VERSION ""

NS_ :

BS_:

BU_: Receiver ChassisBus VehicleBus PartyBus apb ui app aps bms gtwu odin cc cmp cp das dif dir di epas3p epas3s epbl epbr esp fc gtw hvp ibst ocs1p park pcs pmf pmr pm ptc radc rcm2 rcm sccm scm scs tas tpms umc vcfront vcleft vcright vcsec GTW

BO_ 12 ID00CUI_status: 8 VehicleBus
 SG_ UI_audioActive : 1|1@1+ (1,0) [0|1] ""  Receiver
 SG_ UI_autopilotTrial : 12|2@1+ (1,0) [0|3] ""  Receiver
 SG_ UI_bluetoothActive : 2|1@1+ (1,0) [0|1] ""  Receiver
 SG_ UI_cameraActive : 41|1@1+ (1,0) [0|1] ""  Receiver
 SG_ UI_cellActive : 3|1@1+ (1,0) [0|1] ""  Receiver
 SG_ UI_cellConnected : 10|1@1+ (1,0) [0|1] ""  Receiver
 SG_ UI_cellNetworkTechnology : 19|4@1+ (1,0) [0|15] ""  Receiver
 SG_ UI_cellReceiverPower : 24|8@1+ (1,-128) [-128|127] "dB"  Receiver
 SG_ UI_cellSignalBars : 42|3@1+ (1,0) [0|7] ""  Receiver
 SG_ UI_cpuTemperature : 56|8@1- (1,40) [-20|100] "C"  Receiver
 SG_ UI_developmentCar : 40|1@1+ (1,0) [0|1] ""  Receiver
 SG_ UI_displayOn : 5|1@1+ (1,0) [0|1] ""  Receiver
 SG_ UI_displayReady : 4|1@1+ (1,0) [0|1] ""  Receiver
 SG_ UI_factoryReset : 14|2@1+ (1,0) [0|3] ""  Receiver
 SG_ UI_falseTouchCounter : 32|8@1+ (1,0) [0|255] "1"  Receiver
 SG_ UI_gpsActive : 16|1@1+ (1,0) [0|1] ""  Receiver
 SG_ UI_pcbTemperature : 48|8@1- (1,40) [-20|100] "C"  Receiver
 SG_ UI_radioActive : 18|1@1+ (1,0) [0|1] ""  Receiver
 SG_ UI_readyForDrive : 9|1@1+ (1,0) [0|1] ""  Receiver
 SG_ UI_screenshotActive : 17|1@1+ (1,0) [0|1] ""  Receiver
 SG_ UI_systemActive : 8|1@1+ (1,0) [0|1] ""  Receiver
 SG_ UI_touchActive : 0|1@1+ (1,0) [0|1] ""  Receiver
 SG_ UI_vpnActive : 11|1@1+ (1,0) [0|1] ""  Receiver
 SG_ UI_wifiActive : 6|1@1+ (1,0) [0|1] ""  Receiver
 SG_ UI_wifiConnected : 7|1@1+ (1,0) [0|1] ""  Receiver

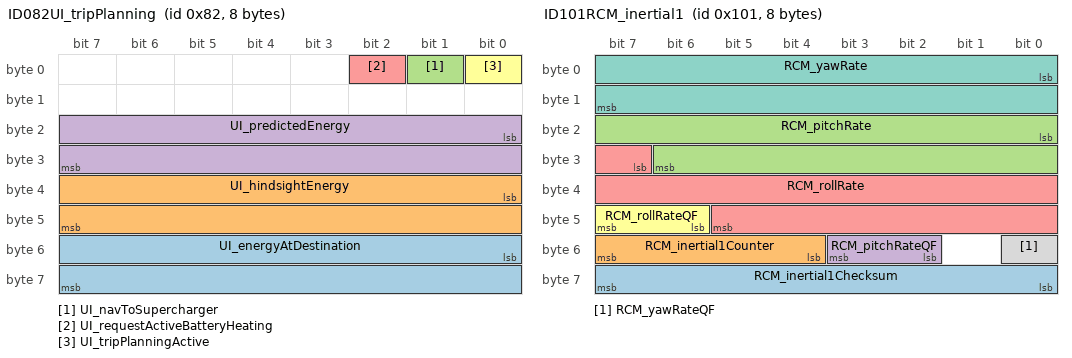
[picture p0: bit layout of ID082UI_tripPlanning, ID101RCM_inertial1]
BO_ 130 ID082UI_tripPlanning: 8 VehicleBus
 SG_ UI_energyAtDestination : 48|16@1- (0.01,0) [-327.67|327.67] "kWh"  Receiver
 SG_ UI_hindsightEnergy : 32|16@1- (0.01,0) [-327.67|327.67] "kWh"  Receiver
 SG_ UI_navToSupercharger : 1|1@1+ (1,0) [0|1] ""  Receiver
 SG_ UI_predictedEnergy : 16|16@1- (0.01,0) [-327.67|327.67] "kWh"  Receiver
 SG_ UI_requestActiveBatteryHeating : 2|1@1+ (1,0) [0|1] ""  Receiver
 SG_ UI_tripPlanningActive : 0|1@1+ (1,0) [0|1] ""  Receiver

BO_ 257 ID101RCM_inertial1: 8 ChassisBus
 SG_ RCM_inertial1Checksum : 56|8@1+ (1,0) [0|255] ""  Receiver
 SG_ RCM_inertial1Counter : 52|4@1+ (1,0) [0|15] ""  Receiver
 SG_ RCM_pitchRate : 16|15@1- (0.00025,0) [-4.096|4.09575] "rad/s"  Receiver
 SG_ RCM_pitchRateQF : 50|2@1+ (1,0) [0|3] ""  Receiver
 SG_ RCM_rollRate : 31|15@1- (0.00025,0) [-4.096|4.09575] "rad/s"  Receiver
 SG_ RCM_rollRateQF : 46|2@1+ (1,0) [0|3] ""  Receiver
 SG_ RCM_yawRate : 0|16@1- (0.0001,0) [-3.2766|3.2766] "rad/s"  Receiver
 SG_ RCM_yawRateQF : 48|1@1+ (1,0) [0|1] ""  Receiver

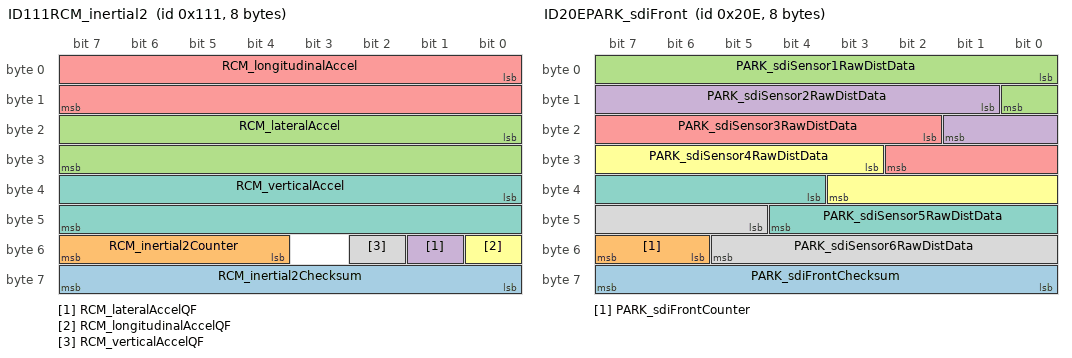
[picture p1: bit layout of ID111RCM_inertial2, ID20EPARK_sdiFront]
BO_ 273 ID111RCM_inertial2: 8 ChassisBus
 SG_ RCM_inertial2Checksum : 56|8@1+ (1,0) [0|255] ""  Receiver
 SG_ RCM_inertial2Counter : 52|4@1+ (1,0) [0|15] ""  Receiver
 SG_ RCM_lateralAccel : 16|16@1- (0.00125,0) [-40.9575|40.9575] "m/s^2"  Receiver
 SG_ RCM_lateralAccelQF : 49|1@1+ (1,0) [0|1] ""  Receiver
 SG_ RCM_longitudinalAccel : 0|16@1- (0.00125,0) [-40.9575|40.9575] "m/s^2"  Receiver
 SG_ RCM_longitudinalAccelQF : 48|1@1+ (1,0) [0|1] ""  Receiver
 SG_ RCM_verticalAccel : 32|16@1- (0.00125,0) [-40.9575|40.9575] "m/s^2"  Receiver
 SG_ RCM_verticalAccelQF : 50|1@1+ (1,0) [0|1] ""  Receiver

BO_ 258 ID102VCLEFT_doorStatus: 8 VehicleBus
 SG_ VCLEFT_frontHandlePWM : 16|7@1+ (1,0) [0|100] "%"  Receiver
 SG_ VCLEFT_frontHandlePulled : 10|1@1+ (1,0) [0|1] ""  Receiver
 SG_ VCLEFT_frontHandlePulledPersist : 62|1@1+ (1,0) [0|1] ""  Receiver
 SG_ VCLEFT_frontIntSwitchPressed : 31|1@1+ (1,0) [0|1] ""  Receiver
 SG_ VCLEFT_frontLatchStatus : 0|4@1+ (1,0) [0|8] ""  Receiver
 SG_ VCLEFT_frontLatchSwitch : 8|1@1+ (1,0) [0|1] ""  Receiver
 SG_ VCLEFT_frontRelActuatorSwitch : 12|1@1+ (1,0) [0|1] ""  Receiver
 SG_ VCLEFT_mirrorDipped : 61|1@1+ (1,0) [0|1] ""  Receiver
 SG_ VCLEFT_mirrorFoldState : 52|3@1+ (1,0) [0|4] ""  Receiver
 SG_ VCLEFT_mirrorHeatState : 58|3@1+ (1,0) [0|4] ""  Receiver
 SG_ VCLEFT_mirrorRecallState : 55|3@1+ (1,0) [0|5] ""  Receiver
 SG_ VCLEFT_mirrorState : 49|3@1+ (1,0) [0|4] ""  Receiver
 SG_ VCLEFT_mirrorTiltXPosition : 33|8@1+ (0.02,0) [0|5] "V"  Receiver
 SG_ VCLEFT_mirrorTiltYPosition : 41|8@1+ (0.02,0) [0|5] "V"  Receiver
 SG_ VCLEFT_rearHandlePWM : 24|7@1+ (1,0) [0|100] "%"  Receiver
 SG_ VCLEFT_rearHandlePulled : 11|1@1+ (1,0) [0|1] ""  Receiver
 SG_ VCLEFT_rearIntSwitchPressed : 32|1@1+ (1,0) [0|1] ""  Receiver
 SG_ VCLEFT_rearLatchStatus : 4|4@1+ (1,0) [0|8] ""  Receiver
 SG_ VCLEFT_rearLatchSwitch : 9|1@1+ (1,0) [0|1] ""  Receiver
 SG_ VCLEFT_rearRelActuatorSwitch : 13|1@1+ (1,0) [0|1] ""  Receiver

BO_ 259 ID103VCRIGHT_doorStatus: 8 VehicleBus
 SG_ VCRIGHT_frontHandlePWM : 14|7@1+ (1,0) [0|100] "%"  Receiver
 SG_ VCRIGHT_frontHandlePulled : 10|1@1+ (1,0) [0|1] ""  Receiver
 SG_ VCRIGHT_frontHandlePulledPersist : 30|1@1+ (1,0) [0|1] ""  Receiver
 SG_ VCRIGHT_frontIntSwitchPressed : 31|1@1+ (1,0) [0|1] ""  Receiver
 SG_ VCRIGHT_frontLatchStatus : 0|4@1+ (1,0) [0|8] ""  Receiver
 SG_ VCRIGHT_frontLatchSwitch : 8|1@1+ (1,0) [0|1] ""  Receiver
 SG_ VCRIGHT_frontRelActuatorSwitch : 12|1@1+ (1,0) [0|1] ""  Receiver
 SG_ VCRIGHT_mirrorDipped : 63|1@1+ (1,0) [0|1] ""  Receiver
 SG_ VCRIGHT_mirrorFoldState : 52|3@1+ (1,0) [0|4] ""  Receiver
 SG_ VCRIGHT_mirrorRecallState : 60|3@1+ (1,0) [0|5] ""  Receiver
 SG_ VCRIGHT_mirrorState : 49|3@1+ (1,0) [0|4] ""  Receiver
 SG_ VCRIGHT_mirrorTiltXPosition : 33|8@1+ (0.02,0) [0|5] "V"  Receiver
 SG_ VCRIGHT_mirrorTiltYPosition : 41|8@1+ (0.02,0) [0|5] "V"  Receiver
 SG_ VCRIGHT_rearHandlePWM : 21|7@1+ (1,0) [0|100] "%"  Receiver
 SG_ VCRIGHT_rearHandlePulled : 11|1@1+ (1,0) [0|1] ""  Receiver
 SG_ VCRIGHT_rearIntSwitchPressed : 32|1@1+ (1,0) [0|1] ""  Receiver
 SG_ VCRIGHT_rearLatchStatus : 4|4@1+ (1,0) [0|8] ""  Receiver
 SG_ VCRIGHT_rearLatchSwitch : 9|1@1+ (1,0) [0|1] ""  Receiver
 SG_ VCRIGHT_rearRelActuatorSwitch : 13|1@1+ (1,0) [0|1] ""  Receiver
 SG_ VCRIGHT_reservedForBackCompat : 28|2@1+ (1,0) [0|3] ""  Receiver
 SG_ VCRIGHT_trunkLatchStatus : 56|4@1+ (1,0) [0|8] ""  Receiver

BO_ 291 ID123UI_alertMatrix1: 8 VehicleBus
 SG_ UI_a001_DriverDoorOpen : 0|1@1+ (1,0) [0|1] ""  Receiver
 SG_ UI_a002_DoorOpen : 1|1@1+ (1,0) [0|1] ""  Receiver
 SG_ UI_a003_TrunkOpen : 2|1@1+ (1,0) [0|1] ""  Receiver
 SG_ UI_a004_FrunkOpen : 3|1@1+ (1,0) [0|1] ""  Receiver
 SG_ UI_a005_HeadlightsOnDoorOpen : 4|1@1+ (1,0) [0|1] ""  Receiver
 SG_ UI_a006_RemoteServiceAlert : 5|1@1+ (1,0) [0|1] ""  Receiver
 SG_ UI_a007_SoftPackConfigMismatch : 6|1@1+ (1,0) [0|1] ""  Receiver
 SG_ UI_a008_TouchScreenError : 7|1@1+ (1,0) [0|1] ""  Receiver
 SG_ UI_a009_SquashfsError : 8|1@1+ (1,0) [0|1] ""  Receiver
 SG_ UI_a010_MapsMissing : 9|1@1+ (1,0) [0|1] ""  Receiver
 SG_ UI_a011_IncorrectMap : 10|1@1+ (1,0) [0|1] ""  Receiver
 SG_ UI_a012_NotOnPrivateProperty : 11|1@1+ (1,0) [0|1] ""  Receiver
 SG_ UI_a013_TPMSHardWarning : 12|1@1+ (1,0) [0|1] ""  Receiver
 SG_ UI_a014_TPMSSoftWarning : 13|1@1+ (1,0) [0|1] ""  Receiver
 SG_ UI_a015_TPMSOverPressureWarning : 14|1@1+ (1,0) [0|1] ""  Receiver
 SG_ UI_a016_TPMSTemperatureWarning : 15|1@1+ (1,0) [0|1] ""  Receiver
 SG_ UI_a017_TPMSSystemFault : 16|1@1+ (1,0) [0|1] ""  Receiver
 SG_ UI_a018_SlipStartOn : 17|1@1+ (1,0) [0|1] ""  Receiver
 SG_ UI_a019_ParkBrakeFault : 18|1@1+ (1,0) [0|1] ""  Receiver
 SG_ UI_a020_SteeringReduced : 19|1@1+ (1,0) [0|1] ""  Receiver
 SG_ UI_a021_RearSeatbeltUnbuckled : 20|1@1+ (1,0) [0|1] ""  Receiver
 SG_ UI_a022_ApeFusesEtc : 21|1@1+ (1,0) [0|1] ""  Receiver
 SG_ UI_a023_CellInternetCheckFailed : 22|1@1+ (1,0) [0|1] ""  Receiver
 SG_ UI_a024_WifiInternetCheckFailed : 23|1@1+ (1,0) [0|1] ""  Receiver
 SG_ UI_a025_WifiOnlineCheckFailed : 24|1@1+ (1,0) [0|1] ""  Receiver
 SG_ UI_a026_ModemResetLoopDetected : 25|1@1+ (1,0) [0|1] ""  Receiver
 SG_ UI_a027_AutoSteerMIA : 26|1@1+ (1,0) [0|1] ""  Receiver
 SG_ UI_a028_FrontTrunkPopupClosed : 27|1@1+ (1,0) [0|1] ""  Receiver
 SG_ UI_a029_ModemMIA : 28|1@1+ (1,0) [0|1] ""  Receiver
 SG_ UI_a030_ModemVMCrash : 29|1@1+ (1,0) [0|1] ""  Receiver
 SG_ UI_a031_BrakeFluidLow : 30|1@1+ (1,0) [0|1] ""  Receiver
 SG_ UI_a032_CellModemRecoveryResets : 31|1@1+ (1,0) [0|1] ""  Receiver
 SG_ UI_a033_ApTrialExpired : 32|1@1+ (1,0) [0|1] ""  Receiver
 SG_ UI_a034_WakeupProblem : 33|1@1+ (1,0) [0|1] ""  Receiver
 SG_ UI_a035_AudioWatchdogKernelError : 34|1@1+ (1,0) [0|1] ""  Receiver
 SG_ UI_a036_AudioWatchdogHfpError : 35|1@1+ (1,0) [0|1] ""  Receiver
 SG_ UI_a037_AudioWatchdogXrunStormEr : 36|1@1+ (1,0) [0|1] ""  Receiver
 SG_ UI_a038_AudioWatchdogA2bI2cLocku : 37|1@1+ (1,0) [0|1] ""  Receiver
 SG_ UI_a039_AudioA2bNeedRediscovery : 38|1@1+ (1,0) [0|1] ""  Receiver
 SG_ UI_a040_HomelinkTransmit : 39|1@1+ (1,0) [0|1] ""  Receiver
 SG_ UI_a041_AudioDmesgXrun : 40|1@1+ (1,0) [0|1] ""  Receiver
 SG_ UI_a042_AudioDmesgRtThrottling : 41|1@1+ (1,0) [0|1] ""  Receiver
 SG_ UI_a043_InvalidMapDataOverride : 42|1@1+ (1,0) [0|1] ""  Receiver
 SG_ UI_a044_AudioDmesgDspException : 43|1@1+ (1,0) [0|1] ""  Receiver
 SG_ UI_a045_ECallNeedsService : 44|1@1+ (1,0) [0|1] ""  Receiver
 SG_ UI_a046_BackupCameraStreamError : 45|1@1+ (1,0) [0|1] ""  Receiver
 SG_ UI_a047_CellRoamingDisallowed : 46|1@1+ (1,0) [0|1] ""  Receiver
 SG_ UI_a048_AudioPremiumAmpCheckFail : 47|1@1+ (1,0) [0|1] ""  Receiver
 SG_ UI_a049_BrakeShiftRequired : 48|1@1+ (1,0) [0|1] ""  Receiver
 SG_ UI_a050_BackupCameraIPUTimeout : 49|1@1+ (1,0) [0|1] ""  Receiver
 SG_ UI_a051_BackupCameraFrameTimeout : 50|1@1+ (1,0) [0|1] ""  Receiver
 SG_ UI_a052_KernelPanicReported : 51|1@1+ (1,0) [0|1] ""  Receiver
 SG_ UI_a053_QtCarExitError : 52|1@1+ (1,0) [0|1] ""  Receiver
 SG_ UI_a054_AudioBoostPowerBad : 53|1@1+ (1,0) [0|1] ""  Receiver
 SG_ UI_a055_ManualECallDisabled : 54|1@1+ (1,0) [0|1] ""  Receiver
 SG_ UI_a056_ManualECallButtonDisconn : 55|1@1+ (1,0) [0|1] ""  Receiver
 SG_ UI_a057_CellAntennaDisconnected : 56|1@1+ (1,0) [0|1] ""  Receiver
 SG_ UI_a058_GPSAntennaDisconnected : 57|1@1+ (1,0) [0|1] ""  Receiver
 SG_ UI_a059_ECallSpeakerDisconnected : 58|1@1+ (1,0) [0|1] ""  Receiver
 SG_ UI_a060_ECallMicDisconnected : 59|1@1+ (1,0) [0|1] ""  Receiver
 SG_ UI_a061_SIMTestFailed : 60|1@1+ (1,0) [0|1] ""  Receiver
 SG_ UI_a062_ENSTestFailed : 61|1@1+ (1,0) [0|1] ""  Receiver
 SG_ UI_a063_CellularTestFailed : 62|1@1+ (1,0) [0|1] ""  Receiver
 SG_ UI_a064_ModemFirmwareTestFailed : 63|1@1+ (1,0) [0|1] ""  Receiver

BO_ 322 ID142VCLEFT_liftgateStatus: 8 VehicleBus
 SG_ VCLEFT_liftgateStatusIndex M : 0|2@1+ (1,0) [0|2] ""  Receiver
 SG_ VCLEFT_liftgateLatchRequest m0 : 61|3@1+ (1,0) [0|4] ""  Receiver
 SG_ VCLEFT_liftgateMvmntNotAllowedCo m0 : 14|3@1+ (1,0) [0|5] ""  Receiver
 SG_ VCLEFT_liftgatePhysicalChimeRequ m0 : 21|3@1+ (1,0) [0|4] ""  Receiver
 SG_ VCLEFT_liftgatePosition m1 : 21|7@1- (1,33) [-5|70] "deg"  Receiver
 SG_ VCLEFT_liftgatePositionCalibrate m0 : 17|1@1+ (1,0) [0|1] ""  Receiver
 SG_ VCLEFT_liftgateRequestSource m0 : 7|3@1+ (1,0) [0|7] ""  Receiver
 SG_ VCLEFT_liftgateSpeed m1 : 28|10@1- (0.1,0) [-30|30] "deg/s"  Receiver
 SG_ VCLEFT_liftgateState m0 : 3|4@1+ (1,0) [0|12] ""  Receiver
 SG_ VCLEFT_liftgateStoppingCondition m0 : 10|4@1+ (1,0) [0|11] ""  Receiver
 SG_ VCLEFT_liftgateStrutCurrent m1 : 11|10@1- (0.1,0) [-30|30] "A"  Receiver
 SG_ VCLEFT_liftgateStrutDutyCycle m1 : 3|8@1- (1,0) [-100|100] "%"  Receiver
 SG_ VCLEFT_liftgateUIChimeRequest m0 : 18|3@1+ (1,0) [0|4] ""  Receiver

BO_ 325 ID145ESP_status: 8 ChassisBus
 SG_ ESP_absBrakeEvent2 : 22|2@1+ (1,0) [0|3] ""  Receiver
 SG_ ESP_absFaultLamp : 17|1@1+ (1,0) [0|1] ""  Receiver
 SG_ ESP_brakeApply : 31|1@1+ (1,0) [0|1] ""  Receiver
 SG_ ESP_brakeDiscWipingActive : 28|1@1+ (1,0) [0|1] ""  Receiver
 SG_ ESP_brakeLamp : 21|1@1+ (1,0) [0|1] ""  Receiver
 SG_ ESP_brakeTorqueTarget : 51|13@1+ (2,0) [0|16382] "Nm"  Receiver
 SG_ ESP_btcTargetState : 38|2@1+ (1,0) [0|3] ""  Receiver
 SG_ ESP_cdpStatus : 34|2@1+ (1,0) [0|3] ""  Receiver
 SG_ ESP_driverBrakeApply : 29|2@1+ (1,0) [0|3] ""  Receiver
 SG_ ESP_ebdFaultLamp : 16|1@1+ (1,0) [0|1] ""  Receiver
 SG_ ESP_ebrStandstillSkid : 48|1@1+ (1,0) [0|1] ""  Receiver
 SG_ ESP_ebrStatus : 49|2@1+ (1,0) [0|3] ""  Receiver
 SG_ ESP_espFaultLamp : 18|1@1+ (1,0) [0|1] ""  Receiver
 SG_ ESP_espLampFlash : 20|1@1+ (1,0) [0|1] ""  Receiver
 SG_ ESP_espModeActive : 12|2@1+ (1,0) [0|3] ""  Receiver
 SG_ ESP_hydraulicBoostEnabled : 19|1@1+ (1,0) [0|1] ""  Receiver
 SG_ ESP_lateralAccelQF : 25|1@1+ (1,0) [0|1] ""  Receiver
 SG_ ESP_longitudinalAccelQF : 24|1@1+ (1,0) [0|1] ""  Receiver
 SG_ ESP_ptcTargetState : 36|2@1+ (1,0) [0|3] ""  Receiver
 SG_ ESP_stabilityControlSts2 : 14|2@1+ (1,0) [0|3] ""  Receiver
 SG_ ESP_statusChecksum : 0|8@1+ (1,0) [0|255] ""  Receiver
 SG_ ESP_statusCounter : 8|4@1+ (1,0) [0|15] ""  Receiver
 SG_ ESP_steeringAngleQF : 27|1@1+ (1,0) [0|1] ""  Receiver
 SG_ ESP_yawRateQF : 26|1@1+ (1,0) [0|1] ""  Receiver

BO_ 522 ID20AHVP_contactorState: 6 VehicleBus
 SG_ HVP_dcLinkAllowedToEnergize : 36|1@1+ (1,0) [0|1] ""  Receiver
 SG_ HVP_fcContNegativeAuxOpen : 7|1@1+ (1,0) [0|1] ""  Receiver
 SG_ HVP_fcContNegativeState : 12|3@1+ (1,0) [0|7] ""  Receiver
 SG_ HVP_fcContPositiveAuxOpen : 6|1@1+ (1,0) [0|1] ""  Receiver
 SG_ HVP_fcContPositiveState : 16|3@1+ (1,0) [0|7] ""  Receiver
 SG_ HVP_fcContactorSetState : 19|4@1+ (1,0) [0|9] ""  Receiver
 SG_ HVP_fcCtrsClosingAllowed : 29|1@1+ (1,0) [0|1] ""  Receiver
 SG_ HVP_fcCtrsOpenNowRequested : 27|1@1+ (1,0) [0|1] ""  Receiver
 SG_ HVP_fcCtrsOpenRequested : 28|1@1+ (1,0) [0|1] ""  Receiver
 SG_ HVP_fcCtrsRequestStatus : 24|2@1+ (1,0) [0|2] ""  Receiver
 SG_ HVP_fcCtrsResetRequestRequired : 26|1@1+ (1,0) [0|1] ""  Receiver
 SG_ HVP_fcLinkAllowedToEnergize : 44|2@1+ (1,0) [0|2] ""  Receiver
 SG_ HVP_hvilStatus : 40|4@1+ (1,0) [0|9] ""  Receiver
 SG_ HVP_packContNegativeState : 0|3@1+ (1,0) [0|7] ""  Receiver
 SG_ HVP_packContPositiveState : 3|3@1+ (1,0) [0|7] ""  Receiver
 SG_ HVP_packContactorSetState : 8|4@1+ (1,0) [0|9] ""  Receiver
 SG_ HVP_packCtrsClosingAllowed : 35|1@1+ (1,0) [0|1] ""  Receiver
 SG_ HVP_packCtrsOpenNowRequested : 33|1@1+ (1,0) [0|1] ""  Receiver
 SG_ HVP_packCtrsOpenRequested : 34|1@1+ (1,0) [0|1] ""  Receiver
 SG_ HVP_packCtrsRequestStatus : 30|2@1+ (1,0) [0|2] ""  Receiver
 SG_ HVP_packCtrsResetRequestRequired : 32|1@1+ (1,0) [0|1] ""  Receiver
 SG_ HVP_pyroTestInProgress : 37|1@1+ (1,0) [0|1] ""  Receiver

BO_ 526 ID20EPARK_sdiFront: 8 ChassisBus
 SG_ PARK_sdiFrontChecksum : 56|8@1+ (1,0) [0|255] ""  Receiver
 SG_ PARK_sdiFrontCounter : 54|2@1+ (1,0) [0|3] ""  Receiver
 SG_ PARK_sdiSensor1RawDistData : 0|9@1+ (1,0) [0|511] "cm"  Receiver
 SG_ PARK_sdiSensor2RawDistData : 9|9@1+ (1,0) [0|511] "cm"  Receiver
 SG_ PARK_sdiSensor3RawDistData : 18|9@1+ (1,0) [0|511] "cm"  Receiver
 SG_ PARK_sdiSensor4RawDistData : 27|9@1+ (1,0) [0|511] "cm"  Receiver
 SG_ PARK_sdiSensor5RawDistData : 36|9@1+ (1,0) [0|511] "cm"  Receiver
 SG_ PARK_sdiSensor6RawDistData : 45|9@1+ (1,0) [0|511] "cm"  Receiver

BO_ 537 ID219VCSEC_TPMSData: 5 ChassisBus
 SG_ VCSEC_TPMSDataIndex M : 0|2@1+ (1,0) [0|3] ""  Receiver
 SG_ VCSEC_TPMSBatVoltage0 m0 : 24|8@1+ (0.01,1.5) [1.5|4.04] "V"  Receiver
 SG_ VCSEC_TPMSBatVoltage1 m1 : 24|8@1+ (0.01,1.5) [1.5|4.04] "V"  Receiver
 SG_ VCSEC_TPMSBatVoltage2 m2 : 24|8@1+ (0.01,1.5) [1.5|4.04] "V"  Receiver
 SG_ VCSEC_TPMSBatVoltage3 m3 : 24|8@1+ (0.01,1.5) [1.5|4.04] "V"  Receiver
 SG_ VCSEC_TPMSLocation0 m0 : 32|3@1+ (1,0) [0|4] ""  Receiver
 SG_ VCSEC_TPMSLocation1 m1 : 32|3@1+ (1,0) [0|4] ""  Receiver
 SG_ VCSEC_TPMSLocation2 m2 : 32|3@1+ (1,0) [0|4] ""  Receiver
 SG_ VCSEC_TPMSLocation3 m3 : 32|3@1+ (1,0) [0|4] ""  Receiver
 SG_ VCSEC_TPMSPressure0 m0 : 8|8@1+ (0.025,0) [0|6.35] "bar"  Receiver
 SG_ VCSEC_TPMSPressure1 m1 : 8|8@1+ (0.025,0) [0|6.35] "bar"  Receiver
 SG_ VCSEC_TPMSPressure2 m2 : 8|8@1+ (0.025,0) [0|6.35] "bar"  Receiver
 SG_ VCSEC_TPMSPressure3 m3 : 8|8@1+ (0.025,0) [0|6.35] "bar"  Receiver
 SG_ VCSEC_TPMSTemperature0 m0 : 16|8@1+ (1,-40) [-40|214] "C"  Receiver
 SG_ VCSEC_TPMSTemperature1 m1 : 16|8@1+ (1,-40) [-40|214] "C"  Receiver
 SG_ VCSEC_TPMSTemperature2 m2 : 16|8@1+ (1,-40) [-40|214] "C"  Receiver
 SG_ VCSEC_TPMSTemperature3 m3 : 16|8@1+ (1,-40) [-40|214] "C"  Receiver

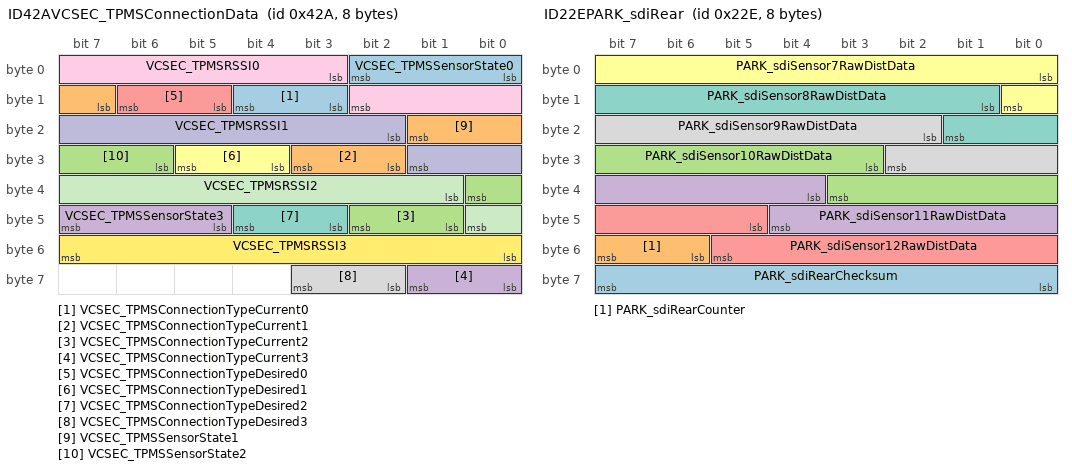
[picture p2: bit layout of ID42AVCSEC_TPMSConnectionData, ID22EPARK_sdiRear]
BO_ 1066 ID42AVCSEC_TPMSConnectionData: 8 VehicleBus
 SG_ VCSEC_TPMSConnectionTypeCurrent0 : 11|2@1+ (1,0) [0|2] ""  Receiver
 SG_ VCSEC_TPMSConnectionTypeCurrent1 : 26|2@1+ (1,0) [0|2] ""  Receiver
 SG_ VCSEC_TPMSConnectionTypeCurrent2 : 41|2@1+ (1,0) [0|2] ""  Receiver
 SG_ VCSEC_TPMSConnectionTypeCurrent3 : 56|2@1+ (1,0) [0|2] ""  Receiver
 SG_ VCSEC_TPMSConnectionTypeDesired0 : 13|2@1+ (1,0) [0|2] ""  Receiver
 SG_ VCSEC_TPMSConnectionTypeDesired1 : 28|2@1+ (1,0) [0|2] ""  Receiver
 SG_ VCSEC_TPMSConnectionTypeDesired2 : 43|2@1+ (1,0) [0|2] ""  Receiver
 SG_ VCSEC_TPMSConnectionTypeDesired3 : 58|2@1+ (1,0) [0|2] ""  Receiver
 SG_ VCSEC_TPMSRSSI0 : 3|8@1- (1,0) [-127|0] "dBm"  Receiver
 SG_ VCSEC_TPMSRSSI1 : 18|8@1- (1,0) [-127|0] "dBm"  Receiver
 SG_ VCSEC_TPMSRSSI2 : 33|8@1- (1,0) [-127|0] "dBm"  Receiver
 SG_ VCSEC_TPMSRSSI3 : 48|8@1- (1,0) [-127|0] "dBm"  Receiver
 SG_ VCSEC_TPMSSensorState0 : 0|3@1+ (1,0) [0|4] ""  Receiver
 SG_ VCSEC_TPMSSensorState1 : 15|3@1+ (1,0) [0|4] ""  Receiver
 SG_ VCSEC_TPMSSensorState2 : 30|3@1+ (1,0) [0|4] ""  Receiver
 SG_ VCSEC_TPMSSensorState3 : 45|3@1+ (1,0) [0|4] ""  Receiver

BO_ 558 ID22EPARK_sdiRear: 8 VehicleBus
 SG_ PARK_sdiRearChecksum : 56|8@1+ (1,0) [0|255] ""  Receiver
 SG_ PARK_sdiRearCounter : 54|2@1+ (1,0) [0|3] ""  Receiver
 SG_ PARK_sdiSensor10RawDistData : 27|9@1+ (1,0) [0|511] "cm"  Receiver
 SG_ PARK_sdiSensor11RawDistData : 36|9@1+ (1,0) [0|511] "cm"  Receiver
 SG_ PARK_sdiSensor12RawDistData : 45|9@1+ (1,0) [0|511] "cm"  Receiver
 SG_ PARK_sdiSensor7RawDistData : 0|9@1+ (1,0) [0|511] "cm"  Receiver
 SG_ PARK_sdiSensor8RawDistData : 9|9@1+ (1,0) [0|511] "cm"  Receiver
 SG_ PARK_sdiSensor9RawDistData : 18|9@1+ (1,0) [0|511] "cm"  Receiver

BO_ 568 ID238UI_driverAssistMapData: 8 ChassisBus
 SG_ UI_acceptBottsDots : 48|1@1+ (1,0) [0|1] ""  Receiver
 SG_ UI_autosteerRestricted : 49|1@1+ (1,0) [0|1] ""  Receiver
 SG_ UI_controlledAccess : 37|1@1+ (1,0) [0|1] ""  Receiver
 SG_ UI_countryCode : 16|10@1+ (1,0) [0|1023] ""  Receiver
 SG_ UI_gpsRoadMatch : 28|1@1+ (1,0) [0|1] ""  Receiver
 SG_ UI_inSuperchargerGeofence : 6|1@1+ (1,0) [0|1] ""  Receiver
 SG_ UI_mapDataChecksum : 56|8@1+ (1,0) [0|255] ""  Receiver
 SG_ UI_mapDataCounter : 52|4@1+ (1,0) [0|15] ""  Receiver
 SG_ UI_mapSpeedLimit : 8|5@1+ (1,0) [0|31] ""  Receiver
 SG_ UI_mapSpeedLimitDependency : 0|3@1+ (1,0) [0|7] ""  Receiver
 SG_ UI_mapSpeedLimitType : 13|3@1+ (1,0) [0|7] ""  Receiver
 SG_ UI_mapSpeedUnits : 7|1@1+ (1,0) [0|1] ""  Receiver
 SG_ UI_navRouteActive : 29|1@1+ (1,0) [0|1] ""  Receiver
 SG_ UI_nextBranchDist : 32|5@1+ (10,0) [0|300] "m"  Receiver
 SG_ UI_nextBranchLeftOffRamp : 38|1@1+ (1,0) [0|1] ""  Receiver
 SG_ UI_nextBranchRightOffRamp : 39|1@1+ (1,0) [0|1] ""  Receiver
 SG_ UI_parallelAutoparkEnabled : 30|1@1+ (1,0) [0|1] ""  Receiver
 SG_ UI_perpendicularAutoparkEnabled : 31|1@1+ (1,0) [0|1] ""  Receiver
 SG_ UI_pmmEnabled : 50|1@1+ (1,0) [0|1] ""  Receiver
 SG_ UI_rejectAutosteer : 46|1@1+ (1,0) [0|1] ""  Receiver
 SG_ UI_rejectHPP : 42|1@1+ (1,0) [0|1] ""  Receiver
 SG_ UI_rejectHandsOn : 47|1@1+ (1,0) [0|1] ""  Receiver
 SG_ UI_rejectLeftFreeSpace : 44|1@1+ (1,0) [0|1] ""  Receiver
 SG_ UI_rejectLeftLane : 40|1@1+ (1,0) [0|1] ""  Receiver
 SG_ UI_rejectNav : 43|1@1+ (1,0) [0|1] ""  Receiver
 SG_ UI_rejectRightFreeSpace : 45|1@1+ (1,0) [0|1] ""  Receiver
 SG_ UI_rejectRightLane : 41|1@1+ (1,0) [0|1] ""  Receiver
 SG_ UI_roadClass : 3|3@1+ (1,0) [0|6] ""  Receiver
 SG_ UI_scaEnabled : 51|1@1+ (1,0) [0|1] ""  Receiver
 SG_ UI_streetCount : 26|2@1+ (1,0) [0|3] ""  Receiver

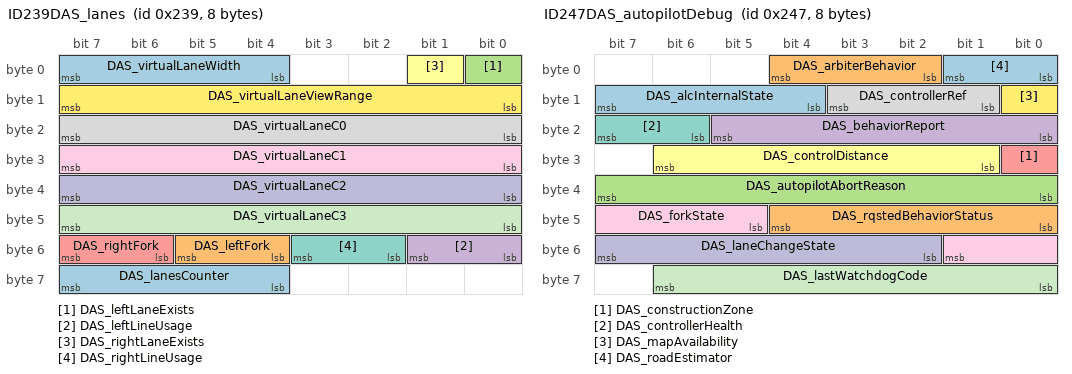
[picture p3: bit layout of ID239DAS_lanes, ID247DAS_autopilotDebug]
BO_ 569 ID239DAS_lanes: 8 ChassisBus
 SG_ DAS_lanesCounter : 60|4@1+ (1,0) [0|15] ""  Receiver
 SG_ DAS_leftFork : 52|2@1+ (1,0) [0|3] ""  Receiver
 SG_ DAS_leftLaneExists : 0|1@1+ (1,0) [0|1] ""  Receiver
 SG_ DAS_leftLineUsage : 48|2@1+ (1,0) [0|3] ""  Receiver
 SG_ DAS_rightFork : 54|2@1+ (1,0) [0|3] ""  Receiver
 SG_ DAS_rightLaneExists : 1|1@1+ (1,0) [0|1] ""  Receiver
 SG_ DAS_rightLineUsage : 50|2@1+ (1,0) [0|3] ""  Receiver
 SG_ DAS_virtualLaneC0 : 16|8@1+ (0.035,-3.5) [-3.5|3.5] "m"  Receiver
 SG_ DAS_virtualLaneC1 : 24|8@1+ (0.0016,-0.2) [-0.2|0.2] "rad"  Receiver
 SG_ DAS_virtualLaneC2 : 32|8@1+ (2E-005,-0.0025) [-0.0025|0.0025] "m-1"  Receiver
 SG_ DAS_virtualLaneC3 : 40|8@1+ (2.4E-007,-3E-005) [-3E-005|3E-005] "m-2"  Receiver
 SG_ DAS_virtualLaneViewRange : 8|8@1+ (1,0) [0|160] "m"  Receiver
 SG_ DAS_virtualLaneWidth : 4|4@1+ (0.3125,2) [2|6.6875] "m"  Receiver

BO_ 583 ID247DAS_autopilotDebug: 8 VehicleBus
 SG_ DAS_alcInternalState : 12|4@1+ (1,0) [0|12] ""  Receiver
 SG_ DAS_arbiterBehavior : 2|3@1+ (1,0) [0|4] ""  Receiver
 SG_ DAS_autopilotAbortReason : 32|8@1+ (1,0) [0|255] ""  Receiver
 SG_ DAS_behaviorReport : 16|6@1+ (1,0) [1|43] ""  Receiver
 SG_ DAS_constructionZone : 24|1@1+ (1,0) [0|1] ""  Receiver
 SG_ DAS_controlDistance : 25|6@1+ (2,0) [0|126] "m"  Receiver
 SG_ DAS_controllerHealth : 22|2@1+ (1,0) [0|3] ""  Receiver
 SG_ DAS_controllerRef : 9|3@1+ (1,0) [0|6] ""  Receiver
 SG_ DAS_forkState : 45|5@1+ (1,0) [0|27] ""  Receiver
 SG_ DAS_laneChangeState : 50|6@1+ (1,0) [0|63] ""  Receiver
 SG_ DAS_lastWatchdogCode : 56|7@1+ (1,0) [0|80] ""  Receiver
 SG_ DAS_mapAvailability : 8|1@1+ (1,0) [0|1] ""  Receiver
 SG_ DAS_roadEstimator : 0|2@1+ (1,0) [0|3] ""  Receiver
 SG_ DAS_rqstedBehaviorStatus : 40|5@1+ (1,0) [0|22] ""  Receiver

BO_ 586 ID24ADAS_visualDebug: 8 ChassisBus
 SG_ DAS_accSmartSpeedActive : 48|1@1+ (1,0) [0|1] ""  Receiver
 SG_ DAS_accSmartSpeedState : 49|3@1+ (1,0) [0|7] ""  Receiver
 SG_ DAS_autosteerBottsDotsUsage : 12|2@1+ (1,0) [0|3] ""  Receiver
 SG_ DAS_autosteerHPPUsage : 6|2@1+ (1,0) [0|3] ""  Receiver
 SG_ DAS_autosteerHealthAnomalyLevel : 18|3@1+ (1,0) [0|7] ""  Receiver
 SG_ DAS_autosteerHealthState : 21|3@1+ (1,0) [0|5] ""  Receiver
 SG_ DAS_autosteerModelUsage : 10|2@1+ (1,0) [0|3] ""  Receiver
 SG_ DAS_autosteerNavigationUsage : 8|2@1+ (1,0) [0|3] ""  Receiver
 SG_ DAS_autosteerVehiclesUsage : 4|2@1+ (1,0) [0|3] ""  Receiver
 SG_ DAS_behaviorType : 56|2@1+ (1,0) [0|3] ""  Receiver
 SG_ DAS_devAppInterfaceEnabled : 38|1@1+ (1,0) [0|1] ""  Receiver
 SG_ DAS_lastAutosteerAbortReason : 32|6@1+ (1,0) [0|34] ""  Receiver
 SG_ DAS_lastLinePreferenceReason : 24|4@1+ (1,0) [0|15] ""  Receiver
 SG_ DAS_navAvailable : 39|1@1+ (1,0) [0|1] ""  Receiver
 SG_ DAS_navDistance : 40|8@1+ (100,0) [0|25500] "km"  Receiver
 SG_ DAS_offsetSide : 14|2@1+ (1,0) [0|3] ""  Receiver
 SG_ DAS_plannerState : 28|4@1+ (1,0) [0|7] ""  Receiver
 SG_ DAS_rearLeftVehDetectedCurrent : 61|1@1+ (1,0) [0|1] ""  Receiver
 SG_ DAS_rearLeftVehDetectedTrip : 63|1@1+ (1,0) [0|1] ""  Receiver
 SG_ DAS_rearRightVehDetectedTrip : 62|1@1+ (1,0) [0|1] ""  Receiver
 SG_ DAS_rearVehDetectedThisCycle : 60|1@1+ (1,0) [0|1] ""  Receiver
 SG_ DAS_roadSurfaceType : 16|2@1+ (1,0) [0|2] ""  Receiver
 SG_ DAS_ulcInProgress : 52|1@1+ (1,0) [0|1] ""  Receiver
 SG_ DAS_ulcType : 58|2@1+ (1,0) [0|2] ""  Receiver

BO_ 603 ID25BAPP_environment: 1 ChassisBus
 SG_ APP_environmentRainy : 0|1@1+ (1,0) [0|1] ""  Receiver
 SG_ APP_environmentSnowy : 1|1@1+ (1,0) [0|1] ""  Receiver

BO_ 605 ID25DCP_status: 8 VehicleBus
 SG_ CP_UHF_controlState : 38|4@1+ (1,0) [0|10] ""  Receiver
 SG_ CP_UHF_handleFound : 42|1@1+ (1,0) [0|1] ""  Receiver
 SG_ CP_apsVoltage : 24|8@1+ (0.0715686,0) [0|18.249] "V" Vector__XXX
 SG_ CP_chargeCablePresent : 3|1@1+ (1,0) [0|1] ""  odin
 SG_ CP_chargeCableSecured : 4|1@1+ (1,0) [0|1] ""  Receiver
 SG_ CP_chargeCableState : 14|2@1+ (1,0) [0|2] ""  Receiver
 SG_ CP_chargeDoorOpen : 10|1@1+ (1,0) [0|1] ""  Receiver
 SG_ CP_chargeDoorOpenUI : 51|1@1+ (1,0) [0|1] ""  Receiver
 SG_ CP_coldWeatherMode : 60|1@1+ (1,0) [0|1] ""  Receiver
 SG_ CP_coverClosed : 63|1@1+ (1,0) [0|1] ""  Receiver
 SG_ CP_doorButtonPressed : 32|1@1+ (1,0) [0|1] ""  Receiver
 SG_ CP_doorControlState : 11|3@1+ (1,0) [0|6] ""  Receiver
 SG_ CP_doorOpenRequested : 43|1@1+ (1,0) [0|1] ""  Receiver
 SG_ CP_faultLineSensed : 44|1@1+ (1,0) [0|1] ""  Receiver
 SG_ CP_hvInletExposed : 61|1@1+ (1,0) [0|1] ""  Receiver
 SG_ CP_inductiveDoorState : 45|3@1+ (1,0) [0|7] ""  Receiver
 SG_ CP_inductiveSensorState : 48|3@1+ (1,0) [0|7] ""  Receiver
 SG_ CP_insertEnableLine : 2|1@1+ (1,0) [0|1] ""  Receiver
 SG_ CP_latch2ControlState : 19|3@1+ (1,0) [0|5] ""  Receiver
 SG_ CP_latch2State : 8|2@1+ (1,0) [0|3] ""  Receiver
 SG_ CP_latchControlState : 16|3@1+ (1,0) [0|5] ""  Receiver
 SG_ CP_latchEngaged : 62|1@1+ (1,0) [0|1] ""  Receiver
 SG_ CP_latchState : 5|2@1+ (1,0) [0|3] ""  Receiver
 SG_ CP_ledColor : 33|4@1+ (1,0) [0|10] ""  Receiver
 SG_ CP_numAlertsSet : 53|7@1+ (1,0) [0|127] ""  Receiver
 SG_ CP_permanentPowerRequest : 7|1@1+ (1,0) [0|1] ""  Receiver
 SG_ CP_swcanRelayClosed : 37|1@1+ (1,0) [0|1] ""  Receiver
 SG_ CP_type : 0|2@1+ (1,0) [0|3] ""  Receiver
 SG_ CP_vehicleUnlockRequest : 52|1@1+ (1,0) [0|1] ""  Receiver

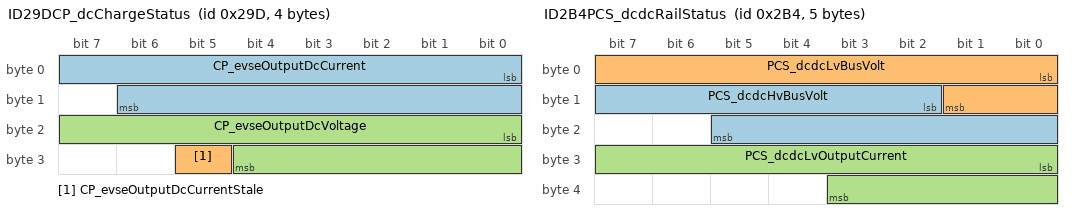
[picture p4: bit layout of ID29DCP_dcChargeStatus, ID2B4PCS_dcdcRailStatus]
BO_ 669 ID29DCP_dcChargeStatus: 4 VehicleBus
 SG_ CP_evseOutputDcCurrent : 0|15@1- (0.0732467,0) [-1200|1200] "A"  Receiver
 SG_ CP_evseOutputDcCurrentStale : 29|1@1+ (1,0) [0|1] ""  Receiver
 SG_ CP_evseOutputDcVoltage : 16|13@1+ (0.0732422,0) [0|599.927] "V"  Receiver

BO_ 692 ID2B4PCS_dcdcRailStatus: 5 VehicleBus
 SG_ PCS_dcdcHvBusVolt : 10|12@1+ (0.146484375,0) [0|599.853515625] "V"  Receiver
 SG_ PCS_dcdcLvBusVolt : 0|10@1+ (0.0390625,0) [0|39.9609375] "V"  Receiver
 SG_ PCS_dcdcLvOutputCurrent : 24|12@1+ (0.1,0) [0|400] "A"  Receiver

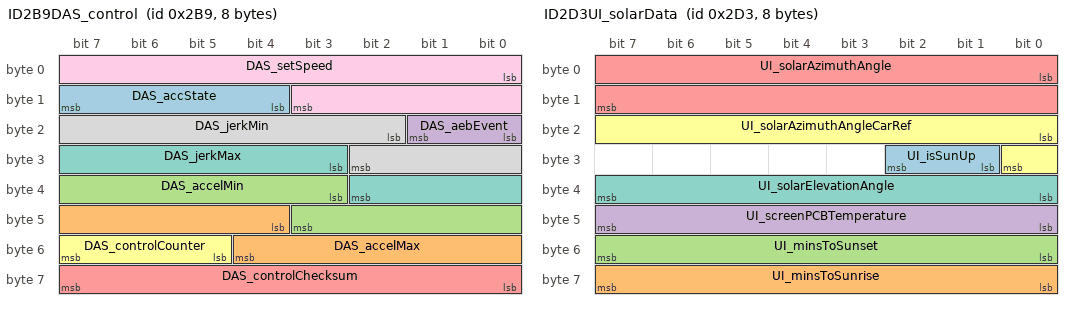
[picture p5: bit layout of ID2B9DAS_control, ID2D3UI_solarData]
BO_ 697 ID2B9DAS_control: 8 ChassisBus
 SG_ DAS_accState : 12|4@1+ (1,0) [0|15] ""  Receiver
 SG_ DAS_accelMax : 44|9@1+ (0.04,-15) [-15|5.44] "m/s^2"  Receiver
 SG_ DAS_accelMin : 35|9@1+ (0.04,-15) [-15|5.44] "m/s^2"  Receiver
 SG_ DAS_aebEvent : 16|2@1+ (1,0) [0|3] ""  Receiver
 SG_ DAS_controlChecksum : 56|8@1+ (1,0) [0|255] ""  Receiver
 SG_ DAS_controlCounter : 53|3@1+ (1,0) [0|7] ""  Receiver
 SG_ DAS_jerkMax : 27|8@1+ (0.059,0) [0|15.045] "m/s^3"  Receiver
 SG_ DAS_jerkMin : 18|9@1+ (0.03,-15.232) [-15.232|0.098] "m/s^3"  Receiver
 SG_ DAS_setSpeed : 0|12@1+ (0.1,0) [0|409.4] "kph"  Receiver

BO_ 723 ID2D3UI_solarData: 8 ChassisBus
 SG_ UI_isSunUp : 25|2@1+ (1,0) [0|3] ""  Receiver
 SG_ UI_minsToSunrise : 56|8@1+ (10,0) [0|2550] "min"  Receiver
 SG_ UI_minsToSunset : 48|8@1+ (10,0) [0|2550] "min"  Receiver
 SG_ UI_screenPCBTemperature : 40|8@1- (0.5,40) [-20|100] "C"  Receiver
 SG_ UI_solarAzimuthAngle : 0|16@1- (1,0) [-32767|32767] "deg"  Receiver
 SG_ UI_solarAzimuthAngleCarRef : 16|9@1- (1,0) [-256|254] "deg"  Receiver
 SG_ UI_solarElevationAngle : 32|8@1- (1,0) [-128|126] "deg"  Receiver

BO_ 777 ID309DAS_object: 8 VehicleBus
 SG_ DAS_objectId M : 0|3@1+ (1,0) [0|5] ""  Receiver
 SG_ DAS_cutinVehDx m3 : 8|8@1+ (0.5,0) [0|127] "m"  Receiver
 SG_ DAS_cutinVehDy m3 : 20|7@1+ (0.35,-22.05) [-22.05|22.4] "m"  Receiver
 SG_ DAS_cutinVehHeading m5 : 56|8@1+ (0.0245437,-3.1415936) [-3.1415936|3.0925062] "rad"  Receiver
 SG_ DAS_cutinVehId m3 : 27|7@1+ (1,0) [0|127] ""  Receiver
 SG_ DAS_cutinVehRelevantForControl m3 : 7|1@1+ (1,0) [0|1] ""  Receiver
 SG_ DAS_cutinVehType m3 : 3|3@1+ (1,0) [0|5] ""  Receiver
 SG_ DAS_cutinVehVxRel m3 : 16|4@1+ (4,-30) [-30|26] "m/s"  Receiver
 SG_ DAS_leadVeh2Dx m0 : 39|8@1+ (0.5,0) [0|127] "m"  Receiver
 SG_ DAS_leadVeh2Dy m0 : 51|7@1+ (0.35,-22.05) [-22.05|22.4] "m"  Receiver
 SG_ DAS_leadVeh2Heading m5 : 16|8@1+ (0.0245437,-3.1415936) [-3.1415936|3.0925062] "rad"  Receiver
 SG_ DAS_leadVeh2Id m0 : 58|6@1+ (1,0) [0|63] ""  Receiver
 SG_ DAS_leadVeh2RelevantForControl m0 : 38|1@1+ (1,0) [0|1] ""  Receiver
 SG_ DAS_leadVeh2Type m0 : 34|3@1+ (1,0) [0|5] ""  Receiver
 SG_ DAS_leadVeh2VxRel m0 : 47|4@1+ (4,-30) [-30|26] "m/s"  Receiver
 SG_ DAS_leadVehDx m0 : 8|8@1+ (0.5,0) [0|127] "m"  Receiver
 SG_ DAS_leadVehDy m0 : 20|7@1+ (0.35,-22.05) [-22.05|22.4] "m"  Receiver
 SG_ DAS_leadVehHeading m5 : 8|8@1+ (0.0245437,-3.1415936) [-3.1415936|3.0925062] "rad"  Receiver
 SG_ DAS_leadVehId m0 : 27|7@1+ (1,0) [0|127] ""  Receiver
 SG_ DAS_leadVehRelevantForControl m0 : 7|1@1+ (1,0) [0|1] ""  Receiver
 SG_ DAS_leadVehType m0 : 3|3@1+ (1,0) [0|6] ""  Receiver
 SG_ DAS_leadVehVxRel m0 : 16|4@1+ (4,-30) [-30|26] "m/s"  Receiver
 SG_ DAS_leftVeh2Dx m1 : 39|8@1+ (0.5,0) [0|127] "m"  Receiver
 SG_ DAS_leftVeh2Dy m1 : 51|7@1+ (0.35,-22.05) [-22.05|22.4] "m"  Receiver
 SG_ DAS_leftVeh2Heading m5 : 32|8@1+ (0.0245437,-3.1415936) [-3.1415936|3.0925062] "rad"  Receiver
 SG_ DAS_leftVeh2Id m1 : 58|6@1+ (1,0) [0|63] ""  Receiver
 SG_ DAS_leftVeh2RelevantForControl m1 : 38|1@1+ (1,0) [0|1] ""  Receiver
 SG_ DAS_leftVeh2Type m1 : 34|3@1+ (1,0) [0|5] ""  Receiver
 SG_ DAS_leftVeh2VxRel m1 : 47|4@1+ (4,-30) [-30|26] "m/s"  Receiver
 SG_ DAS_leftVehDx m1 : 8|8@1+ (0.5,0) [0|127] "m"  Receiver
 SG_ DAS_leftVehDy m1 : 20|7@1+ (0.35,-22.05) [-22.05|22.4] "m"  Receiver
 SG_ DAS_leftVehHeading m5 : 24|8@1+ (0.0245437,-3.1415936) [-3.1415936|3.0925062] "rad"  Receiver
 SG_ DAS_leftVehId m1 : 27|7@1+ (1,0) [0|127] ""  Receiver
 SG_ DAS_leftVehRelevantForControl m1 : 7|1@1+ (1,0) [0|1] ""  Receiver
 SG_ DAS_leftVehType m1 : 3|3@1+ (1,0) [0|5] ""  Receiver
 SG_ DAS_leftVehVxRel m1 : 16|4@1+ (4,-30) [-30|26] "m/s"  Receiver
 SG_ DAS_rightVeh2Dx m2 : 39|8@1+ (0.5,0) [0|127] "m"  Receiver
 SG_ DAS_rightVeh2Dy m2 : 51|7@1+ (0.35,-22.05) [-22.05|22.4] "m"  Receiver
 SG_ DAS_rightVeh2Heading m5 : 48|8@1+ (0.0245437,-3.1415936) [-3.1415936|3.0925062] "rad"  Receiver
 SG_ DAS_rightVeh2Id m2 : 58|6@1+ (1,0) [0|63] ""  Receiver
 SG_ DAS_rightVeh2RelevantForControl m2 : 38|1@1+ (1,0) [0|1] ""  Receiver
 SG_ DAS_rightVeh2Type m2 : 34|3@1+ (1,0) [0|5] ""  Receiver
 SG_ DAS_rightVeh2VxRel m2 : 47|4@1+ (4,-30) [-30|26] "m/s"  Receiver
 SG_ DAS_rightVehDx m2 : 8|8@1+ (0.5,0) [0|127] "m"  Receiver
 SG_ DAS_rightVehDy m2 : 20|7@1+ (0.35,-22.05) [-22.05|22.4] "m"  Receiver
 SG_ DAS_rightVehHeading m5 : 40|8@1+ (0.0245437,-3.1415936) [-3.1415936|3.0925062] "rad"  Receiver
 SG_ DAS_rightVehId m2 : 27|7@1+ (1,0) [0|127] ""  Receiver
 SG_ DAS_rightVehRelevantForControl m2 : 7|1@1+ (1,0) [0|1] ""  Receiver
 SG_ DAS_rightVehType m2 : 3|3@1+ (1,0) [0|5] ""  Receiver
 SG_ DAS_rightVehVxRel m2 : 16|4@1+ (4,-30) [-30|26] "m/s"  Receiver
 SG_ DAS_roadSignArrow m4 : 27|3@1+ (1,0) [0|4] ""  Receiver
 SG_ DAS_roadSignColor m4 : 3|3@1+ (1,0) [0|4] ""  Receiver
 SG_ DAS_roadSignControlActive m4 : 24|1@1+ (1,0) [0|1] ""  Receiver
 SG_ DAS_roadSignId m4 : 6|8@1+ (1,0) [0|255] ""  Receiver
 SG_ DAS_roadSignOrientation m4 : 30|2@1+ (1,0) [0|2] ""  Receiver
 SG_ DAS_roadSignSource m4 : 25|2@1+ (1,0) [0|2] ""  Receiver
 SG_ DAS_roadSignStopLineDist m4 : 14|10@1+ (0.2,-20) [-20|184.4] "m"  Receiver

BO_ 905 ID389DAS_status2: 8 ChassisBus
 SG_ DAS_ACC_report : 26|5@1+ (1,0) [0|24] ""  Receiver
 SG_ DAS_accSpeedLimit : 0|10@1+ (0.2,0) [0|204.6] "mph"  Receiver
 SG_ DAS_activationFailureStatus : 14|2@1+ (1,0) [0|2] ""  Receiver
 SG_ DAS_csaState : 32|2@1+ (1,0) [0|3] ""  Receiver
 SG_ DAS_driverInteractionLevel : 38|2@1+ (1,0) [0|2] ""  Receiver
 SG_ DAS_longCollisionWarning : 48|4@1+ (1,0) [0|15] ""  Receiver
 SG_ DAS_pmmCameraFaultReason : 24|2@1+ (1,0) [0|2] ""  Receiver
 SG_ DAS_pmmLoggingRequest : 13|1@1+ (1,0) [0|1] ""  Receiver
 SG_ DAS_pmmObstacleSeverity : 10|3@1+ (1,0) [0|7] ""  Receiver
 SG_ DAS_pmmRadarFaultReason : 19|2@1+ (1,0) [0|2] ""  Receiver
 SG_ DAS_pmmSysFaultReason : 21|3@1+ (1,0) [0|7] ""  Receiver
 SG_ DAS_pmmUltrasonicsFaultReason : 16|3@1+ (1,0) [0|4] ""  Receiver
 SG_ DAS_ppOffsetDesiredRamp : 40|8@1+ (0.01,-1.28) [-1.28|1.27] "m"  Receiver
 SG_ DAS_radarTelemetry : 34|2@1+ (1,0) [0|2] ""  Receiver
 SG_ DAS_relaxCruiseLimits : 31|1@1+ (1,0) [0|1] ""  Receiver
 SG_ DAS_robState : 36|2@1+ (1,0) [0|3] ""  Receiver
 SG_ DAS_status2Checksum : 56|8@1+ (1,0) [0|255] ""  Receiver
 SG_ DAS_status2Counter : 52|4@1+ (1,0) [0|15] ""  Receiver

BO_ 921 ID399DAS_status: 8 ChassisBus
 SG_ DAS_autoLaneChangeState : 46|5@1+ (1,0) [0|31] ""  Receiver
 SG_ DAS_autoParked : 25|1@1+ (1,0) [0|1] ""  Receiver
 SG_ DAS_autoparkReady : 24|1@1+ (1,0) [0|1] ""  Receiver
 SG_ DAS_autoparkWaitingForBrake : 26|1@1+ (1,0) [0|1] ""  Receiver
 SG_ DAS_autopilotHandsOnState : 42|4@1+ (1,0) [0|15] ""  Receiver
 SG_ DAS_autopilotState : 0|4@1+ (1,0) [0|15] ""  Receiver
 SG_ DAS_blindSpotRearLeft : 4|2@1+ (1,0) [0|3] ""  Receiver
 SG_ DAS_blindSpotRearRight : 6|2@1+ (1,0) [0|3] ""  Receiver
 SG_ DAS_fleetSpeedState : 40|2@1+ (1,0) [0|3] ""  Receiver
 SG_ DAS_forwardCollisionWarning : 22|2@1+ (1,0) [0|3] ""  Receiver
 SG_ DAS_fusedSpeedLimit : 8|5@1+ (5,0) [0|150] "kph/mph"  Receiver
 SG_ DAS_heaterState : 21|1@1+ (1,0) [0|1] ""  Receiver
 SG_ DAS_laneDepartureWarning : 37|3@1+ (1,0) [0|5] ""  Receiver
 SG_ DAS_lssState : 29|3@1+ (1,0) [0|7] ""  Receiver
 SG_ DAS_sideCollisionAvoid : 32|2@1+ (1,0) [0|3] ""  Receiver
 SG_ DAS_sideCollisionInhibit : 36|1@1+ (1,0) [0|1] ""  Receiver
 SG_ DAS_sideCollisionWarning : 34|2@1+ (1,0) [0|3] ""  Receiver
 SG_ DAS_statusChecksum : 56|8@1+ (1,0) [0|255] ""  Receiver
 SG_ DAS_statusCounter : 52|4@1+ (1,0) [0|15] ""  Receiver
 SG_ DAS_summonAvailable : 51|1@1+ (1,0) [0|1] ""  Receiver
 SG_ DAS_summonClearedGate : 15|1@1+ (1,0) [0|1] ""  Receiver
 SG_ DAS_summonFwdLeashReached : 27|1@1+ (1,0) [0|1] ""  Receiver
 SG_ DAS_summonObstacle : 14|1@1+ (1,0) [0|1] ""  Receiver
 SG_ DAS_summonRvsLeashReached : 28|1@1+ (1,0) [0|1] ""  Receiver
 SG_ DAS_suppressSpeedWarning : 13|1@1+ (1,0) [0|1] ""  Receiver
 SG_ DAS_visionOnlySpeedLimit : 16|5@1+ (5,0) [0|150] "kph/mph"  Receiver

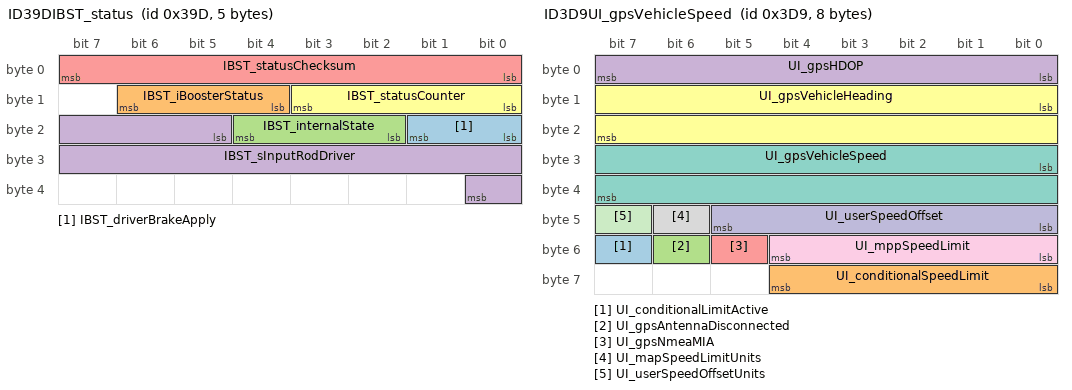
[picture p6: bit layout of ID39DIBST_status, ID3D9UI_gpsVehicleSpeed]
BO_ 925 ID39DIBST_status: 5 ChassisBus
 SG_ IBST_driverBrakeApply : 16|2@1+ (1,0) [0|3] ""  Receiver
 SG_ IBST_iBoosterStatus : 12|3@1+ (1,0) [0|6] ""  Receiver
 SG_ IBST_internalState : 18|3@1+ (1,0) [0|6] ""  Receiver
 SG_ IBST_sInputRodDriver : 21|12@1+ (0.015625,-5) [-5|47] "mm"  Receiver
 SG_ IBST_statusChecksum : 0|8@1+ (1,0) [0|255] ""  Receiver
 SG_ IBST_statusCounter : 8|4@1+ (1,0) [0|15] ""  Receiver

BO_ 929 ID3A1VCFRONT_vehicleStatus: 8 VehicleBus
 SG_ VCFRONT_12vStatusForDrive : 14|2@1+ (1,0) [0|2] ""  Receiver
 SG_ VCFRONT_2RowCenterUnbuckled : 38|2@1+ (1,0) [0|2] ""  Receiver
 SG_ VCFRONT_2RowLeftUnbuckled : 36|2@1+ (1,0) [0|2] ""  Receiver
 SG_ VCFRONT_2RowRightUnbuckled : 40|2@1+ (1,0) [0|2] ""  Receiver
 SG_ VCFRONT_APGlassHeaterState : 2|3@1+ (1,0) [0|4] ""  Receiver
 SG_ VCFRONT_accPlusAvailable : 9|1@1+ (1,0) [0|1] ""  Receiver
 SG_ VCFRONT_batterySupportRequest : 27|1@1+ (1,0) [0|1] ""  Receiver
 SG_ VCFRONT_bmsHvChargeEnable : 0|1@1+ (1,0) [0|1] ""  Receiver
 SG_ VCFRONT_diPowerOnState : 10|3@1+ (1,0) [0|4] ""  Receiver
 SG_ VCFRONT_driverBuckleStatus : 30|1@1+ (1,0) [0|1] ""  Receiver
 SG_ VCFRONT_driverDoorStatus : 31|1@1+ (1,0) [0|1] ""  Receiver
 SG_ VCFRONT_driverIsLeaving : 28|1@1+ (1,0) [0|1] ""  Receiver
 SG_ VCFRONT_driverIsLeavingAnySpeed : 13|1@1+ (1,0) [0|1] ""  Receiver
 SG_ VCFRONT_driverPresent : 7|1@1+ (1,0) [0|1] ""  Receiver
 SG_ VCFRONT_driverUnbuckled : 32|2@1+ (1,0) [0|2] ""  Receiver
 SG_ VCFRONT_ota12VSupportRequest : 29|1@1+ (1,0) [0|1] ""  Receiver
 SG_ VCFRONT_passengerPresent : 8|1@1+ (1,0) [0|1] ""  Receiver
 SG_ VCFRONT_passengerUnbuckled : 34|2@1+ (1,0) [0|2] ""  Receiver
 SG_ VCFRONT_pcs12vVoltageTarget : 16|11@1+ (0.01,0) [0|16] "V"  Receiver
 SG_ VCFRONT_pcsEFuseVoltage : 42|10@1+ (0.1,0) [0|102.2] "V"  Receiver
 SG_ VCFRONT_preconditionRequest : 1|1@1+ (1,0) [0|1] ""  Receiver
 SG_ VCFRONT_standbySupplySupported : 6|1@1+ (1,0) [0|1] ""  Receiver
 SG_ VCFRONT_thermalSystemType : 5|1@1+ (1,0) [0|1] ""  Receiver
 SG_ VCFRONT_vehicleStatusChecksum : 56|8@1+ (1,0) [0|255] ""  Receiver
 SG_ VCFRONT_vehicleStatusCounter : 52|4@1+ (1,0) [0|15] ""  Receiver

BO_ 985 ID3D9UI_gpsVehicleSpeed: 8 ChassisBus
 SG_ UI_conditionalLimitActive : 55|1@1+ (1,0) [0|1] ""  Receiver
 SG_ UI_conditionalSpeedLimit : 56|5@1+ (5,0) [0|155] "kph/mph"  Receiver
 SG_ UI_gpsAntennaDisconnected : 54|1@1+ (1,0) [0|1] ""  Receiver
 SG_ UI_gpsHDOP : 0|8@1+ (0.1,0) [0|25.5] ""  Receiver
 SG_ UI_gpsNmeaMIA : 53|1@1+ (1,0) [0|1] ""  Receiver
 SG_ UI_gpsVehicleHeading : 8|16@1+ (0.0078125,0) [0|511.9921875] "deg"  Receiver
 SG_ UI_gpsVehicleSpeed : 24|16@1+ (0.00390625,0) [0|250.996] "kph"  Receiver
 SG_ UI_mapSpeedLimitUnits : 46|1@1+ (1,0) [0|1] ""  Receiver
 SG_ UI_mppSpeedLimit : 48|5@1+ (5,0) [0|155] "kph/mph"  Receiver
 SG_ UI_userSpeedOffset : 40|6@1+ (1,-30) [-30|33] "kph/mph"  Receiver
 SG_ UI_userSpeedOffsetUnits : 47|1@1+ (1,0) [0|1] ""  Receiver

BO_ 994 ID3E2VCLEFT_lightStatus: 7 VehicleBus
 SG_ VCLEFT_FLMapLightStatus : 6|2@1+ (1,0) [0|3] ""  Receiver
 SG_ VCLEFT_FLMapLightSwitchPressed : 14|1@1+ (1,0) [0|1] ""  Receiver
 SG_ VCLEFT_FRMapLightStatus : 8|2@1+ (1,0) [0|3] ""  Receiver
 SG_ VCLEFT_FRMapLightSwitchPressed : 15|1@1+ (1,0) [0|1] ""  Receiver
 SG_ VCLEFT_RLMapLightStatus : 10|2@1+ (1,0) [0|3] ""  Receiver
 SG_ VCLEFT_RLMapLightSwitchPressed : 16|1@1+ (1,0) [0|1] ""  Receiver
 SG_ VCLEFT_RRMapLightStatus : 12|2@1+ (1,0) [0|3] ""  Receiver
 SG_ VCLEFT_RRMapLightSwitchPressed : 17|1@1+ (1,0) [0|1] ""  Receiver
 SG_ VCLEFT_brakeLightStatus : 0|2@1+ (1,0) [0|3] ""  Receiver
 SG_ VCLEFT_brakeTrailerLightStatus : 22|2@1+ (1,0) [0|3] ""  Receiver
 SG_ VCLEFT_dynamicBrakeLightStatus : 44|2@1+ (1,0) [0|2] ""  Receiver
 SG_ VCLEFT_fogTrailerLightStatus : 26|2@1+ (1,0) [0|3] ""  Receiver
 SG_ VCLEFT_frontRideHeight : 28|8@1- (1,0) [-127|127] "mm"  Receiver
 SG_ VCLEFT_leftTurnTrailerLightStatu : 18|2@1+ (1,0) [0|3] ""  Receiver
 SG_ VCLEFT_rearRideHeight : 36|8@1- (1,0) [-127|127] "mm"  Receiver
 SG_ VCLEFT_reverseTrailerLightStatus : 49|2@1+ (1,0) [0|3] ""  Receiver
 SG_ VCLEFT_rideHeightSensorFault : 48|1@1+ (1,0) [0|1] ""  Receiver
 SG_ VCLEFT_rightTrnTrailerLightStatu : 20|2@1+ (1,0) [0|3] ""  Receiver
 SG_ VCLEFT_tailLightStatus : 2|2@1+ (1,0) [0|3] ""  Receiver
 SG_ VCLEFT_tailTrailerLightStatus : 24|2@1+ (1,0) [0|3] ""  Receiver
 SG_ VCLEFT_trailerDetected : 46|2@1+ (1,0) [0|3] ""  Receiver
 SG_ VCLEFT_turnSignalStatus : 4|2@1+ (1,0) [0|3] ""  Receiver

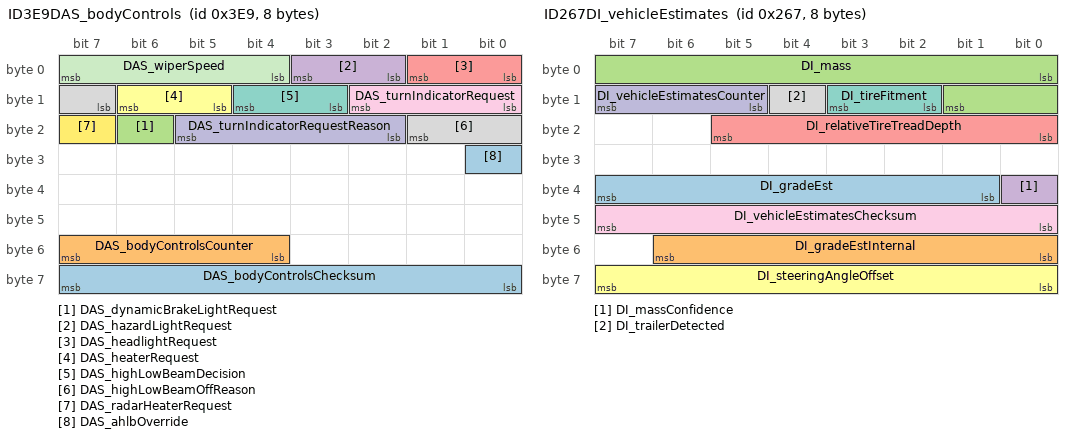
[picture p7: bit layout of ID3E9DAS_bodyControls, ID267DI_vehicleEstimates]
BO_ 1001 ID3E9DAS_bodyControls: 8 VehicleBus
 SG_ DAS_bodyControlsChecksum : 56|8@1+ (1,0) [0|255] ""  Receiver
 SG_ DAS_bodyControlsCounter : 52|4@1+ (1,0) [0|15] ""  Receiver
 SG_ DAS_dynamicBrakeLightRequest : 22|1@1+ (1,0) [0|1] ""  Receiver
 SG_ DAS_hazardLightRequest : 2|2@1+ (1,0) [0|3] ""  Receiver
 SG_ DAS_headlightRequest : 0|2@1+ (1,0) [0|3] ""  Receiver
 SG_ DAS_heaterRequest : 13|2@1+ (1,0) [0|2] ""  Receiver
 SG_ DAS_highLowBeamDecision : 11|2@1+ (1,0) [0|3] ""  Receiver
 SG_ DAS_highLowBeamOffReason : 15|3@1+ (1,0) [0|5] ""  Receiver
 SG_ DAS_turnIndicatorRequest : 8|3@1+ (1,0) [0|4] ""  Receiver
 SG_ DAS_turnIndicatorRequestReason : 18|4@1+ (1,0) [0|12] ""  Receiver
 SG_ DAS_wiperSpeed : 4|4@1+ (1,0) [0|15] ""  Receiver
 SG_ DAS_radarHeaterRequest : 23|1@1+ (1,0) [0|1] ""  Receiver
 SG_ DAS_ahlbOverride : 24|1@1+ (1,0) [0|1] ""  Receiver

BO_ 1011 ID3F3UI_odo: 3 ChassisBus
 SG_ UI_odometer : 0|24@1+ (0.1,0) [0|1677721.5] "km"  Receiver

BO_ 1013 ID3F5VCFRONT_lighting: 8 VehicleBus
 SG_ VCFRONT_DRLLeftStatus : 36|2@1+ (1,0) [0|3] ""  Receiver
 SG_ VCFRONT_DRLRightStatus : 38|2@1+ (1,0) [0|3] ""  Receiver
 SG_ VCFRONT_ambientLightingBrightnes : 8|8@1+ (0.5,0) [0|127] "%"  Receiver
 SG_ VCFRONT_approachLightingRequest : 25|1@1+ (1,0) [0|1] ""  Receiver
 SG_ VCFRONT_courtesyLightingRequest : 24|1@1+ (1,0) [0|1] ""  Receiver
 SG_ VCFRONT_fogLeftStatus : 40|2@1+ (1,0) [0|3] ""  Receiver
 SG_ VCFRONT_fogRightStatus : 42|2@1+ (1,0) [0|3] ""  Receiver
 SG_ VCFRONT_hazardLightRequest : 4|4@1+ (1,0) [0|8] ""  Receiver
 SG_ VCFRONT_hazardSwitchBacklight : 27|1@1+ (1,0) [0|1] ""  Receiver
 SG_ VCFRONT_highBeamLeftStatus : 32|2@1+ (1,0) [0|3] ""  Receiver
 SG_ VCFRONT_highBeamRightStatus : 34|2@1+ (1,0) [0|3] ""  Receiver
 SG_ VCFRONT_highBeamSwitchActive : 58|1@1+ (1,0) [0|1] ""  Receiver
 SG_ VCFRONT_indicatorLeftRequest : 0|2@1+ (1,0) [0|2] ""  Receiver
 SG_ VCFRONT_indicatorRightRequest : 2|2@1+ (1,0) [0|2] ""  Receiver
 SG_ VCFRONT_lowBeamLeftStatus : 28|2@1+ (1,0) [0|3] ""  Receiver
 SG_ VCFRONT_lowBeamRightStatus : 30|2@1+ (1,0) [0|3] ""  Receiver
 SG_ VCFRONT_lowBeamsCalibrated : 62|1@1+ (1,0) [0|1] ""  Receiver
 SG_ VCFRONT_lowBeamsOnForDRL : 61|1@1+ (1,0) [0|1] ""  Receiver
 SG_ VCFRONT_parkLeftStatus : 54|2@1+ (1,0) [0|3] ""  Receiver
 SG_ VCFRONT_parkRightStatus : 56|2@1+ (1,0) [0|3] ""  Receiver
 SG_ VCFRONT_seeYouHomeLightingReq : 26|1@1+ (1,0) [0|1] ""  Receiver
 SG_ VCFRONT_sideMarkersStatus : 44|2@1+ (1,0) [0|3] ""  Receiver
 SG_ VCFRONT_sideRepeaterLeftStatus : 46|2@1+ (1,0) [0|3] ""  Receiver
 SG_ VCFRONT_sideRepeaterRightStatus : 48|2@1+ (1,0) [0|3] ""  Receiver
 SG_ VCFRONT_simLatchingStalk : 59|2@1+ (1,0) [0|3] ""  Receiver
 SG_ VCFRONT_switchLightingBrightness : 16|8@1+ (0.5,0) [0|127] "%"  Receiver
 SG_ VCFRONT_turnSignalLeftStatus : 50|2@1+ (1,0) [0|3] ""  Receiver
 SG_ VCFRONT_turnSignalRightStatus : 52|2@1+ (1,0) [0|3] ""  Receiver

BO_ 1016 ID3F8UI_driverAssistControl: 8 ChassisBus
 SG_ UI_accFollowDistanceSetting : 45|3@1+ (1,0) [0|7] ""  Receiver
 SG_ UI_adaptiveSetSpeedEnable : 39|1@1+ (1,0) [0|1] ""  Receiver
 SG_ UI_alcOffHighwayEnable : 56|1@1+ (1,0) [0|1] ""  Receiver
 SG_ UI_autoSummonEnable : 10|1@1+ (1,0) [0|1] ""  Receiver
 SG_ UI_autopilotControlRequest : 0|1@1+ (1,0) [0|1] ""  Receiver
 SG_ UI_coastToCoast : 9|1@1+ (1,0) [0|1] ""  Receiver
 SG_ UI_curvSpeedAdaptDisable : 4|1@1+ (1,0) [0|1] ""  Receiver
 SG_ UI_curvatureDatabaseOnly : 22|1@1+ (1,0) [0|1] ""  Receiver
 SG_ UI_dasDeveloper : 5|1@1+ (1,0) [0|1] ""  Receiver
 SG_ UI_driveOnMapsEnable : 13|1@1+ (1,0) [0|1] ""  Receiver
 SG_ UI_drivingSide : 40|2@1+ (1,0) [0|2] ""  Receiver
 SG_ UI_enableBrakeLightPulse : 63|1@1+ (1,0) [0|1] ""  Receiver
 SG_ UI_enableClipTelemetry : 42|1@1+ (1,0) [0|1] ""  Receiver
 SG_ UI_enableRoadSegmentTelemetry : 44|1@1+ (1,0) [0|1] ""  Receiver
 SG_ UI_enableTripTelemetry : 43|1@1+ (1,0) [0|1] ""  Receiver
 SG_ UI_enableVinAssociation : 6|1@1+ (1,0) [0|1] ""  Receiver
 SG_ UI_enableVisionOnlyStops : 60|1@1+ (1,0) [0|1] ""  Receiver
 SG_ UI_exceptionListEnable : 11|1@1+ (1,0) [0|1] ""  Receiver
 SG_ UI_followNavRouteEnable : 49|1@1+ (1,0) [0|1] ""  Receiver
 SG_ UI_fuseHPPDisable : 17|1@1+ (1,0) [0|1] ""  Receiver
 SG_ UI_fuseLanesDisable : 16|1@1+ (1,0) [0|1] ""  Receiver
 SG_ UI_fuseVehiclesDisable : 18|1@1+ (1,0) [0|1] ""  Receiver
 SG_ UI_handsOnRequirementDisable : 14|1@1+ (1,0) [0|1] ""  Receiver
 SG_ UI_hasDriveOnNav : 48|1@1+ (1,0) [0|1] ""  Receiver
 SG_ UI_lssElkEnabled : 23|1@1+ (1,0) [0|1] ""  Receiver
 SG_ UI_lssLdwEnabled : 8|1@1+ (1,0) [0|1] ""  Receiver
 SG_ UI_lssLkaEnabled : 7|1@1+ (1,0) [0|1] ""  Receiver
 SG_ UI_roadCheckDisable : 12|1@1+ (1,0) [0|1] ""  Receiver
 SG_ UI_selfParkRequest : 28|4@1+ (1,0) [0|15] ""  Receiver
 SG_ UI_smartSummonType : 58|2@1+ (1,0) [0|2] ""  Receiver
 SG_ UI_source3D : 61|2@1+ (1,0) [0|2] ""  Receiver
 SG_ UI_summonEntryType : 26|2@1+ (1,0) [0|3] ""  Receiver
 SG_ UI_summonExitType : 24|2@1+ (1,0) [0|3] ""  Receiver
 SG_ UI_summonHeartbeat : 2|2@1+ (1,0) [0|3] ""  Receiver
 SG_ UI_summonReverseDist : 32|6@1+ (1,0) [0|63] ""  Receiver
 SG_ UI_ulcBlindSpotConfig : 52|2@1+ (1,0) [0|2] ""  Receiver
 SG_ UI_ulcOffHighway : 15|1@1+ (1,0) [0|1] ""  Receiver
 SG_ UI_ulcSpeedConfig : 50|2@1+ (1,0) [0|3] ""  Receiver
 SG_ UI_ulcStalkConfirm : 1|1@1+ (1,0) [0|1] ""  Receiver
 SG_ UI_undertakeAssistEnable : 38|1@1+ (1,0) [0|1] ""  Receiver
 SG_ UI_validationLoop : 57|1@1+ (1,0) [0|1] ""  Receiver
 SG_ UI_visionSpeedType : 20|2@1+ (1,0) [0|3] ""  Receiver

BO_ 1021 ID3FDUI_autopilotControl: 8 ChassisBus
 SG_ UI_autopilotControlIndex M : 0|3@1+ (1,0) [0|7] ""  Receiver
 SG_ UI_apmv3Branch m1 : 40|3@1+ (1,0) [0|5] ""  Receiver
 SG_ UI_applyEceR79 m1 : 19|1@1+ (1,0) [0|1] ""  Receiver
 SG_ UI_blindspotDistance m0 : 15|3@1+ (1,0) [0|5] ""  Receiver
 SG_ UI_blindspotMinSpeed m0 : 11|4@1+ (1,0) [0|10] ""  Receiver
 SG_ UI_blindspotTTC m0 : 18|3@1+ (1,0) [0|7] ""  Receiver
 SG_ UI_disableBackup m1 : 30|1@1+ (1,0) [0|1] ""  Receiver
 SG_ UI_disableFisheye m1 : 25|1@1+ (1,0) [0|1] ""  Receiver
 SG_ UI_disableLeftPillar m1 : 26|1@1+ (1,0) [0|1] ""  Receiver
 SG_ UI_disableLeftRepeater m1 : 28|1@1+ (1,0) [0|1] ""  Receiver
 SG_ UI_disableMain m1 : 23|1@1+ (1,0) [0|1] ""  Receiver
 SG_ UI_disableNarrow m1 : 24|1@1+ (1,0) [0|1] ""  Receiver
 SG_ UI_disableRadar m1 : 31|1@1+ (1,0) [0|1] ""  Receiver
 SG_ UI_disableRightPillar m1 : 27|1@1+ (1,0) [0|1] ""  Receiver
 SG_ UI_disableRightRepeater m1 : 29|1@1+ (1,0) [0|1] ""  Receiver
 SG_ UI_donAlcProgGoreAbortThres m0 : 29|4@1+ (1,0) [0|9] ""  Receiver
 SG_ UI_donDisableAutoWiperDuration m0 : 4|3@1+ (1,0) [0|6] ""  Receiver
 SG_ UI_donDisableCutin m0 : 24|1@1+ (1,0) [0|1] ""  Receiver
 SG_ UI_donDisableOnAutoWiperSpeed m0 : 7|4@1+ (1,0) [0|15] ""  Receiver
 SG_ UI_donMinGoreWidthForAbortMap m0 : 25|4@1+ (1,0) [0|11] ""  Receiver
 SG_ UI_donMinGoreWidthForAbortNotMap m0 : 33|4@1+ (1,0) [0|11] ""  Receiver
 SG_ UI_donStopEndOfRampBuffer m0 : 21|3@1+ (1,0) [0|4] ""  Receiver
 SG_ UI_driverMonitorConfirmation m1 : 17|1@1+ (1,0) [0|1] ""  Receiver
 SG_ UI_enableAutopilotStopWarning m1 : 44|1@1+ (1,0) [0|1] ""  Receiver
 SG_ UI_enableCabinCamera m1 : 43|1@1+ (1,0) [0|1] ""  Receiver
 SG_ UI_enableCabinCameraTelemetry m1 : 48|1@1+ (1,0) [0|1] ""  Receiver
 SG_ UI_enableMapStops m1 : 20|1@1+ (1,0) [0|1] ""  Receiver
 SG_ UI_factorySummonEnable m1 : 39|1@1+ (1,0) [0|1] ""  Receiver
 SG_ UI_fsdStopsControlEnabled m0 : 38|1@1+ (1,0) [0|1] ""  Receiver
 SG_ UI_fsdVisualizationEnabled m0 : 37|1@1+ (1,0) [0|1] ""  Receiver
 SG_ UI_hardCoreSummon m1 : 47|1@1+ (1,0) [0|1] ""  Receiver
 SG_ UI_homelinkNearby m0 : 45|1@1+ (1,0) [0|1] ""  Receiver
 SG_ UI_hovEnabled m0 : 3|1@1+ (1,0) [0|1] ""  Receiver
 SG_ UI_noStalkConfirmAlertChime m1 : 37|1@1+ (1,0) [0|1] ""  Receiver
 SG_ UI_noStalkConfirmAlertHaptic m1 : 32|1@1+ (1,0) [0|1] ""  Receiver
 SG_ UI_showLaneGraph m1 : 45|1@1+ (1,0) [0|1] ""  Receiver
 SG_ UI_showTrackLabels m1 : 46|1@1+ (1,0) [0|1] ""  Receiver
 SG_ UI_ulcSnooze m1 : 36|1@1+ (1,0) [0|1] ""  Receiver

BO_ 611 ID263VCRIGHT_logging10Hz: 8 VehicleBus
 SG_ VCRIGHT_logging10HzIndex M : 0|3@1+ (1,0) [0|4] ""  Receiver
 SG_ VCRIGHT_EvapPulldownBias m3 : 8|8@1+ (0.4,0) [0|100] "%"  Receiver
 SG_ VCRIGHT_EvapPulldownBiasActive m3 : 16|1@1+ (1,0) [0|1] ""  Receiver
 SG_ VCRIGHT_hvacCabinHumidityLevel m2 : 55|8@1+ (1,0) [0|100] "%"  Receiver
 SG_ VCRIGHT_hvacEstimateWindshieldRH m2 : 39|8@1+ (1,0) [0|150] "%"  Receiver
 SG_ VCRIGHT_hvacFilterLifeDetectActi m2 : 3|1@1+ (1,0) [0|1] ""  Receiver
 SG_ VCRIGHT_hvacFlashFoggingDetected m2 : 63|1@1+ (1,0) [0|1] ""  Receiver
 SG_ VCRIGHT_hvacFoggingRiskLevel m2 : 47|8@1+ (1,0) [0|100] "%"  Receiver
 SG_ VCRIGHT_hvacIntakeActuatorState m2 : 24|2@1+ (1,0) [0|2] ""  Receiver
 SG_ VCRIGHT_hvacIntakeOperationMode m2 : 10|1@1+ (1,0) [0|1] ""  Receiver
 SG_ VCRIGHT_hvacIntakePosition m1 : 56|8@1+ (0.4,0) [0|100] "%"  Receiver
 SG_ VCRIGHT_hvacIntakeTarget m0 : 56|8@1+ (0.4,0) [0|100] "%"  Receiver
 SG_ VCRIGHT_hvacLHBleedActuatorState m2 : 11|2@1+ (1,0) [0|2] ""  Receiver
 SG_ VCRIGHT_hvacLHBleedOperationMode m2 : 4|1@1+ (1,0) [0|1] ""  Receiver
 SG_ VCRIGHT_hvacLHBleedPosition m1 : 8|8@1+ (0.4,0) [0|100] "%"  Receiver
 SG_ VCRIGHT_hvacLHBleedTarget m0 : 8|8@1+ (0.4,0) [0|100] "%"  Receiver
 SG_ VCRIGHT_hvacLHVaneActuatorState m2 : 16|2@1+ (1,0) [0|2] ""  Receiver
 SG_ VCRIGHT_hvacLHVaneOperationMode m2 : 6|1@1+ (1,0) [0|1] ""  Receiver
 SG_ VCRIGHT_hvacLHVanePosition m1 : 24|8@1+ (0.4,0) [0|100] "%"  Receiver
 SG_ VCRIGHT_hvacLHVaneTarget m0 : 24|8@1+ (0.4,0) [0|100] "%"  Receiver
 SG_ VCRIGHT_hvacLowerModeActState m2 : 22|2@1+ (1,0) [0|2] ""  Receiver
 SG_ VCRIGHT_hvacLowerModeOpMode m2 : 9|1@1+ (1,0) [0|1] ""  Receiver
 SG_ VCRIGHT_hvacLowerModePosition m1 : 48|8@1+ (0.4,0) [0|100] "%"  Receiver
 SG_ VCRIGHT_hvacLowerModeTarget m0 : 48|8@1+ (0.4,0) [0|100] "%"  Receiver
 SG_ VCRIGHT_hvacRHBleedActuatorState m2 : 13|2@1+ (1,0) [0|2] ""  Receiver
 SG_ VCRIGHT_hvacRHBleedOperationMode m2 : 5|1@1+ (1,0) [0|1] ""  Receiver
 SG_ VCRIGHT_hvacRHBleedPosition m1 : 16|8@1+ (0.4,0) [0|100] "%"  Receiver
 SG_ VCRIGHT_hvacRHBleedTarget m0 : 16|8@1+ (0.4,0) [0|100] "%"  Receiver
 SG_ VCRIGHT_hvacRHVaneActuatorState m2 : 18|2@1+ (1,0) [0|2] ""  Receiver
 SG_ VCRIGHT_hvacRHVaneOperationMode m2 : 7|1@1+ (1,0) [0|1] ""  Receiver
 SG_ VCRIGHT_hvacRHVanePosition m1 : 32|8@1+ (0.4,0) [0|100] "%"  Receiver
 SG_ VCRIGHT_hvacRHVaneTarget m0 : 32|8@1+ (0.4,0) [0|100] "%"  Receiver
 SG_ VCRIGHT_hvacUpperModeActState m2 : 20|2@1+ (1,0) [0|2] ""  Receiver
 SG_ VCRIGHT_hvacUpperModeOpMode m2 : 8|1@1+ (1,0) [0|1] ""  Receiver
 SG_ VCRIGHT_hvacUpperModePosition m1 : 40|8@1+ (0.4,0) [0|100] "%"  Receiver
 SG_ VCRIGHT_hvacUpperModeTarget m0 : 40|8@1+ (0.4,0) [0|100] "%"  Receiver
 SG_ VCRIGHT_timeLeftToCabinModelInit m2 : 32|7@1+ (1,0) [0|127] ""  Receiver

BO_ 615 ID267DI_vehicleEstimates: 8 VehicleBus
 SG_ DI_gradeEst : 33|7@1- (1,0) [-40|40] "%"  Receiver
 SG_ DI_gradeEstInternal : 48|7@1- (1,0) [-40|40] "%"  Receiver
 SG_ DI_mass : 0|10@1+ (5,1900) [1900|7010] "kg"  Receiver
 SG_ DI_massConfidence : 32|1@1+ (1,0) [0|1] ""  Receiver
 SG_ DI_relativeTireTreadDepth : 16|6@1- (0.2,0) [-6.2|6.2] "mm"  Receiver
 SG_ DI_steeringAngleOffset : 56|8@1- (0.2,0) [-25.6|25.4] "Deg"  Receiver
 SG_ DI_tireFitment : 10|2@1+ (1,0) [0|3] ""  Receiver
 SG_ DI_trailerDetected : 12|1@1+ (1,0) [0|1] ""  Receiver
 SG_ DI_vehicleEstimatesChecksum : 40|8@1+ (1,0) [0|255] ""  Receiver
 SG_ DI_vehicleEstimatesCounter : 13|3@1+ (1,0) [0|7] ""  Receiver

BO_ 642 ID282VCLEFT_hvacBlowerFeedback: 8 VehicleBus
 SG_ VCLEFT_blowerIndex M : 0|2@1+ (1,0) [0|1] ""  Receiver
 SG_ VCLEFT_hvacBlowerCBCCtrlState m1 : 58|3@1+ (1,0) [0|4] ""  Receiver
 SG_ VCLEFT_hvacBlowerCBCEstState m1 : 54|4@1+ (1,0) [0|14] ""  Receiver
 SG_ VCLEFT_hvacBlowerEnabled m0 : 2|1@1+ (1,0) [0|1] ""  Receiver
 SG_ VCLEFT_hvacBlowerFETTemp m0 : 44|7@1+ (1.5,-40) [-40|149] "C"  Receiver
 SG_ VCLEFT_hvacBlowerFault m0 : 59|1@1+ (1,0) [0|1] ""  Receiver
 SG_ VCLEFT_hvacBlowerIPhase0 m1 : 10|8@1+ (0.2,0) [0|50] "A"  Receiver
 SG_ VCLEFT_hvacBlowerIPhase1 m1 : 18|8@1+ (0.2,0) [0|50] "A"  Receiver
 SG_ VCLEFT_hvacBlowerIPhase2 m1 : 26|8@1+ (0.2,0) [0|50] "A"  Receiver
 SG_ VCLEFT_hvacBlowerITerm m0 : 51|7@1+ (0.05,-1.5) [-1.5|4.5] "Nm"  Receiver
 SG_ VCLEFT_hvacBlowerInitd m0 : 58|1@1+ (1,0) [0|1] ""  Receiver
 SG_ VCLEFT_hvacBlowerLimitFETTemps m0 : 60|1@1+ (1,0) [0|1] ""  Receiver
 SG_ VCLEFT_hvacBlowerOutputDuty m0 : 3|7@1+ (1,0) [0|100] "%"  Receiver
 SG_ VCLEFT_hvacBlowerPowerOn m0 : 61|1@1+ (1,0) [0|1] ""  Receiver
 SG_ VCLEFT_hvacBlowerRPMActual m0 : 20|10@1+ (10,0) [0|10000] "rpm"  Receiver
 SG_ VCLEFT_hvacBlowerRPMTarget m0 : 10|10@1+ (10,0) [0|10000] "rpm"  Receiver
 SG_ VCLEFT_hvacBlowerRs m1 : 2|8@1+ (0.25,0) [0|60] "mOhm"  Receiver
 SG_ VCLEFT_hvacBlowerRsOnlineActive m1 : 61|1@1+ (1,0) [0|1] ""  Receiver
 SG_ VCLEFT_hvacBlowerSpiError m0 : 62|1@1+ (1,0) [0|1] ""  Receiver
 SG_ VCLEFT_hvacBlowerTorque m0 : 34|10@1+ (0.006,-1.5) [-1.5|4.5] "Nm"  Receiver
 SG_ VCLEFT_hvacBlower_IO_CBC_HEAD m1 : 34|4@1+ (1,0) [0|15] ""  Receiver
 SG_ VCLEFT_hvacBlower_IO_CBC_Status m1 : 43|1@1+ (1,0) [0|1] ""  Receiver
 SG_ VCLEFT_hvacBlower_IO_CBC_TAIL m1 : 38|4@1+ (1,0) [0|15] ""  Receiver
 SG_ VCLEFT_hvacBlower_IO_CBC_TAIL_va m1 : 42|1@1+ (1,0) [0|1] ""  Receiver
 SG_ VCLEFT_hvacBlower_IO_CBC_numUart m1 : 46|8@1+ (1,0) [0|255] ""  Receiver

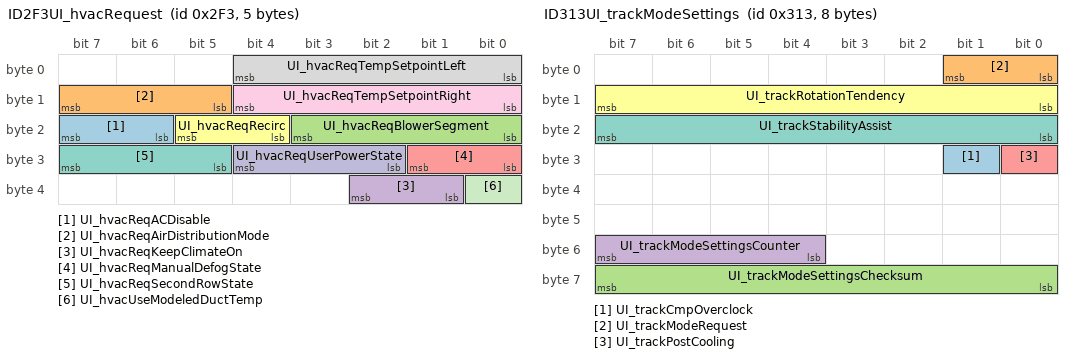
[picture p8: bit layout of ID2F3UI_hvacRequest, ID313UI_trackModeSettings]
BO_ 755 ID2F3UI_hvacRequest: 5 VehicleBus
 SG_ UI_hvacReqACDisable : 22|2@1+ (1,0) [0|2] ""  Receiver
 SG_ UI_hvacReqAirDistributionMode : 13|3@1+ (1,0) [0|7] ""  Receiver
 SG_ UI_hvacReqBlowerSegment : 16|4@1+ (1,0) [0|11] ""  Receiver
 SG_ UI_hvacReqKeepClimateOn : 33|2@1+ (1,0) [0|3] ""  Receiver
 SG_ UI_hvacReqManualDefogState : 24|2@1+ (1,0) [0|2] ""  Receiver
 SG_ UI_hvacReqRecirc : 20|2@1+ (1,0) [0|2] ""  Receiver
 SG_ UI_hvacReqSecondRowState : 29|3@1+ (1,0) [0|4] ""  Receiver
 SG_ UI_hvacReqTempSetpointLeft : 0|5@1+ (0.5,15) [15|28] "C"  Receiver
 SG_ UI_hvacReqTempSetpointRight : 8|5@1+ (0.5,15) [15|28] "C"  Receiver
 SG_ UI_hvacReqUserPowerState : 26|3@1+ (1,0) [0|4] ""  Receiver
 SG_ UI_hvacUseModeledDuctTemp : 32|1@1+ (1,0) [0|1] ""  Receiver

BO_ 787 ID313UI_trackModeSettings: 8 VehicleBus
 SG_ UI_trackCmpOverclock : 25|1@1+ (1,0) [0|1] ""  Receiver
 SG_ UI_trackModeRequest : 0|2@1+ (1,0) [0|2] ""  Receiver
 SG_ UI_trackModeSettingsChecksum : 56|8@1+ (1,0) [0|255] ""  Receiver
 SG_ UI_trackModeSettingsCounter : 52|4@1+ (1,0) [0|15] ""  Receiver
 SG_ UI_trackPostCooling : 24|1@1+ (1,0) [0|1] ""  Receiver
 SG_ UI_trackRotationTendency : 8|8@1+ (0.5,0) [0|100] "%"  Receiver
 SG_ UI_trackStabilityAssist : 16|8@1+ (0.5,0) [0|100] "%"  Receiver

BO_ 821 ID335RearDIinfo: 8 VehicleBus
 SG_ DIR_infoIndex M : 0|8@1+ (1,0) [0|255] ""  Receiver
 SG_ DIR_FPGA_version m16 : 48|8@1+ (1,0) [0|255] ""  Receiver
 SG_ DIR_appGitHash m17 : 8|56@1+ (1,0) [0|7.20575940379279E+016] ""  Receiver
 SG_ DIR_applicationCrc m13 : 32|32@1+ (1,0) [0|4294967295] ""  Receiver
 SG_ DIR_assemblyId m11 : 24|8@1+ (1,0) [0|255] ""  Receiver
 SG_ DIR_bootGitHash m18 : 8|56@1+ (1,0) [0|7.20575940379279E+016] ""  Receiver
 SG_ DIR_bootloaderCrc m20 : 32|32@1+ (1,0) [0|4294967295] ""  Receiver
 SG_ DIR_buildConfigurationId m10 : 16|16@1+ (1,0) [0|65535] ""  Receiver
 SG_ DIR_buildType m10 : 8|3@1+ (1,0) [0|4] ""  Receiver
 SG_ DIR_componentId m10 : 48|16@1+ (1,0) [0|65535] ""  Receiver
 SG_ DIR_hardwareId m10 : 32|8@1+ (1,0) [0|252] ""  Receiver
 SG_ DIR_infoBootLdUdsProtocolVersion m20 : 8|8@1+ (1,0) [0|255] ""  Receiver
 SG_ DIR_oilPumpAppCrc m16 : 16|32@1+ (1,0) [0|4294967295] ""  Receiver
 SG_ DIR_oilPumpBuildType m16 : 8|3@1+ (1,0) [0|4] ""  Receiver
 SG_ DIR_pcbaId m11 : 16|8@1+ (1,0) [0|255] ""  Receiver
 SG_ DIR_platformTyp m19 : 8|8@1+ (1,0) [0|255] ""  Receiver
 SG_ DIR_subUsageId m11 : 48|16@1+ (1,0) [0|65535] ""  Receiver
 SG_ DIR_subcomponentGitHash m31 : 8|56@1+ (1,0) [0|7.20575940379279E+016] ""  Receiver
 SG_ DIR_usageId m11 : 32|16@1+ (1,0) [0|65535] ""  Receiver

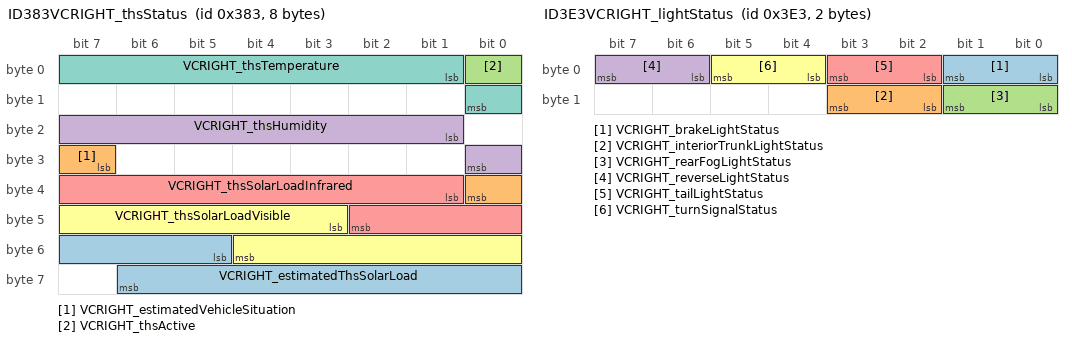
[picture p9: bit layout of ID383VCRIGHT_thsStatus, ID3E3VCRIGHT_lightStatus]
BO_ 899 ID383VCRIGHT_thsStatus: 8 VehicleBus
 SG_ VCRIGHT_estimatedThsSolarLoad : 53|10@1+ (1,0) [0|1022] "W/m2"  Receiver
 SG_ VCRIGHT_estimatedVehicleSituation : 31|2@1+ (1,0) [0|2] ""  Receiver
 SG_ VCRIGHT_thsActive : 0|1@1+ (1,0) [0|1] ""  Receiver
 SG_ VCRIGHT_thsHumidity : 17|8@1+ (1,0) [0|100] "%"  Receiver
 SG_ VCRIGHT_thsSolarLoadInfrared : 33|10@1+ (1,0) [0|1022] "W/m2"  Receiver
 SG_ VCRIGHT_thsSolarLoadVisible : 43|10@1+ (1,0) [0|1022] "W/m2"  Receiver
 SG_ VCRIGHT_thsTemperature : 1|8@1- (1,-40) [-40|150] "C"  Receiver

BO_ 915 ID393VCRIGHT_epbmDebug: 8 VehicleBus
 SG_ VCRIGHT_epbmDebugIndex M : 0|1@1+ (1,0) [0|1] ""  Receiver
 SG_ VCRIGHT_cdpEnumDummy m1 : 24|2@1+ (1,0) [0|2] ""  Receiver
 SG_ VCRIGHT_epbFaultStatus m0 : 58|2@1+ (1,0) [0|3] ""  Receiver
 SG_ VCRIGHT_epbMotorCurrent m0 : 5|11@1+ (0.01,0) [0|20.47] "A"  Receiver
 SG_ VCRIGHT_epbSummonState m0 : 45|3@1+ (1,0) [0|6] ""  Receiver
 SG_ VCRIGHT_epbUnitStatus m0 : 51|5@1+ (1,0) [0|22] ""  Receiver
 SG_ VCRIGHT_epbmApplyVoltage m0 : 16|11@1+ (0.01,0) [0|20.47] "A"  Receiver
 SG_ VCRIGHT_epbmCaliperState m0 : 1|3@1+ (1,0) [0|6] ""  Receiver
 SG_ VCRIGHT_epbmDynApplyingAllowed m1 : 9|1@1+ (1,0) [0|1] ""  Receiver
 SG_ VCRIGHT_epbmDynamicAllowed m1 : 2|1@1+ (1,0) [0|1] ""  Receiver
 SG_ VCRIGHT_epbmFaultAllowed m1 : 11|1@1+ (1,0) [0|1] ""  Receiver
 SG_ VCRIGHT_epbmFaultStatus m0 : 56|2@1+ (1,0) [0|3] ""  ui
 SG_ VCRIGHT_epbmMotorEnabled m0 : 4|1@1+ (1,0) [0|1] ""  Receiver
 SG_ VCRIGHT_epbmOpenAllowed m1 : 1|1@1+ (1,0) [0|1] ""  Receiver
 SG_ VCRIGHT_epbmParkAllowed m1 : 3|1@1+ (1,0) [0|1] ""  Receiver
 SG_ VCRIGHT_epbmParkingAllowed m1 : 8|1@1+ (1,0) [0|1] ""  Receiver
 SG_ VCRIGHT_epbmReleaseVoltage m0 : 27|11@1+ (0.01,0) [0|20.47] "A"  Receiver
 SG_ VCRIGHT_epbmReleasingAllowed m1 : 10|1@1+ (1,0) [0|1] ""  Receiver
 SG_ VCRIGHT_epbmServiceAllowed m1 : 5|1@1+ (1,0) [0|1] ""  Receiver
 SG_ VCRIGHT_epbmStartAllowed m1 : 4|1@1+ (1,0) [0|1] ""  Receiver
 SG_ VCRIGHT_epbmSummonAllowed m1 : 12|1@1+ (1,0) [0|1] ""  Receiver
 SG_ VCRIGHT_epbmSummonParkAllowed m1 : 13|1@1+ (1,0) [0|1] ""  Receiver
 SG_ VCRIGHT_epbmSummonReleaseAllowed m1 : 14|1@1+ (1,0) [0|1] ""  Receiver
 SG_ VCRIGHT_epbmSummonState m0 : 48|3@1+ (1,0) [0|6] ""  Receiver
 SG_ VCRIGHT_epbmSystemStatus m0 : 60|4@1+ (1,0) [0|8] ""  Receiver
 SG_ VCRIGHT_epbmUnknownAllowed m1 : 16|1@1+ (1,0) [0|1] ""  Receiver
 SG_ VCRIGHT_epbmWinchAllowed m1 : 6|1@1+ (1,0) [0|1] ""  Receiver
 SG_ VCRIGHT_epbmWinchReleaseAllowed m1 : 7|1@1+ (1,0) [0|1] ""  Receiver
 SG_ VCRIGHT_summonActiveAllowed m1 : 19|1@1+ (1,0) [0|1] ""  Receiver
 SG_ VCRIGHT_summonArmedAllowed m1 : 18|1@1+ (1,0) [0|1] ""  Receiver
 SG_ VCRIGHT_summonCompleteAllowed m1 : 20|1@1+ (1,0) [0|1] ""  Receiver
 SG_ VCRIGHT_summonFaultAllowed m1 : 21|1@1+ (1,0) [0|1] ""  Receiver
 SG_ VCRIGHT_summonFaultReason m0 : 40|5@1+ (1,0) [0|28] ""  Receiver
 SG_ VCRIGHT_summonIdleAllowed m1 : 17|1@1+ (1,0) [0|1] ""  Receiver
 SG_ VCRIGHT_summonInitAllowed m1 : 15|1@1+ (1,0) [0|1] ""  Receiver
 SG_ VCRIGHT_summonUnavailableAllowed m1 : 22|1@1+ (1,0) [0|1] ""  Receiver

BO_ 947 ID3B3UI_vehicleControl2: 4 VehicleBus
 SG_ UI_PINToDriveEnabled : 6|1@1+ (1,0) [0|1] ""  Receiver
 SG_ UI_PINToDrivePassed : 7|1@1+ (1,0) [0|1] ""  Receiver
 SG_ UI_UMCUpdateInhibit : 2|1@1+ (1,0) [0|1] ""  Receiver
 SG_ UI_VCLEFTFeature1 : 15|1@1+ (1,0) [0|1] ""  Receiver
 SG_ UI_VCSECFeature1 : 14|1@1+ (1,0) [0|1] ""  Receiver
 SG_ UI_WCUpdateInhibit : 3|1@1+ (1,0) [0|1] ""  Receiver
 SG_ UI_alarmTriggerRequest : 13|1@1+ (1,0) [0|1] ""  Receiver
 SG_ UI_autoRollWindowsOnLockEnable : 29|1@1+ (1,0) [0|1] ""  Receiver
 SG_ UI_autopilotPowerStateRequest : 25|2@1+ (1,0) [0|2] ""  Receiver
 SG_ UI_batteryPreconditioningRequest : 23|1@1+ (1,0) [0|1] ""  Receiver
 SG_ UI_coastDownMode : 24|1@1+ (1,0) [0|1] ""  Receiver
 SG_ UI_efuseMXResistanceEstArmed : 30|1@1+ (1,0) [0|1] ""  Receiver
 SG_ UI_freeRollModeRequest : 19|1@1+ (1,0) [0|1] ""  Receiver
 SG_ UI_gloveboxRequest : 0|1@1+ (1,0) [0|1] ""  Receiver
 SG_ UI_lightSwitch : 9|3@1+ (1,0) [0|4] ""  Receiver
 SG_ UI_locksPanelActive : 5|1@1+ (1,0) [0|1] ""  Receiver
 SG_ UI_readyToAddKey : 12|1@1+ (1,0) [0|1] ""  Receiver
 SG_ UI_shorted12VCellTestMode : 27|2@1+ (1,0) [0|2] ""  Receiver
 SG_ UI_soundHornOnLock : 4|1@1+ (1,0) [0|1] ""  Receiver
 SG_ UI_summonState : 16|2@1+ (1,0) [0|3] ""  Receiver
 SG_ UI_trunkRequest : 1|1@1+ (1,0) [0|1] ""  Receiver
 SG_ UI_userPresent : 18|1@1+ (1,0) [0|1] ""  Receiver
 SG_ UI_windowRequest : 20|3@1+ (1,0) [0|4] ""  Receiver

BO_ 963 ID3C3VCRIGHT_switchStatus: 7 VehicleBus
 SG_ VCRIGHT_2RowSeatReclineSwitch : 54|1@1+ (1,0) [0|1] ""  Receiver
 SG_ VCRIGHT_btnWindowAutoDownRF : 27|1@1+ (1,0) [0|1] ""  Receiver
 SG_ VCRIGHT_btnWindowAutoDownRR : 31|1@1+ (1,0) [0|1] ""  Receiver
 SG_ VCRIGHT_btnWindowAutoUpRF : 25|1@1+ (1,0) [0|1] ""  Receiver
 SG_ VCRIGHT_btnWindowAutoUpRR : 29|1@1+ (1,0) [0|1] ""  Receiver
 SG_ VCRIGHT_btnWindowDownRF : 26|1@1+ (1,0) [0|1] ""  Receiver
 SG_ VCRIGHT_btnWindowDownRR : 30|1@1+ (1,0) [0|1] ""  Receiver
 SG_ VCRIGHT_btnWindowSwPackAutoDwnLF : 35|1@1+ (1,0) [0|1] ""  Receiver
 SG_ VCRIGHT_btnWindowSwPackAutoDwnLR : 39|1@1+ (1,0) [0|1] ""  Receiver
 SG_ VCRIGHT_btnWindowSwPackAutoDwnRR : 52|1@1+ (1,0) [0|1] ""  Receiver
 SG_ VCRIGHT_btnWindowSwPackAutoUpLF : 33|1@1+ (1,0) [0|1] ""  Receiver
 SG_ VCRIGHT_btnWindowSwPackAutoUpLR : 37|1@1+ (1,0) [0|1] ""  Receiver
 SG_ VCRIGHT_btnWindowSwPackAutoUpRR : 50|1@1+ (1,0) [0|1] ""  Receiver
 SG_ VCRIGHT_btnWindowSwPackDownLF : 34|1@1+ (1,0) [0|1] ""  Receiver
 SG_ VCRIGHT_btnWindowSwPackDownLR : 38|1@1+ (1,0) [0|1] ""  Receiver
 SG_ VCRIGHT_btnWindowSwPackDownRR : 51|1@1+ (1,0) [0|1] ""  Receiver
 SG_ VCRIGHT_btnWindowSwPackUpLF : 32|1@1+ (1,0) [0|1] ""  Receiver
 SG_ VCRIGHT_btnWindowSwPackUpLR : 36|1@1+ (1,0) [0|1] ""  Receiver
 SG_ VCRIGHT_btnWindowSwPackUpRR : 49|1@1+ (1,0) [0|1] ""  Receiver
 SG_ VCRIGHT_btnWindowUpRF : 24|1@1+ (1,0) [0|1] ""  Receiver
 SG_ VCRIGHT_btnWindowUpRR : 28|1@1+ (1,0) [0|1] ""  Receiver
 SG_ VCRIGHT_frontBuckleSwitch : 40|2@1+ (1,0) [0|3] ""  Receiver
 SG_ VCRIGHT_frontOccupancySwitch : 42|2@1+ (1,0) [0|3] ""  Receiver
 SG_ VCRIGHT_frontSeatBackrestBack : 12|2@1+ (1,0) [0|3] ""  Receiver
 SG_ VCRIGHT_frontSeatBackrestForward : 14|2@1+ (1,0) [0|3] ""  Receiver
 SG_ VCRIGHT_frontSeatLiftDown : 8|2@1+ (1,0) [0|3] ""  Receiver
 SG_ VCRIGHT_frontSeatLiftUp : 10|2@1+ (1,0) [0|3] ""  Receiver
 SG_ VCRIGHT_frontSeatLumbarDown : 16|2@1+ (1,0) [0|3] ""  Receiver
 SG_ VCRIGHT_frontSeatLumbarIn : 20|2@1+ (1,0) [0|3] ""  Receiver
 SG_ VCRIGHT_frontSeatLumbarOut : 22|2@1+ (1,0) [0|3] ""  Receiver
 SG_ VCRIGHT_frontSeatLumbarUp : 18|2@1+ (1,0) [0|3] ""  Receiver
 SG_ VCRIGHT_frontSeatTiltDown : 4|2@1+ (1,0) [0|3] ""  Receiver
 SG_ VCRIGHT_frontSeatTiltUp : 6|2@1+ (1,0) [0|3] ""  Receiver
 SG_ VCRIGHT_frontSeatTrackBack : 0|2@1+ (1,0) [0|3] ""  Receiver
 SG_ VCRIGHT_frontSeatTrackForward : 2|2@1+ (1,0) [0|3] ""  Receiver
 SG_ VCRIGHT_liftgateShutfaceSwitchPr : 53|1@1+ (1,0) [0|1] ""  Receiver
 SG_ VCRIGHT_rearCenterBuckleSwitch : 44|2@1+ (1,0) [0|3] ""  Receiver
 SG_ VCRIGHT_rearRightBuckleSwitch : 46|2@1+ (1,0) [0|3] ""  Receiver
 SG_ VCRIGHT_trunkExtReleasePressed : 48|1@1+ (1,0) [0|1] ""  Receiver

BO_ 995 ID3E3VCRIGHT_lightStatus: 2 VehicleBus
 SG_ VCRIGHT_brakeLightStatus : 0|2@1+ (1,0) [0|3] ""  Receiver
 SG_ VCRIGHT_interiorTrunkLightStatus : 10|2@1+ (1,0) [0|3] ""  Receiver
 SG_ VCRIGHT_rearFogLightStatus : 8|2@1+ (1,0) [0|3] ""  Receiver
 SG_ VCRIGHT_reverseLightStatus : 6|2@1+ (1,0) [0|3] ""  Receiver
 SG_ VCRIGHT_tailLightStatus : 2|2@1+ (1,0) [0|3] ""  Receiver
 SG_ VCRIGHT_turnSignalStatus : 4|2@1+ (1,0) [0|3] ""  Receiver

BO_ 1622 ID656FrontDIinfo: 8 VehicleBus
 SG_ DIF_infoIndex M : 0|8@1+ (1,0) [0|255] ""  Receiver
 SG_ DIF_FPGA_version m16 : 48|8@1+ (1,0) [0|255] ""  Receiver
 SG_ DIF_appGitHash m17 : 8|56@1+ (1,0) [0|7.20575940379279E+016] ""  Receiver
 SG_ DIF_applicationCrc m13 : 32|32@1+ (1,0) [0|4294967295] ""  Receiver
 SG_ DIF_assemblyId m11 : 24|8@1+ (1,0) [0|255] ""  Receiver
 SG_ DIF_bootGitHash m18 : 8|56@1+ (1,0) [0|7.20575940379279E+016] ""  Receiver
 SG_ DIF_bootloaderCrc m20 : 32|32@1+ (1,0) [0|4294967295] ""  Receiver
 SG_ DIF_buildConfigurationId m10 : 16|16@1+ (1,0) [0|65535] ""  Receiver
 SG_ DIF_buildType m10 : 8|3@1+ (1,0) [0|4] ""  Receiver
 SG_ DIF_componentId m10 : 48|16@1+ (1,0) [0|65535] ""  Receiver
 SG_ DIF_hardwareId m10 : 32|8@1+ (1,0) [0|252] ""  Receiver
 SG_ DIF_infoBootLdUdsProtocolVersion m20 : 8|8@1+ (1,0) [0|255] ""  Receiver
 SG_ DIF_oilPumpAppCrc m16 : 16|32@1+ (1,0) [0|4294967295] ""  Receiver
 SG_ DIF_oilPumpBuildType m16 : 8|3@1+ (1,0) [0|4] ""  Receiver
 SG_ DIF_pcbaId m11 : 16|8@1+ (1,0) [0|255] ""  Receiver
 SG_ DIF_platformTyp m19 : 8|8@1+ (1,0) [0|255] ""  Receiver
 SG_ DIF_subUsageId m11 : 48|16@1+ (1,0) [0|65535] ""  Receiver
 SG_ DIF_subcomponentGitHash m31 : 8|56@1+ (1,0) [0|7.20575940379279E+016] ""  Receiver
 SG_ DIF_usageId m11 : 32|16@1+ (1,0) [0|65535] ""  Receiver

BO_ 768 ID300BMS_info: 8 VehicleBus
 SG_ BMS_infoIndex M : 0|8@1+ (1,0) [0|255] ""  Receiver
 SG_ BMS_appCrc m13 : 32|32@1+ (1,0) [0|4294967295] ""  Receiver
 SG_ BMS_appGitHash m17 : 8|56@1+ (1,0) [0|7.20575940379279E+016] ""  Receiver
 SG_ BMS_assemblyId m11 : 24|8@1+ (1,0) [0|255] ""  Receiver
 SG_ BMS_bootCrc m20 : 32|32@1+ (1,0) [0|4294967295] ""  Receiver
 SG_ BMS_bootGitHash m18 : 8|56@1+ (1,0) [0|7.20575940379279E+016] ""  Receiver
 SG_ BMS_bootUdsProtoVersion m20 : 8|8@1+ (1,0) [0|255] ""  Receiver
 SG_ BMS_buildConfigId m10 : 16|16@1+ (1,0) [0|65535] ""  Receiver
 SG_ BMS_buildType m10 : 8|3@1+ (1,0) [0|4] ""  Receiver
 SG_ BMS_componentId m10 : 48|16@1+ (1,0) [0|65535] ""  Receiver
 SG_ BMS_hardwareId m10 : 32|16@1+ (1,0) [0|65535] ""  Receiver
 SG_ BMS_pcbaId m11 : 16|8@1+ (1,0) [0|255] ""  Receiver
 SG_ BMS_platformType m13 : 8|8@1+ (1,0) [0|255] ""  Receiver
 SG_ BMS_subUsageId m11 : 48|16@1+ (1,0) [0|65535] ""  Receiver
 SG_ BMS_usageId m11 : 32|16@1+ (1,0) [0|65535] ""  Receiver

BO_ 530 ID212BMS_status: 8 VehicleBus
 SG_ BMS_activeHeatingWorthwhile : 5|1@1+ (1,0) [0|1] ""  Receiver
 SG_ BMS_chargeRequest : 29|1@1+ (1,0) [0|1] ""  Receiver
 SG_ BMS_chargeRetryCount : 51|3@1+ (1,0) [0|7] ""  Receiver
 SG_ BMS_chgPowerAvailable : 40|11@1+ (0.125,0) [0|255.75] "kW"  Receiver
 SG_ BMS_contactorState : 8|3@1+ (1,0) [0|6] ""  Receiver
 SG_ BMS_cpMiaOnHvs : 6|1@1+ (1,0) [0|1] ""  Receiver
 SG_ BMS_diLimpRequest : 36|1@1+ (1,0) [0|1] ""  Receiver
 SG_ BMS_ecuLogUploadRequest : 14|2@1+ (1,0) [0|3] ""  Receiver
 SG_ BMS_hvState : 16|3@1+ (1,0) [0|6] ""  Receiver
 SG_ BMS_hvacPowerRequest : 0|1@1+ (1,0) [0|1] ""  Receiver
 SG_ BMS_isolationResistance : 19|10@1+ (10,0) [0|10000] "kOhm"  Receiver
 SG_ BMS_keepWarmRequest : 30|1@1+ (1,0) [0|1] ""  Receiver
 SG_ BMS_notEnoughPowerForDrive : 1|1@1+ (1,0) [0|1] ""  Receiver
 SG_ BMS_notEnoughPowerForSupport : 2|1@1+ (1,0) [0|1] ""  Receiver
 SG_ BMS_okToShipByAir : 37|1@1+ (1,0) [0|1] ""  Receiver
 SG_ BMS_okToShipByLand : 38|1@1+ (1,0) [0|1] ""  Receiver
 SG_ BMS_pcsPwmEnabled : 7|1@1+ (1,0) [0|1] ""  Receiver
 SG_ BMS_preconditionAllowed : 3|1@1+ (1,0) [0|1] ""  Receiver
 SG_ BMS_smStateRequest : 56|4@1+ (1,0) [0|9] ""  Receiver
 SG_ BMS_state : 32|4@1+ (1,0) [0|10] ""  Receiver
 SG_ BMS_uiChargeStatus : 11|3@1+ (1,0) [0|5] ""  Receiver
 SG_ BMS_updateAllowed : 4|1@1+ (1,0) [0|1] ""  Receiver

BO_ 946 ID3B2BMS_log2: 8 VehicleBus
 SG_ BMS_log2MuxId M : 0|5@1+ (1,0) [0|25] ""  Receiver
 SG_ BMS_100HzTask_avgExecTime m9 : 6|14@1+ (1,0) [0|16383] "us"  Receiver
 SG_ BMS_100HzTask_maxExecTime m9 : 32|14@1+ (1,0) [0|16383] "us"  Receiver
 SG_ BMS_10HzTask_avgExecTime m8 : 6|17@1+ (1,0) [0|131071] "us"  Receiver
 SG_ BMS_10HzTask_maxExecTime m8 : 32|17@1+ (1,0) [0|131071] "us"  Receiver
 SG_ BMS_1HzTask_avgExecTime m7 : 6|20@1+ (1,0) [0|1048575] "us"  Receiver
 SG_ BMS_1HzTask_maxExecTime m7 : 32|20@1+ (1,0) [0|1048575] "us"  Receiver
 SG_ BMS_1kHzTask_avgExecTime m9 : 20|11@1+ (1,0) [0|2047] "us"  Receiver
 SG_ BMS_1kHzTask_maxExecTime m9 : 48|11@1+ (1,0) [0|2047] "us"  Receiver
 SG_ BMS_ahChargeTotal m6 : 8|24@1+ (0.1,0) [0|1677721.5] "Ah"  Receiver
 SG_ BMS_ahDischargeTotal m6 : 32|24@1+ (0.1,0) [0|1677721.5] "Ah"  Receiver
 SG_ BMS_cacAvg m0 : 6|13@1+ (0.1,0) [0|819.1] "Ah"  Receiver
 SG_ BMS_cacMax m0 : 40|13@1+ (0.1,0) [0|819.1] "Ah"  Receiver
 SG_ BMS_cacMaxBrickId m0 : 56|7@1+ (1,1) [1|128] ""  Receiver
 SG_ BMS_cacMaxKalmanError m1 : 44|10@1+ (0.01,0) [0|10] "Ah"  Receiver
 SG_ BMS_cacMin m0 : 19|13@1+ (0.1,0) [0|819.1] "Ah"  Receiver
 SG_ BMS_cacMinBrickId m0 : 32|7@1+ (1,1) [1|128] ""  Receiver
 SG_ BMS_cacMinDeltaAh m23 : 26|11@1- (0.5,0) [-512|511.5] "Ah"  Receiver
 SG_ BMS_cacMinLowerBoundEst m1 : 5|13@1+ (0.1,0) [0|819.1] "Ah"  Receiver
 SG_ BMS_cacMinRawEstimate m1 : 18|13@1+ (0.1,0) [0|819.1] "Ah"  Receiver
 SG_ BMS_cacMinSocByOcvEnd m23 : 16|10@1+ (0.1,0) [0|100] "%"  Receiver
 SG_ BMS_cacMinSocByOcvStart m23 : 6|10@1+ (0.1,0) [0|100] "%"  Receiver
 SG_ BMS_cacMinUpdateAhError m23 : 37|9@1- (0.05,0) [-12.8|12.75] "Ah"  Receiver
 SG_ BMS_cacMinUpperBoundEst m1 : 31|13@1+ (0.1,0) [0|819.1] "Ah"  Receiver
 SG_ BMS_capacityImbalancePct m1 : 54|10@1+ (0.1,0) [0|102.3] "%"  Receiver
 SG_ BMS_chargeCurrentLimitMode m5 : 32|3@1+ (1,0) [0|6] ""  Receiver
 SG_ BMS_chargeNeededReason m5 : 35|3@1+ (1,0) [0|6] ""  Receiver
 SG_ BMS_chgEndBatteryChargeRequest m3 : 28|1@1+ (1,0) [0|1] ""  Receiver
 SG_ BMS_chgEndBmsHvChargeStatus m3 : 16|3@1+ (1,0) [0|7] ""  Receiver
 SG_ BMS_chgEndChargeState m3 : 12|3@1+ (1,0) [0|7] ""  Receiver
 SG_ BMS_chgEndCpHvChargeStatus m3 : 19|3@1+ (1,0) [0|6] ""  Receiver
 SG_ BMS_chgEndCpShutdownRequest m3 : 24|2@1+ (1,0) [0|2] ""  Receiver
 SG_ BMS_chgEndDcEvseCompatible m3 : 29|1@1+ (1,0) [0|1] ""  Receiver
 SG_ BMS_chgEndDisableUnderFailure m3 : 30|1@1+ (1,0) [0|1] ""  Receiver
 SG_ BMS_chgEndEvseChargeType m3 : 6|2@1+ (1,0) [0|2] ""  Receiver
 SG_ BMS_chgEndPcsHvChargeStatus m3 : 22|2@1+ (1,0) [0|3] ""  Receiver
 SG_ BMS_chgEndPcsShutdownRequest m3 : 26|2@1+ (1,0) [0|2] ""  Receiver
 SG_ BMS_chgRequestTerminatedCount m3 : 8|4@1+ (1,0) [0|15] ""  Receiver
 SG_ BMS_cpChargeStatus m5 : 60|3@1+ (1,0) [0|5] ""  Receiver
 SG_ BMS_currentReg_targetI m5 : 49|11@1+ (0.5,0) [0|1023.5] "A"  Receiver
 SG_ BMS_dynamicEnergyBuffer m22 : 30|10@1+ (0.1,0) [0|102.2] "KWh"  Receiver
 SG_ BMS_energyReserveAvg m20 : 48|16@1+ (0.001,0) [0|65.535] "V"  Receiver
 SG_ BMS_energyReserveMax m20 : 32|16@1+ (0.001,0) [0|65.535] "V"  Receiver
 SG_ BMS_energyReserveMin m20 : 16|16@1+ (0.001,0) [0|65.535] "V"  Receiver
 SG_ BMS_fcLinkTestDecayTime m21 : 8|10@1+ (2,0) [0|2044] "mS"  Receiver
 SG_ BMS_fcLinkTestTimeSinceLastRun m21 : 18|12@1+ (0.01758241758,0) [0|71.99] "Hours"  Receiver
 SG_ BMS_floodPortState1 m2 : 10|3@1+ (1,0) [0|4] ""  Receiver
 SG_ BMS_floodPortState2 m2 : 13|3@1+ (1,0) [0|4] ""  Receiver
 SG_ BMS_floodPortV1 m2 : 16|16@1+ (0.001,0) [0|65.535] "V"  Receiver
 SG_ BMS_floodPortV2 m2 : 32|16@1+ (0.001,0) [0|65.535] "V"  Receiver
 SG_ BMS_hvChain_iLimit m19 : 9|14@1+ (0.128,0) [0|2096.896] "A"  Receiver
 SG_ BMS_hvChain_limitingState m19 : 24|5@1+ (1,0) [0|31] ""  Receiver
 SG_ BMS_hvChain_limitingStateTempera m19 : 32|16@1- (0.01,0) [-327.68|327.67] "C"  Receiver
 SG_ BMS_hvChain_useLeakyBucket m19 : 8|1@1+ (1,0) [0|1] ""  Receiver
 SG_ BMS_idealEnergyFloor m22 : 20|10@1+ (0.1,0) [0|102.2] "KWh"  Receiver
 SG_ BMS_loadReg_output m5 : 6|11@1- (0.1,0) [-102.4|102.3] "A"  Receiver
 SG_ BMS_maxDcCurrentAvailable m5 : 38|11@1+ (0.5,0) [0|1023.5] "A"  Receiver
 SG_ BMS_negCtrCommonModeRejError m18 : 6|13@1- (2.442592959E-005,0) [-0.1|0.1] "-"  Receiver
 SG_ BMS_negCtrCommonModeRejErrorConf m18 : 19|13@1+ (1.22100107191684,0) [0|10000] "-"  Receiver
 SG_ BMS_negCtrDeviationConfidenceMax m15 : 45|13@1+ (0.000122100107192,0) [0|1] "-"  Receiver
 SG_ BMS_negCtrDeviationConfidenceMin m15 : 32|13@1+ (0.000122100107192,0) [0|1] "-"  Receiver
 SG_ BMS_negCtrDeviationFiltConfMax m16 : 45|13@1+ (0.000122100107192,0) [0|1] "-"  Receiver
 SG_ BMS_negCtrDeviationFiltConfMin m16 : 32|13@1+ (0.000122100107192,0) [0|1] "-"  Receiver
 SG_ BMS_negCtrDeviationFiltMax m16 : 19|13@1- (0.001221299164314,0) [-5|5] "V"  Receiver
 SG_ BMS_negCtrDeviationFiltMin m16 : 6|13@1- (0.001221299164314,0) [-5|5] "V"  Receiver
 SG_ BMS_negCtrDeviationMax m15 : 19|13@1- (0.001221299164314,0) [-5|5] "V"  Receiver
 SG_ BMS_negCtrDeviationMin m15 : 6|13@1- (0.001221299164314,0) [-5|5] "V"  Receiver
 SG_ BMS_negCtrDropCorrectedFiltMax m17 : 45|13@1- (0.001221299164314,0) [-5|5] "V"  Receiver
 SG_ BMS_negCtrDropCorrectedFiltMin m17 : 32|13@1- (0.001221299164314,0) [-5|5] "V"  Receiver
 SG_ BMS_negCtrDropCorrectedMax m17 : 19|13@1- (0.001221299164314,0) [-5|5] "V"  Receiver
 SG_ BMS_negCtrDropCorrectedMin m17 : 6|13@1- (0.001221299164314,0) [-5|5] "V"  Receiver
 SG_ BMS_negCtrOffsetError m18 : 32|13@1- (0.001221299164314,0) [-5|5] "V"  Receiver
 SG_ BMS_negCtrOffsetErrorConf m18 : 45|13@1+ (0.000122100107192,0) [0|1] "-"  Receiver
 SG_ BMS_negCtrResistance m10 : 32|13@1- (2.442598329E-006,0) [-0.01|0.01] "Ohm"  Receiver
 SG_ BMS_negCtrResistanceConfidence m10 : 45|13@1+ (12.2100107191684,0) [0|100000] "-"  Receiver
 SG_ BMS_offsetReg_output m5 : 17|14@1- (0.1,0) [-819.2|819.1] "A"  Receiver
 SG_ BMS_packRestTime m22 : 8|12@1+ (0.01758241758,0) [0|71.99] "Hours"  Receiver
 SG_ BMS_pcsPrechargeRequestActive m21 : 30|1@1+ (1,0) [0|1] ""  Receiver
 SG_ BMS_pcsPrechargeTargetVoltage m21 : 32|16@1- (0.1,0) [-3276.8|3276.7] "V"  Receiver
 SG_ BMS_posCtrCommonModeRejError m14 : 6|13@1- (2.4425983286E-005,0) [-0.1|0.1] "-"  Receiver
 SG_ BMS_posCtrCommonModeRejErrorConf m14 : 19|13@1+ (1.22100107191684,0) [0|10000] "-"  Receiver
 SG_ BMS_posCtrDeviationConfidenceMax m11 : 45|13@1+ (0.000122100107192,0) [0|1] "-"  Receiver
 SG_ BMS_posCtrDeviationConfidenceMin m11 : 32|13@1+ (0.000122100107192,0) [0|1] "-"  Receiver
 SG_ BMS_posCtrDeviationFiltConfMax m12 : 45|13@1+ (0.000122100107192,0) [0|1] "-"  Receiver
 SG_ BMS_posCtrDeviationFiltConfMin m12 : 32|13@1+ (0.000122100107192,0) [0|1] "-"  Receiver
 SG_ BMS_posCtrDeviationFiltMax m12 : 19|13@1- (0.001221299164314,0) [-5|5] "V"  Receiver
 SG_ BMS_posCtrDeviationFiltMin m12 : 6|13@1- (0.001221299164314,0) [-5|5] "V"  Receiver
 SG_ BMS_posCtrDeviationMax m11 : 19|13@1- (0.001221299164314,0) [-5|5] "V"  Receiver
 SG_ BMS_posCtrDeviationMin m11 : 6|13@1- (0.001221299164314,0) [-5|5] "V"  Receiver
 SG_ BMS_posCtrDropCorrectedFiltMax m13 : 45|13@1- (0.001221299164314,0) [-5|5] "V"  Receiver
 SG_ BMS_posCtrDropCorrectedFiltMin m13 : 32|13@1- (0.001221299164314,0) [-5|5] "V"  Receiver
 SG_ BMS_posCtrDropCorrectedMax m13 : 19|13@1- (0.001221299164314,0) [-5|5] "V"  Receiver
 SG_ BMS_posCtrDropCorrectedMin m13 : 6|13@1- (0.001221299164314,0) [-5|5] "V"  Receiver
 SG_ BMS_posCtrOffsetError m14 : 32|13@1- (0.001221299164314,0) [-5|5] "V"  Receiver
 SG_ BMS_posCtrOffsetErrorConf m14 : 45|13@1+ (0.000122100107192,0) [0|1] "-"  Receiver
 SG_ BMS_posCtrResistance m10 : 6|13@1- (2.442598329E-006,0) [-0.01|0.01] "Ohm"  Receiver
 SG_ BMS_posCtrResistanceConfidence m10 : 19|13@1+ (12.2100107191684,0) [0|100000] "-"  Receiver
 SG_ BMS_vChangeWindowChangeInitV m24 : 38|12@1+ (0.002,0) [0|5] "V"  Receiver
 SG_ BMS_vChangeWindowChangeIsOutlier m24 : 50|1@1+ (1,0) [0|1] ""  Receiver
 SG_ BMS_vChangeWindowMaxVChange m24 : 25|6@1+ (0.0025,0) [0|0.15] "V"  Receiver
 SG_ BMS_vChangeWindowMaxVChangeId m24 : 31|7@1+ (1,1) [1|128] ""  Receiver
 SG_ BMS_vChangeWindowMinBrickV m24 : 6|12@1+ (0.002,0) [0|5] "V"  Receiver
 SG_ BMS_vChangeWindowMinBrickVId m24 : 18|7@1+ (1,1) [1|128] ""  Receiver
 SG_ BMS_vChangeWindowNumOutlierChang m24 : 58|6@1+ (1,0) [0|63] ""  Receiver
 SG_ BMS_vChangeWindowTimeAfterWake m24 : 51|7@1+ (0.1,0) [0|12] "sec"  Receiver
 SG_ BMS_vshTestMaxDeltaV m4 : 16|8@1+ (0.002,0) [0|0.5] "V"  Receiver
 SG_ BMS_vshTestMaxDeltaVBrickID m4 : 24|7@1+ (1,1) [1|128] ""  Receiver
 SG_ BMS_vshTestMinDeltaV m4 : 32|8@1+ (0.002,0) [0|0.5] "V"  Receiver
 SG_ BMS_vshTestMinDeltaVBrickID m4 : 40|7@1+ (1,1) [1|128] ""  Receiver
 SG_ BMS_maxSocChange m25 : 5|11@1- (0.1,0) [-100|100] "%"  Receiver
 SG_ BMS_maxSocChangeBrickId m25 : 16|7@1+ (1,1) [1|108] ""  Receiver
 SG_ BMS_socChangeSocByOcvMax m25 : 34|10@1+ (0.1,0) [0|100] "%"  Receiver
 SG_ BMS_socChangeSocByOcvMin m25 : 24|10@1+ (0.1,0) [0|100] "%"  Receiver

BO_ 800 ID320BMS_alertMatrix: 8 VehicleBus
 SG_ BMS_matrixIndex M : 0|4@1+ (1,0) [0|15] ""  Receiver
 SG_ BMS_a001_Pack_Config_Mismatch m0 : 4|1@1+ (1,0) [0|1] ""  Receiver
 SG_ BMS_a007_SW_Slowed_Chg_Batt_Cold m0 : 10|1@1+ (1,0) [0|1] ""  Receiver
 SG_ BMS_a016_Pack_Module_Id_Mismatch m0 : 19|1@1+ (1,0) [0|1] ""  Receiver
 SG_ BMS_a017_SW_Brick_OV m0 : 20|1@1+ (1,0) [0|1] ""  Receiver
 SG_ BMS_a018_SW_Brick_UV m0 : 21|1@1+ (1,0) [0|1] ""  Receiver
 SG_ BMS_a019_SW_Module_OT m0 : 22|1@1+ (1,0) [0|1] ""  Receiver
 SG_ BMS_a021_SW_Dr_Limits_Regulation m0 : 24|1@1+ (1,0) [0|1] ""  Receiver
 SG_ BMS_a022_SW_Over_Current m0 : 25|1@1+ (1,0) [0|1] ""  Receiver
 SG_ BMS_a023_SW_Stack_OV m0 : 26|1@1+ (1,0) [0|1] ""  Receiver
 SG_ BMS_a024_SW_Islanded_Brick m0 : 27|1@1+ (1,0) [0|1] ""  Receiver
 SG_ BMS_a025_SW_PwrBalance_Anomaly m0 : 28|1@1+ (1,0) [0|1] ""  Receiver
 SG_ BMS_a026_SW_HFCurrent_Anomaly m0 : 29|1@1+ (1,0) [0|1] ""  Receiver
 SG_ BMS_a034_SW_Passive_Isolation m0 : 37|1@1+ (1,0) [0|1] ""  Receiver
 SG_ BMS_a035_SW_Isolation m0 : 38|1@1+ (1,0) [0|1] ""  Receiver
 SG_ BMS_a036_SW_HvpHvilFault m0 : 39|1@1+ (1,0) [0|1] ""  Receiver
 SG_ BMS_a037_SW_Flood_Port_Open m0 : 40|1@1+ (1,0) [0|1] ""  Receiver
 SG_ BMS_a039_SW_DC_Link_Over_Voltage m0 : 42|1@1+ (1,0) [0|1] ""  Receiver
 SG_ BMS_a040_SW_Watch_Dog_HW_Trigger m0 : 43|1@1+ (1,0) [0|1] ""  Receiver
 SG_ BMS_a041_SW_Destructive_Reset_So m0 : 44|1@1+ (1,0) [0|1] ""  Receiver
 SG_ BMS_a042_SW_MPU_Error m0 : 45|1@1+ (1,0) [0|1] ""  Receiver
 SG_ BMS_a043_SW_Watch_Dog_Reset m0 : 46|1@1+ (1,0) [0|1] ""  Receiver
 SG_ BMS_a044_SW_Assertion m0 : 47|1@1+ (1,0) [0|1] ""  Receiver
 SG_ BMS_a045_SW_Exception m0 : 48|1@1+ (1,0) [0|1] ""  Receiver
 SG_ BMS_a046_SW_Task_Stack_Usage m0 : 49|1@1+ (1,0) [0|1] ""  Receiver
 SG_ BMS_a047_SW_Task_Stack_Overflow m0 : 50|1@1+ (1,0) [0|1] ""  Receiver
 SG_ BMS_a048_SW_Log_Upload_Request m0 : 51|1@1+ (1,0) [0|1] ""  Receiver
 SG_ BMS_a050_SW_Brick_Voltage_MIA m0 : 53|1@1+ (1,0) [0|1] ""  Receiver
 SG_ BMS_a051_SW_HVC_Vref_Bad m0 : 54|1@1+ (1,0) [0|1] ""  Receiver
 SG_ BMS_a052_SW_PCS_MIA m0 : 55|1@1+ (1,0) [0|1] ""  Receiver
 SG_ BMS_a054_SW_Ver_Supply_Fault m0 : 57|1@1+ (1,0) [0|1] ""  Receiver
 SG_ BMS_a055_SW_HvChain_Model_Fault m0 : 58|1@1+ (1,0) [0|1] ""  Receiver
 SG_ BMS_a056_SW_Standby_Supply_Fault m0 : 59|1@1+ (1,0) [0|1] ""  Receiver
 SG_ BMS_a057_SW_Bandolier_Model_Warn m0 : 60|1@1+ (1,0) [0|1] ""  Receiver
 SG_ BMS_a058_SW_Bandolier_Model_Rese m0 : 61|1@1+ (1,0) [0|1] ""  Receiver
 SG_ BMS_a059_SW_Pack_Voltage_Sensing m0 : 62|1@1+ (1,0) [0|1] ""  Receiver
 SG_ BMS_a060_SW_Leakage_Test_Failure m0 : 63|1@1+ (1,0) [0|1] ""  Receiver
 SG_ BMS_a061_SW_BrickV_Change m1 : 4|1@1+ (1,0) [0|1] ""  Receiver
 SG_ BMS_a062_SW_BrickV_Imbalance m1 : 5|1@1+ (1,0) [0|1] ""  Receiver
 SG_ BMS_a063_SW_ChargePort_Fault m1 : 6|1@1+ (1,0) [0|1] ""  Receiver
 SG_ BMS_a064_SW_SOC_Imbalance m1 : 7|1@1+ (1,0) [0|1] ""  Receiver
 SG_ BMS_a065_SW_CAC_Imbalance m1 : 8|1@1+ (1,0) [0|1] ""  Receiver
 SG_ BMS_a069_SW_Low_Power m1 : 12|1@1+ (1,0) [0|1] ""  Receiver
 SG_ BMS_a071_SW_SM_TransCon_Not_Met m1 : 14|1@1+ (1,0) [0|1] ""  Receiver
 SG_ BMS_a075_SW_Chg_Disable_Failure m1 : 18|1@1+ (1,0) [0|1] ""  Receiver
 SG_ BMS_a076_SW_Dch_While_Charging m1 : 19|1@1+ (1,0) [0|1] ""  Receiver
 SG_ BMS_a077_SW_Charger_Regulation m1 : 20|1@1+ (1,0) [0|1] ""  Receiver
 SG_ BMS_a080_SW_Pack_Ctr_Impedance m1 : 23|1@1+ (1,0) [0|1] ""  Receiver
 SG_ BMS_a081_SW_Ctr_Close_Blocked m1 : 24|1@1+ (1,0) [0|1] ""  Receiver
 SG_ BMS_a082_SW_Ctr_Force_Open m1 : 25|1@1+ (1,0) [0|1] ""  Receiver
 SG_ BMS_a083_SW_Ctr_Close_Failure m1 : 26|1@1+ (1,0) [0|1] ""  Receiver
 SG_ BMS_a084_SW_Sleep_Wake_Aborted m1 : 27|1@1+ (1,0) [0|1] ""  Receiver
 SG_ BMS_a087_SW_Feim_Test_Blocked m1 : 30|1@1+ (1,0) [0|1] ""  Receiver
 SG_ BMS_a088_SW_VcFront_MIA_InDrive m1 : 31|1@1+ (1,0) [0|1] ""  Receiver
 SG_ BMS_a089_SW_VcFront_MIA m1 : 32|1@1+ (1,0) [0|1] ""  Receiver
 SG_ BMS_a090_SW_Gateway_MIA m1 : 33|1@1+ (1,0) [0|1] ""  Receiver
 SG_ BMS_a091_SW_ChargePort_MIA m1 : 34|1@1+ (1,0) [0|1] ""  Receiver
 SG_ BMS_a092_SW_ChargePort_Mia_On_Hv m1 : 35|1@1+ (1,0) [0|1] ""  Receiver
 SG_ BMS_a094_SW_Drive_Inverter_MIA m1 : 37|1@1+ (1,0) [0|1] ""  Receiver
 SG_ BMS_a098_SW_BMB_Data_Integrity_L m1 : 41|1@1+ (1,0) [0|1] ""  Receiver
 SG_ BMS_a099_SW_BMB_Communication m1 : 42|1@1+ (1,0) [0|1] ""  Receiver
 SG_ BMS_a105_SW_One_Module_Tsense m1 : 48|1@1+ (1,0) [0|1] ""  Receiver
 SG_ BMS_a106_SW_All_Module_Tsense m1 : 49|1@1+ (1,0) [0|1] ""  Receiver
 SG_ BMS_a107_SW_Stack_Voltage_MIA m1 : 50|1@1+ (1,0) [0|1] ""  Receiver
 SG_ BMS_a121_SW_NVRAM_Config_Error m2 : 4|1@1+ (1,0) [0|1] ""  Receiver
 SG_ BMS_a122_SW_BMS_Therm_Irrational m2 : 5|1@1+ (1,0) [0|1] ""  Receiver
 SG_ BMS_a123_SW_Internal_Isolation m2 : 6|1@1+ (1,0) [0|1] ""  Receiver
 SG_ BMS_a126_SW_Thermistor_Failure m2 : 9|1@1+ (1,0) [0|1] ""  Receiver
 SG_ BMS_a127_SW_shunt_SNA m2 : 10|1@1+ (1,0) [0|1] ""  Receiver
 SG_ BMS_a128_SW_shunt_MIA m2 : 11|1@1+ (1,0) [0|1] ""  Receiver
 SG_ BMS_a129_SW_VSH_Failure m2 : 12|1@1+ (1,0) [0|1] ""  Receiver
 SG_ BMS_a130_IO_CAN_Error m2 : 13|1@1+ (1,0) [0|1] ""  Receiver
 SG_ BMS_a131_Bleed_FET_Failure m2 : 14|1@1+ (1,0) [0|1] ""  Receiver
 SG_ BMS_a132_HW_BMB_OTP_Uncorrctbl m2 : 15|1@1+ (1,0) [0|1] ""  Receiver
 SG_ BMS_a134_SW_Delayed_Ctr_Off m2 : 17|1@1+ (1,0) [0|1] ""  Receiver
 SG_ BMS_a135_HW_BMB_Diagnostics_Fail m2 : 18|1@1+ (1,0) [0|1] ""  Receiver
 SG_ BMS_a136_SW_Module_OT_Warning m2 : 19|1@1+ (1,0) [0|1] ""  Receiver
 SG_ BMS_a137_SW_Brick_UV_Warning m2 : 20|1@1+ (1,0) [0|1] ""  Receiver
 SG_ BMS_a138_SW_Brick_OV_Warning m2 : 21|1@1+ (1,0) [0|1] ""  Receiver
 SG_ BMS_a139_SW_DC_Link_V_Irrational m2 : 22|1@1+ (1,0) [0|1] ""  Receiver
 SG_ BMS_a141_SW_BMB_Status_Warning m2 : 24|1@1+ (1,0) [0|1] ""  Receiver
 SG_ BMS_a143_SW_CAC_Change m2 : 26|1@1+ (1,0) [0|1] ""  Receiver
 SG_ BMS_a144_Hvp_Config_Mismatch m2 : 27|1@1+ (1,0) [0|1] ""  Receiver
 SG_ BMS_a145_SW_SOC_Change m2 : 28|1@1+ (1,0) [0|1] ""  Receiver
 SG_ BMS_a146_SW_Brick_Overdischarged m2 : 29|1@1+ (1,0) [0|1] ""  Receiver
 SG_ BMS_a149_SW_Missing_Config_Block m2 : 32|1@1+ (1,0) [0|1] ""  Receiver
 SG_ BMS_a151_SW_external_isolation m2 : 34|1@1+ (1,0) [0|1] ""  Receiver
 SG_ BMS_a155_SW_Weak_short_impedence m2 : 38|1@1+ (1,0) [0|1] ""  Receiver
 SG_ BMS_a156_SW_BMB_Vref_bad m2 : 39|1@1+ (1,0) [0|1] ""  Receiver
 SG_ BMS_a158_SW_HVP_HVI_Comms m2 : 41|1@1+ (1,0) [0|1] ""  Receiver
 SG_ BMS_a159_SW_HVP_ECU_Error m2 : 42|1@1+ (1,0) [0|1] ""  Receiver
 SG_ BMS_a160_SW_FC_Ctr_Clean_Failed m2 : 43|1@1+ (1,0) [0|1] ""  Receiver
 SG_ BMS_a161_SW_DI_Open_Request m2 : 44|1@1+ (1,0) [0|1] ""  Receiver
 SG_ BMS_a162_SW_No_Power_For_Support m2 : 45|1@1+ (1,0) [0|1] ""  Receiver
 SG_ BMS_a163_SW_Contactor_Mismatch m2 : 46|1@1+ (1,0) [0|1] ""  Receiver
 SG_ BMS_a164_SW_Uncontrolled_Regen m2 : 47|1@1+ (1,0) [0|1] ""  Receiver
 SG_ BMS_a165_SW_Pack_Partial_Weld m2 : 48|1@1+ (1,0) [0|1] ""  Receiver
 SG_ BMS_a166_SW_Pack_Full_Weld m2 : 49|1@1+ (1,0) [0|1] ""  Receiver
 SG_ BMS_a167_SW_FC_Partial_Weld m2 : 50|1@1+ (1,0) [0|1] ""  Receiver
 SG_ BMS_a168_SW_FC_Full_Weld m2 : 51|1@1+ (1,0) [0|1] ""  Receiver
 SG_ BMS_a169_SW_FC_Pack_Weld m2 : 52|1@1+ (1,0) [0|1] ""  Receiver
 SG_ BMS_a170_SW_Limp_Mode m2 : 53|1@1+ (1,0) [0|1] ""  Receiver
 SG_ BMS_a171_SW_Stack_Voltage_Sense m2 : 54|1@1+ (1,0) [0|1] ""  Receiver
 SG_ BMS_a174_SW_Charge_Failure m2 : 57|1@1+ (1,0) [0|1] ""  Receiver
 SG_ BMS_a176_SW_GracefulPowerOff m2 : 59|1@1+ (1,0) [0|1] ""  Receiver
 SG_ BMS_a178_SW_Uncontrolled_Regen_P m2 : 61|1@1+ (1,0) [0|1] ""  Receiver
 SG_ BMS_a179_SW_Hvp_12V_Fault m2 : 62|1@1+ (1,0) [0|1] ""  Receiver
 SG_ BMS_a180_SW_ECU_reset_blocked m2 : 63|1@1+ (1,0) [0|1] ""  Receiver

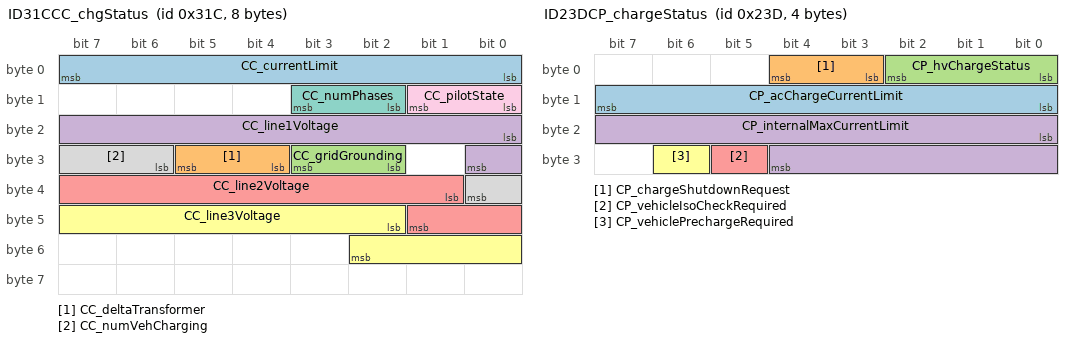
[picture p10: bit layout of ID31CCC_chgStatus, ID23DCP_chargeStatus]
BO_ 796 ID31CCC_chgStatus: 8 VehicleBus
 SG_ CC_currentLimit : 0|8@1+ (0.5,0) [0|127.5] "A"  Receiver
 SG_ CC_deltaTransformer : 28|2@1+ (1,0) [0|3] ""  Receiver
 SG_ CC_gridGrounding : 26|2@1+ (1,0) [0|2] ""  Receiver
 SG_ CC_line1Voltage : 16|9@1+ (1,0) [0|511] "V"  Receiver
 SG_ CC_line2Voltage : 33|9@1+ (1,0) [0|511] "V"  Receiver
 SG_ CC_line3Voltage : 42|9@1+ (1,0) [0|511] "V"  Receiver
 SG_ CC_numPhases : 10|2@1+ (1,0) [0|3] ""  Receiver
 SG_ CC_numVehCharging : 30|3@1+ (1,0) [0|7] ""  Receiver
 SG_ CC_pilotState : 8|2@1+ (1,0) [0|3] ""  Receiver

BO_ 797 ID31DCC_chgStatus2: 8 VehicleBus
 SG_ CC_chgStatus2Index M : 0|8@1+ (1,0) [0|0] ""  Receiver
 SG_ CC_buttonState m0 : 8|1@1+ (1,0) [0|1] ""  Receiver

BO_ 812 ID32CCC_logData: 8 VehicleBus
 SG_ CC_logIndex M : 0|8@1+ (1,0) [0|13] ""  Receiver
 SG_ CC_activeConnectorID m0 : 8|8@1+ (1,0) [0|255] ""  Receiver
 SG_ CC_conn1Current m1 : 8|8@1+ (0.5,0) [0|127.5] "A"  Receiver
 SG_ CC_conn2Current m2 : 8|8@1+ (0.5,0) [0|127.5] "A"  Receiver
 SG_ CC_conn3Current m3 : 8|8@1+ (0.5,0) [0|127.5] "A"  Receiver
 SG_ CC_conn4Current m4 : 8|8@1+ (0.5,0) [0|127.5] "A"  Receiver
 SG_ CC_contactor1Closed m0 : 40|2@1+ (1,0) [0|3] ""  Receiver
 SG_ CC_contactor2Closed m0 : 42|2@1+ (1,0) [0|3] ""  Receiver
 SG_ CC_lifetimeAlertCount m12 : 8|28@1+ (1,0) [0|268435455] ""  Receiver
 SG_ CC_lifetimeAvgStartupTemp m13 : 36|28@1- (0.1,0) [-13421772.8|13421772.7] "C"  Receiver
 SG_ CC_lifetimeCtrCycles m11 : 8|28@1+ (1,0) [0|268435455] ""  Receiver
 SG_ CC_lifetimeCtrCyclesLoaded m11 : 36|28@1+ (1,0) [0|268435455] ""  Receiver
 SG_ CC_lifetimeThermalFoldbacks m12 : 36|28@1+ (1,0) [0|268435455] ""  Receiver
 SG_ CC_lifetimei2t m10 : 32|32@1+ (0.1,0) [0|429496729.5] "A2h"  Receiver
 SG_ CC_temperature1 m0 : 16|8@1- (1,88) [-40|215] "C"  Receiver
 SG_ CC_temperature2 m0 : 24|8@1- (1,88) [-40|215] "C"  Receiver
 SG_ CC_temperature3 m0 : 32|8@1- (1,88) [-40|215] "C"  Receiver
 SG_ CC_temperature4 m0 : 44|8@1- (1,88) [-40|215] "C"  Receiver

BO_ 573 ID23DCP_chargeStatus: 4 VehicleBus
 SG_ CP_acChargeCurrentLimit : 8|8@1+ (0.5,0) [0|127.5] "A"  Receiver
 SG_ CP_chargeShutdownRequest : 3|2@1+ (1,0) [0|2] ""  Receiver
 SG_ CP_hvChargeStatus : 0|3@1+ (1,0) [0|6] ""  Receiver
 SG_ CP_internalMaxCurrentLimit : 16|13@1+ (0.14650226,0) [0|1200] "A"  Receiver
 SG_ CP_vehicleIsoCheckRequired : 29|1@1+ (1,0) [0|1] ""  Receiver
 SG_ CP_vehiclePrechargeRequired : 30|1@1+ (1,0) [0|1] ""  Receiver

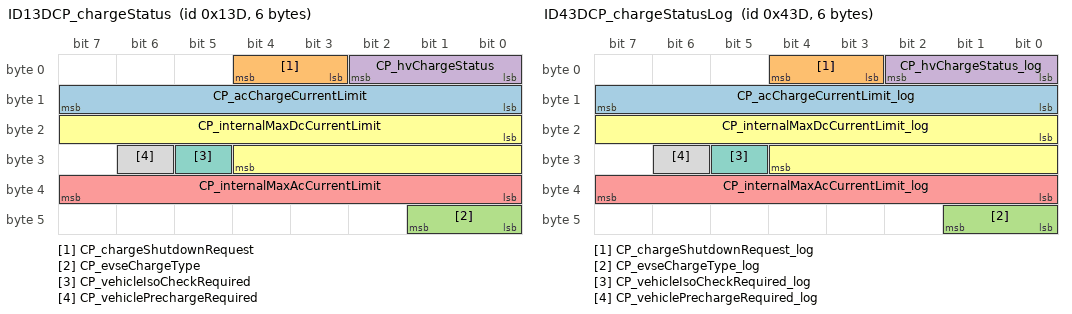
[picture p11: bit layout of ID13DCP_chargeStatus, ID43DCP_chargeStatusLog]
BO_ 317 ID13DCP_chargeStatus: 6 VehicleBus
 SG_ CP_acChargeCurrentLimit : 8|8@1+ (0.5,0) [0|127.5] "A"  Receiver
 SG_ CP_chargeShutdownRequest : 3|2@1+ (1,0) [0|2] ""  Receiver
 SG_ CP_evseChargeType : 40|2@1+ (1,0) [0|2] ""  Receiver
 SG_ CP_hvChargeStatus : 0|3@1+ (1,0) [0|6] ""  Receiver
 SG_ CP_internalMaxAcCurrentLimit : 32|8@1+ (0.5,0) [0|127.5] "A"  Receiver
 SG_ CP_internalMaxDcCurrentLimit : 16|13@1+ (0.146502,0) [0|1200] "A"  Receiver
 SG_ CP_vehicleIsoCheckRequired : 29|1@1+ (1,0) [0|1] ""  Receiver
 SG_ CP_vehiclePrechargeRequired : 30|1@1+ (1,0) [0|1] ""  Receiver

BO_ 1085 ID43DCP_chargeStatusLog: 6 VehicleBus
 SG_ CP_acChargeCurrentLimit_log : 8|8@1+ (0.5,0) [0|127.5] "A"  Receiver
 SG_ CP_chargeShutdownRequest_log : 3|2@1+ (1,0) [0|2] ""  Receiver
 SG_ CP_evseChargeType_log : 40|2@1+ (1,0) [0|2] ""  Receiver
 SG_ CP_hvChargeStatus_log : 0|3@1+ (1,0) [0|6] ""  Receiver
 SG_ CP_internalMaxAcCurrentLimit_log : 32|8@1+ (0.5,0) [0|127.5] "A"  Receiver
 SG_ CP_internalMaxDcCurrentLimit_log : 16|13@1+ (0.14650226,0) [0|1200] "A"  Receiver
 SG_ CP_vehicleIsoCheckRequired_log : 29|1@1+ (1,0) [0|1] ""  Receiver
 SG_ CP_vehiclePrechargeRequired_log : 30|1@1+ (1,0) [0|1] ""  Receiver

BO_ 541 ID21DCP_evseStatus: 8 VehicleBus
 SG_ CP_acChargeState : 53|3@1+ (1,0) [0|6] ""  Receiver
 SG_ CP_acNumRetries : 40|2@1+ (1,0) [0|3] ""  Receiver
 SG_ CP_cableCurrentLimit : 24|7@1+ (1,0) [0|127] "A"  Receiver
 SG_ CP_cableType : 16|3@1+ (1,0) [0|4] ""  Receiver
 SG_ CP_digitalCommsAttempts : 32|2@1+ (1,0) [0|3] ""  Receiver
 SG_ CP_digitalCommsEstablished : 37|1@1+ (1,0) [0|1] ""  Receiver
 SG_ CP_evseAccept : 0|1@1+ (1,0) [0|1] ""  Receiver
 SG_ CP_evseChargeType_UI : 38|2@1+ (1,0) [0|2] ""  Receiver
 SG_ CP_evseRequest : 1|1@1+ (1,0) [0|1] ""  Receiver
 SG_ CP_gbState : 42|4@1+ (1,0) [0|15] ""  Receiver
 SG_ CP_gbdcChargeAttempts : 51|2@1+ (1,0) [0|3] ""  Receiver
 SG_ CP_gbdcFailureReason : 49|2@1+ (1,0) [0|3] ""  Receiver
 SG_ CP_gbdcStopChargeReason : 46|3@1+ (1,0) [0|7] ""  Receiver
 SG_ CP_iecComboState : 60|4@1+ (1,0) [0|12] ""  Receiver
 SG_ CP_pilot : 4|3@1+ (1,0) [0|7] ""  Receiver
 SG_ CP_pilotCurrent : 8|8@1+ (0.5,0) [0|127.5] "A"  Receiver
 SG_ CP_proximity : 2|2@1+ (1,0) [0|3] ""  Receiver
 SG_ CP_teslaDcState : 56|4@1+ (1,0) [0|10] ""  Receiver
 SG_ CP_teslaSwcanState : 34|3@1+ (1,0) [0|6] ""  Receiver

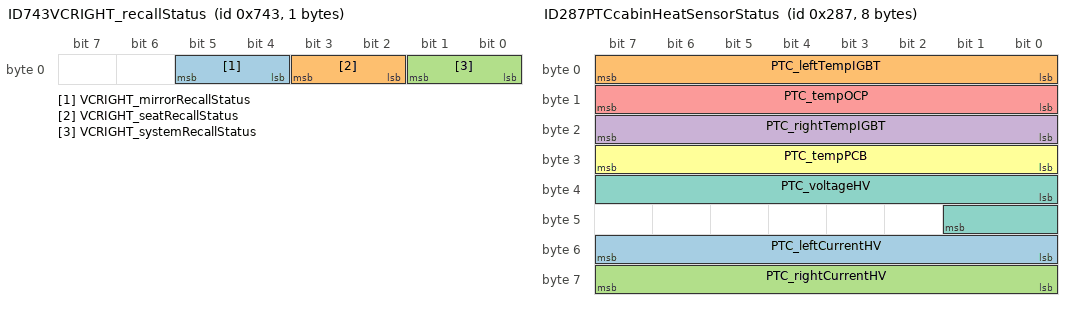
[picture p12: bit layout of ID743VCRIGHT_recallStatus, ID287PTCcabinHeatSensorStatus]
BO_ 1859 ID743VCRIGHT_recallStatus: 1 VehicleBus
 SG_ VCRIGHT_mirrorRecallStatus : 4|2@1+ (1,0) [0|3] ""  Receiver
 SG_ VCRIGHT_seatRecallStatus : 2|2@1+ (1,0) [0|3] ""  Receiver
 SG_ VCRIGHT_systemRecallStatus : 0|2@1+ (1,0) [0|3] ""  Receiver

BO_ 1885 ID75DCP_sensorData: 8 VehicleBus
 SG_ CP_sensorDataSelect M : 0|4@1+ (1,0) [0|12] ""  Receiver
 SG_ CP_UHF_chipState m6 : 4|3@1+ (1,0) [0|7] ""  Receiver
 SG_ CP_UHF_fifoData m6 : 32|8@1+ (1,0) [0|255] ""  Receiver
 SG_ CP_UHF_rssi m6 : 8|8@1+ (1,0) [0|255] ""  Receiver
 SG_ CP_UHF_rxNumBytes m6 : 24|8@1+ (1,0) [0|255] ""  Receiver
 SG_ CP_UHF_rxOverflow m6 : 16|1@1+ (1,0) [0|1] ""  Receiver
 SG_ CP_UHF_selfTestRssi m6 : 40|8@1+ (1,0) [0|255] ""  Receiver
 SG_ CP_backCover2Counts m5 : 32|16@1+ (0.0015259,0) [0|100] "%"  Receiver
 SG_ CP_backCoverCounts m5 : 16|16@1+ (0.0015259,0) [0|100] "%"  Receiver
 SG_ CP_boardTemperature m1 : 32|8@1+ (1.29411764706,-50) [-50|280.0000000003] "C"  Receiver
 SG_ CP_doorCountsDebounced m0 : 24|16@1+ (0.00152590219,0) [0|100.00000002165] "%"  Receiver
 SG_ CP_doorCountsFiltered m0 : 8|16@1+ (0.00152590219,0) [0|100.00000002165] "%"  Receiver
 SG_ CP_doorI m2 : 16|12@1+ (0.0025,0) [0|10.2375] "A"  Receiver
 SG_ CP_doorLastRequestMaxI m2 : 28|12@1+ (0.0025,0) [0|10.2375] "A"  Receiver
 SG_ CP_doorPot m2 : 4|12@1+ (0.025,0) [0|100] "%"  Receiver
 SG_ CP_faultLineV m5 : 4|12@1+ (0.00114,0) [0|4.65524] "V"  Receiver
 SG_ CP_inductiveSensor_raw m4 : 4|28@1+ (1,0) [0|268435455] ""  Receiver
 SG_ CP_inlet1HarnessIdState m12 : 4|2@1+ (1,0) [0|2] ""  Receiver
 SG_ CP_inlet1HarnessIdValue m12 : 8|3@1+ (1,0) [0|7] ""  Receiver
 SG_ CP_inlet1HarnessV m12 : 16|14@1+ (0.001,0) [0|13.3] "V"  Receiver
 SG_ CP_inlet2HarnessIdState m12 : 30|2@1+ (1,0) [0|2] ""  Receiver
 SG_ CP_inlet2HarnessIdValue m12 : 32|3@1+ (1,0) [0|7] ""  Receiver
 SG_ CP_inlet2HarnessV m12 : 40|14@1+ (0.001,0) [0|13.3] "V"  Receiver
 SG_ CP_latch2I m3 : 16|12@1+ (0.0025,0) [0|10.2375] "A"  Receiver
 SG_ CP_latchI m3 : 4|12@1+ (0.0025,0) [0|10.2375] "A"  Receiver
 SG_ CP_pilotHighValue m9 : 40|12@1- (0.01,0) [-20.48|20.47] "V"  Receiver
 SG_ CP_pilotHighValue_intervalMax10s m10 : 28|12@1- (0.01,0) [-20.48|20.47] "V"  Receiver
 SG_ CP_pilotHighValue_intervalMin10s m10 : 40|12@1- (0.01,0) [-20.48|20.47] "V"  Receiver
 SG_ CP_pilotLowValue m9 : 28|12@1- (0.01,0) [-20.48|20.47] "V"  Receiver
 SG_ CP_pilotLowValue_intervalMax10s m10 : 4|12@1- (0.01,0) [-20.48|20.47] "V"  Receiver
 SG_ CP_pilotLowValue_intervalMin10s m10 : 16|12@1- (0.01,0) [-20.48|20.47] "V"  Receiver
 SG_ CP_pilotPeriod m9 : 16|12@1+ (1,0) [0|4095] ""  Receiver
 SG_ CP_pilotPulseWidth m9 : 4|12@1+ (1,0) [0|4095] ""  Receiver
 SG_ CP_pinTemperature1 m1 : 8|8@1+ (0.8039215686,-55) [-55|149.99] "C"  Receiver
 SG_ CP_pinTemperature2 m1 : 16|8@1+ (0.8039215686,-55) [-55|149.99] "C"  Receiver
 SG_ CP_pinTemperature3 m1 : 24|8@1+ (0.8039215686,-55) [-55|149.99] "C"  Receiver
 SG_ CP_proxConn1Sense m8 : 56|1@1+ (1,0) [0|1] ""  Receiver
 SG_ CP_proxEn m8 : 57|1@1+ (1,0) [0|1] ""  Receiver
 SG_ CP_proximityV m8 : 8|16@1+ (0.0001,0) [0|6.5535] "V"  Receiver
 SG_ CP_proximityV_GBCC1 m11 : 8|14@1+ (0.001,0) [0|13.3] "V"  Receiver
 SG_ CP_proximityV_GBCC2 m11 : 24|14@1+ (0.001,0) [0|13.3] "V"  Receiver
 SG_ CP_proximityV_intervalMax10s m8 : 40|16@1+ (0.0001,0) [0|6.5535] "V"  Receiver
 SG_ CP_proximityV_intervalMin10s m8 : 24|16@1+ (0.0001,0) [0|6.5535] "V"  Receiver
 SG_ CP_refVoltage m7 : 8|8@1+ (0.0070588235,0) [0|1.7999999925] "V"  Receiver

BO_ 1962 ID7AAHVP_debugMessage: 8 VehicleBus
 SG_ HVP_debugMessageMultiplexer M : 0|4@1+ (1,0) [0|6] ""  Receiver
 SG_ HVP_auxCurrentMia m0 : 57|1@1+ (1,0) [0|1] ""  Receiver
 SG_ HVP_battery12V m5 : 36|12@1+ (0.1,0) [0|30] "V"  Receiver
 SG_ HVP_currentSenseMia m0 : 58|1@1+ (1,0) [0|1] ""  Receiver
 SG_ HVP_dcLinkNegativeV m3 : 8|16@1- (0.1,0) [-550|550] "V"  Receiver
 SG_ HVP_dcLinkPositiveV m3 : 24|16@1- (0.1,0) [-550|550] "V"  Receiver
 SG_ HVP_dcLinkVoltage m1 : 8|16@1- (0.1,0) [-3276.8|3276.7] "V"  Receiver
 SG_ HVP_fcContCoilCurrent m4 : 4|12@1+ (0.1,0) [0|7.5] "A"  Receiver
 SG_ HVP_fcContVoltage m4 : 16|12@1+ (0.1,0) [0|30] "V"  Receiver
 SG_ HVP_fcLinkNegativeV m3 : 40|16@1- (0.1,0) [-550|550] "V"  Receiver
 SG_ HVP_fcLinkPositiveV m5 : 8|16@1- (0.1,0) [-550|550] "V"  Receiver
 SG_ HVP_fcLinkVoltage m1 : 40|16@1- (0.1,0) [-3276.8|3276.7] "V"  Receiver
 SG_ HVP_gpioBmsEout m0 : 15|1@1+ (1,0) [0|1] ""  Receiver
 SG_ HVP_gpioCpFaultIn m0 : 6|1@1+ (1,0) [0|1] ""  Receiver
 SG_ HVP_gpioCpFaultOut m0 : 16|1@1+ (1,0) [0|1] ""  Receiver
 SG_ HVP_gpioCpLatchEnable m0 : 21|1@1+ (1,0) [0|1] ""  Receiver
 SG_ HVP_gpioCrashSignal m0 : 11|1@1+ (1,0) [0|1] ""  Receiver
 SG_ HVP_gpioFcContNegAux m0 : 14|1@1+ (1,0) [0|1] ""  Receiver
 SG_ HVP_gpioFcContPosAux m0 : 13|1@1+ (1,0) [0|1] ""  Receiver
 SG_ HVP_gpioFcContPowerEnable m0 : 25|1@1+ (1,0) [0|1] ""  Receiver
 SG_ HVP_gpioHvCablesOk m0 : 8|1@1+ (1,0) [0|1] ""  Receiver
 SG_ HVP_gpioHvilEnable m0 : 26|1@1+ (1,0) [0|1] ""  Receiver
 SG_ HVP_gpioHvpSelfEnable m0 : 9|1@1+ (1,0) [0|1] ""  Receiver
 SG_ HVP_gpioHvpVerEn m0 : 19|1@1+ (1,0) [0|1] ""  Receiver
 SG_ HVP_gpioLed m0 : 10|1@1+ (1,0) [0|1] ""  Receiver
 SG_ HVP_gpioPackContPowerEn m0 : 7|1@1+ (1,0) [0|1] ""  Receiver
 SG_ HVP_gpioPackCoontPosFlywheel m0 : 20|1@1+ (1,0) [0|1] ""  Receiver
 SG_ HVP_gpioPassivePyroDepl m0 : 4|1@1+ (1,0) [0|1] ""  Receiver
 SG_ HVP_gpioPcsChargePwmEnable m0 : 24|1@1+ (1,0) [0|1] ""  Receiver
 SG_ HVP_gpioPcsDcdcPwmEnable m0 : 23|1@1+ (1,0) [0|1] ""  Receiver
 SG_ HVP_gpioPcsEnable m0 : 22|1@1+ (1,0) [0|1] ""  Receiver
 SG_ HVP_gpioPyroIsoEn m0 : 5|1@1+ (1,0) [0|1] ""  Receiver
 SG_ HVP_gpioPyroPor m0 : 17|1@1+ (1,0) [0|1] ""  Receiver
 SG_ HVP_gpioSecDrdy m0 : 27|1@1+ (1,0) [0|1] ""  Receiver
 SG_ HVP_gpioShuntDataReady m0 : 12|1@1+ (1,0) [0|1] ""  Receiver
 SG_ HVP_gpioShuntEn m0 : 18|1@1+ (1,0) [0|1] ""  Receiver
 SG_ HVP_hvilInVoltage m4 : 28|12@1+ (0.1,0) [0|30] "V"  Receiver
 SG_ HVP_hvilOutVoltage m4 : 40|12@1+ (0.1,0) [0|30] "V"  Receiver
 SG_ HVP_hvp1v5Ref m0 : 28|12@1+ (0.1,0) [0|3] "V"  Receiver
 SG_ HVP_packContCoilCurrent m5 : 24|12@1+ (0.1,0) [0|7.5] "A"  Receiver
 SG_ HVP_packContVoltage m2 : 4|12@1+ (0.1,0) [0|30] "V"  Receiver
 SG_ HVP_packCurrentMia m0 : 56|1@1+ (1,0) [0|1] ""  Receiver
 SG_ HVP_packNegativeV m2 : 16|16@1- (0.1,0) [-550|550] "V"  Receiver
 SG_ HVP_packPositiveV m2 : 32|16@1- (0.1,0) [-550|550] "V"  Receiver
 SG_ HVP_packVoltage m1 : 24|16@1- (0.1,0) [-3276.8|3276.7] "V"  Receiver
 SG_ HVP_pyroAnalog m2 : 48|12@1+ (0.1,0) [0|3] "V"  Receiver
 SG_ HVP_shuntAsicTempDbg m6 : 40|16@1- (0.01,0) [-327.67|327.67] "C"  Receiver
 SG_ HVP_shuntAsicTempStatus m6 : 60|2@1+ (1,0) [0|3] ""  Receiver
 SG_ HVP_shuntAuxCurrentDbg m6 : 8|16@1- (0.1,0) [-3276.8|3276.7] "A"  Receiver
 SG_ HVP_shuntAuxCurrentStatus m6 : 56|2@1+ (1,0) [0|3] ""  Receiver
 SG_ HVP_shuntBarTempDbg m6 : 24|16@1- (0.01,0) [-327.67|327.67] "C"  Receiver
 SG_ HVP_shuntBarTempStatus m6 : 58|2@1+ (1,0) [0|3] ""  Receiver
 SG_ HVP_shuntCurrentDebug m0 : 40|16@1- (0.1,0) [-3276.8|3276.7] "A"  Receiver
 SG_ HVP_shuntHwMia m0 : 61|1@1+ (1,0) [0|1] ""  Receiver
 SG_ HVP_shuntRefVoltageDbg m5 : 48|16@1- (0.001,0) [-32.768|32.767] "V"  Receiver
 SG_ HVP_shuntRefVoltageMismatch m0 : 59|1@1+ (1,0) [0|1] ""  Receiver
 SG_ HVP_shuntThermistorMia m0 : 60|1@1+ (1,0) [0|1] ""  Receiver

BO_ 647 ID287PTCcabinHeatSensorStatus: 8 VehicleBus
 SG_ PTC_leftCurrentHV : 48|8@1+ (0.2,0) [0|50] "A"  Receiver
 SG_ PTC_leftTempIGBT : 0|8@1+ (1,-40) [-40|200] "C"  Receiver
 SG_ PTC_rightCurrentHV : 56|8@1+ (0.2,0) [0|50] "A"  Receiver
 SG_ PTC_rightTempIGBT : 16|8@1+ (1,-40) [-40|200] "C"  Receiver
 SG_ PTC_tempOCP : 8|8@1+ (1,-40) [-40|200] "C"  Receiver
 SG_ PTC_tempPCB : 24|8@1+ (1,-40) [-40|200] "C"  Receiver
 SG_ PTC_voltageHV : 32|10@1+ (0.5,0) [0|511.5] "V"  Receiver

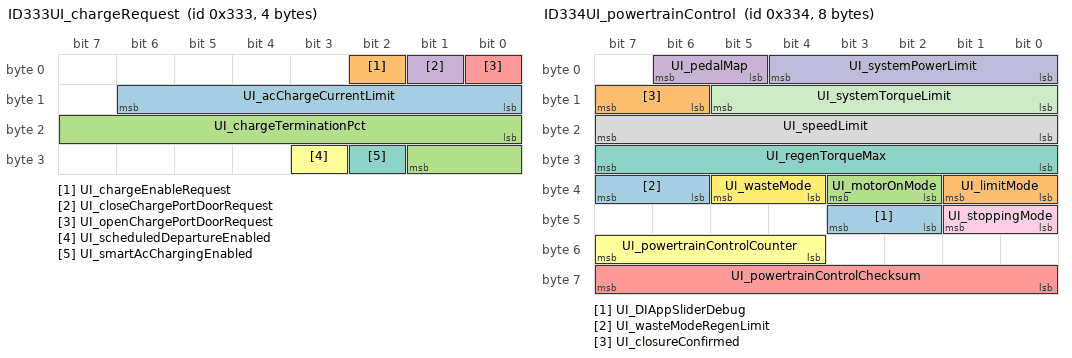
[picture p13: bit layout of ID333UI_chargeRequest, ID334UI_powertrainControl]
BO_ 819 ID333UI_chargeRequest: 4 VehicleBus
 SG_ UI_acChargeCurrentLimit : 8|7@1+ (1,0) [0|127] "A"  Receiver
 SG_ UI_chargeEnableRequest : 2|1@1+ (1,0) [0|1] ""  Receiver
 SG_ UI_chargeTerminationPct : 16|10@1+ (0.1,0) [25|100] "%"  Receiver
 SG_ UI_closeChargePortDoorRequest : 1|1@1+ (1,0) [0|1] ""  Receiver
 SG_ UI_openChargePortDoorRequest : 0|1@1+ (1,0) [0|1] ""  Receiver
 SG_ UI_scheduledDepartureEnabled : 27|1@1+ (1,0) [0|1] ""  Receiver
 SG_ UI_smartAcChargingEnabled : 26|1@1+ (1,0) [0|1] ""  Receiver

BO_ 820 ID334UI_powertrainControl: 8 VehicleBus
 SG_ UI_DIAppSliderDebug : 42|2@1+ (1,0) [0|3] ""  Receiver
 SG_ UI_limitMode : 32|2@1+ (1,0) [0|3] ""  Receiver
 SG_ UI_motorOnMode : 34|2@1+ (1,0) [0|2] ""  Receiver
 SG_ UI_pedalMap : 5|2@1+ (1,0) [0|2] ""  Receiver
 SG_ UI_powertrainControlChecksum : 56|8@1+ (1,0) [0|255] ""  Receiver
 SG_ UI_powertrainControlCounter : 52|4@1+ (1,0) [0|15] ""  Receiver
 SG_ UI_regenTorqueMax : 24|8@1+ (0.5,0) [0|100] "%"  Receiver
 SG_ UI_speedLimit : 16|8@1+ (1,50) [50|285] "kph"  Receiver
 SG_ UI_stoppingMode : 40|2@1+ (1,0) [0|2] ""  Receiver
 SG_ UI_systemPowerLimit : 0|5@1+ (20,20) [20|640] "kW"  Receiver
 SG_ UI_systemTorqueLimit : 8|6@1+ (100,4000) [4000|10300] "Nm"  Receiver
 SG_ UI_wasteMode : 36|2@1+ (1,0) [0|2] ""  Receiver
 SG_ UI_wasteModeRegenLimit : 38|2@1+ (1,0) [0|3] ""  Receiver
 SG_ UI_closureConfirmed : 14|2@1+ (1,0) [0|2] ""  Receiver

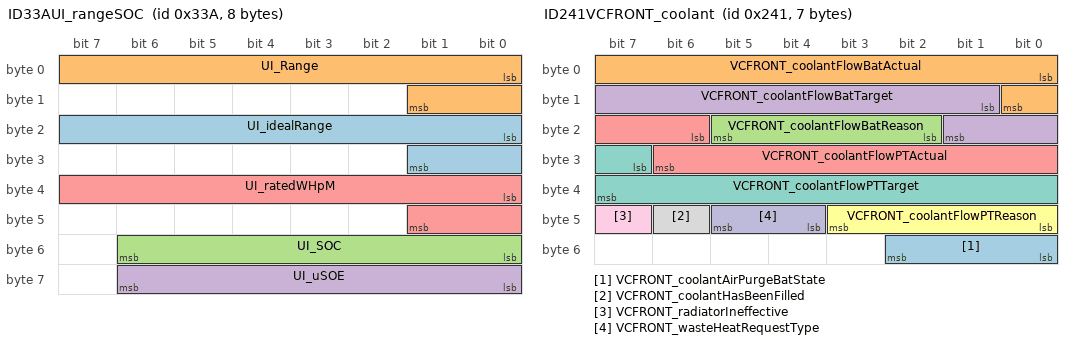
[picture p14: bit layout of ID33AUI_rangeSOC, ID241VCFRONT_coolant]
BO_ 826 ID33AUI_rangeSOC: 8 VehicleBus
 SG_ UI_idealRange : 16|10@1+ (1,0) [0|1023] "mi"  Receiver
 SG_ UI_Range : 0|10@1+ (1,0) [0|1023] "mi"  Receiver
 SG_ UI_SOC : 48|7@1+ (1,0) [0|127] "%"  Receiver
 SG_ UI_uSOE : 56|7@1+ (1,0) [0|127] "%"  Receiver
 SG_ UI_ratedWHpM : 32|10@1+ (1,0) [0|1023] "WHpM"  Receiver

BO_ 577 ID241VCFRONT_coolant: 7 VehicleBus
 SG_ VCFRONT_coolantAirPurgeBatState : 48|3@1+ (1,0) [0|4] ""  Receiver
 SG_ VCFRONT_coolantFlowBatActual : 0|9@1+ (0.1,0) [0|40] "LPM"  Receiver
 SG_ VCFRONT_coolantFlowBatReason : 18|4@1+ (1,0) [0|14] ""  Receiver
 SG_ VCFRONT_coolantFlowBatTarget : 9|9@1+ (0.1,0) [0|40] "LPM"  Receiver
 SG_ VCFRONT_coolantFlowPTActual : 22|9@1+ (0.1,0) [0|40] "LPM"  Receiver
 SG_ VCFRONT_coolantFlowPTReason : 40|4@1+ (1,0) [0|14] ""  Receiver
 SG_ VCFRONT_coolantFlowPTTarget : 31|9@1+ (0.1,0) [0|40] "LPM"  Receiver
 SG_ VCFRONT_coolantHasBeenFilled : 46|1@1+ (1,0) [0|1] ""  Receiver
 SG_ VCFRONT_radiatorIneffective : 47|1@1+ (1,0) [0|1] ""  Receiver
 SG_ VCFRONT_wasteHeatRequestType : 44|2@1+ (1,0) [0|2] ""  Receiver

CM_ SG_ 130 UI_tripPlanningActive "Navigation Active";
CM_ SG_ 257 RCM_pitchRate "Pitch";
CM_ SG_ 257 RCM_rollRate "Roll";
CM_ SG_ 257 RCM_yawRate "Yaw";
CM_ SG_ 273 RCM_lateralAccel "L/R Acceleration";
CM_ SG_ 273 RCM_longitudinalAccel "F/B Acceleration";
CM_ SG_ 273 RCM_verticalAccel "Vertical Acceleration";
CM_ SG_ 692 PCS_dcdcHvBusVolt "DCDC HV Voltage";
CM_ SG_ 692 PCS_dcdcLvBusVolt "DCDC 12v Voltage";
CM_ SG_ 692 PCS_dcdcLvOutputCurrent "DCDC 12v Output Current";
CM_ SG_ 985 UI_gpsVehicleHeading "GPS Heading";
CM_ SG_ 985 UI_gpsVehicleSpeed "GPS Speed";
CM_ SG_ 1011 UI_odometer "UI Odometer";
CM_ SG_ 615 DI_gradeEst "Estimated Grade";
CM_ SG_ 615 DI_mass "Estimated Mass";
CM_ SG_ 642 VCLEFT_hvacBlowerRPMActual "HVAC Blower Speed";
CM_ SG_ 647 PTC_leftCurrentHV "Heater Left Current";
CM_ SG_ 647 PTC_rightCurrentHV "Heater Right Current";
CM_ SG_ 647 PTC_voltageHV "Heater Voltage";
CM_ SG_ 819 UI_acChargeCurrentLimit "UI Charge Current Limit";
CM_ SG_ 826 UI_Range "Range";
CM_ SG_ 826 UI_SOC "State of Charge UI";
CM_ SG_ 826 UI_uSOE "UI fine SOC";
CM_ SG_ 826 UI_ratedWHpM "WHM Rating";
CM_ SG_ 577 VCFRONT_coolantFlowBatActual "Battery Coolant Flow";
CM_ SG_ 577 VCFRONT_coolantFlowPTActual "Powertrain Coolant Flow";
BA_DEF_ BO_  "GenMsgSendType" ENUM  "Cyclic","SendType1","SendType2","SendType3","SendType4","SendType5","SendType6","SendType7","SendType8","SendType9";
BA_DEF_ BO_  "GenMsgCycleTime" INT 0 0;
BA_DEF_  "BusType" STRING ;
BA_DEF_ BO_  "GenMsgAutoGenSnd" ENUM  "No","Yes";
BA_DEF_ BO_  "GenMsgAutoGenDsp" ENUM  "No","Yes";
BA_DEF_ SG_  "GenSigEnvVarType" ENUM  "int","float","undef";
BA_DEF_ BU_  "GenNodAutoGenSnd" ENUM  "No","Yes";
BA_DEF_ BU_  "GenNodAutoGenDsp" ENUM  "No","Yes";
BA_DEF_  "GenEnvVarEndingDsp" STRING ;
BA_DEF_  "GenEnvVarEndingSnd" STRING ;
BA_DEF_  "GenEnvVarPrefix" STRING ;
BA_DEF_  "Modified" STRING ;
BA_DEF_ SG_  "SystemSignalLongSymbol" STRING ;
BA_DEF_ BO_  "SystemMessageLongSymbol" STRING ;
BA_DEF_DEF_  "GenMsgSendType" "Cyclic";
BA_DEF_DEF_  "GenMsgCycleTime" 0;
BA_DEF_DEF_  "BusType" "";
BA_DEF_DEF_  "GenMsgAutoGenSnd" "Yes";
BA_DEF_DEF_  "GenMsgAutoGenDsp" "Yes";
BA_DEF_DEF_  "GenSigEnvVarType" "undef";
BA_DEF_DEF_  "GenNodAutoGenSnd" "Yes";
BA_DEF_DEF_  "GenNodAutoGenDsp" "Yes";
BA_DEF_DEF_  "GenEnvVarEndingDsp" "Dsp";
BA_DEF_DEF_  "GenEnvVarEndingSnd" "Snd";
BA_DEF_DEF_  "GenEnvVarPrefix" "Env";
BA_DEF_DEF_  "Modified" "JW2020Jul22";
BA_DEF_DEF_  "SystemSignalLongSymbol" "";
BA_DEF_DEF_  "SystemMessageLongSymbol" "";
BA_ "BusType" "CAN";
BA_ "GenMsgCycleTime" BO_ 530 100;
BA_ "GenMsgCycleTime" BO_ 819 500;
BA_ "GenMsgCycleTime" BO_ 577 100;
BA_ "SystemSignalLongSymbol" SG_ 291 UI_a037_AudioWatchdogXrunStormEr "UI_a037_AudioWatchdogXrunStormError";
BA_ "SystemSignalLongSymbol" SG_ 291 UI_a038_AudioWatchdogA2bI2cLocku "UI_a038_AudioWatchdogA2bI2cLockupError";
BA_ "SystemSignalLongSymbol" SG_ 291 UI_a048_AudioPremiumAmpCheckFail "UI_a048_AudioPremiumAmpCheckFailed";
BA_ "SystemSignalLongSymbol" SG_ 291 UI_a056_ManualECallButtonDisconn "UI_a056_ManualECallButtonDisconnected";
BA_ "SystemSignalLongSymbol" SG_ 611 VCRIGHT_hvacFilterLifeDetectActi "VCRIGHT_hvacFilterLifeDetectActive";
BA_ "SystemSignalLongSymbol" SG_ 642 VCLEFT_hvacBlower_IO_CBC_TAIL_va "VCLEFT_hvacBlower_IO_CBC_TAIL_valid";
BA_ "SystemSignalLongSymbol" SG_ 642 VCLEFT_hvacBlower_IO_CBC_numUart "VCLEFT_hvacBlower_IO_CBC_numUartErr";
BA_ "SystemSignalLongSymbol" SG_ 899 VCRIGHT_estimatedVehicleSituatio "VCRIGHT_estimatedVehicleSituation";
BA_ "SystemSignalLongSymbol" SG_ 963 VCRIGHT_liftgateShutfaceSwitchPr "VCRIGHT_liftgateShutfaceSwitchPressed";
BA_ "SystemSignalLongSymbol" SG_ 946 BMS_hvChain_limitingStateTempera "BMS_hvChain_limitingStateTemperature";
BA_ "SystemSignalLongSymbol" SG_ 946 BMS_vChangeWindowNumOutlierChang "BMS_vChangeWindowNumOutlierChanges";
BA_ "SystemSignalLongSymbol" SG_ 800 BMS_a040_SW_Watch_Dog_HW_Trigger "BMS_a040_SW_Watch_Dog_HW_Triggered";
BA_ "SystemSignalLongSymbol" SG_ 800 BMS_a041_SW_Destructive_Reset_So "BMS_a041_SW_Destructive_Reset_Source";
BA_ "SystemSignalLongSymbol" SG_ 800 BMS_a057_SW_Bandolier_Model_Warn "BMS_a057_SW_Bandolier_Model_Warning";
BA_ "SystemSignalLongSymbol" SG_ 800 BMS_a058_SW_Bandolier_Model_Rese "BMS_a058_SW_Bandolier_Model_Reset";
BA_ "SystemSignalLongSymbol" SG_ 800 BMS_a092_SW_ChargePort_Mia_On_Hv "BMS_a092_SW_ChargePort_Mia_On_Hvs";
BA_ "SystemSignalLongSymbol" SG_ 800 BMS_a098_SW_BMB_Data_Integrity_L "BMS_a098_SW_BMB_Data_Integrity_Loss";
BA_ "SystemSignalLongSymbol" SG_ 800 BMS_a135_HW_BMB_Diagnostics_Fail "BMS_a135_HW_BMB_Diagnostics_Failure";
BA_ "SystemSignalLongSymbol" SG_ 800 BMS_a178_SW_Uncontrolled_Regen_P "BMS_a178_SW_Uncontrolled_Regen_PwrB";
VAL_ 12 UI_autopilotTrial 3 "ACTIVE" 0 "NONE" 1 "START" 2 "STOP" ;
VAL_ 12 UI_cellNetworkTechnology 9 "CELL_NETWORK_CDMA" 2 "CELL_NETWORK_EDGE" 1 "CELL_NETWORK_GPRS" 8 "CELL_NETWORK_GSM" 4 "CELL_NETWORK_HSDPA" 6 "CELL_NETWORK_HSPA" 5 "CELL_NETWORK_HSUPA" 7 "CELL_NETWORK_LTE" 0 "CELL_NETWORK_NONE" 15 "CELL_NETWORK_SNA" 3 "CELL_NETWORK_UMTS" 10 "CELL_NETWORK_WCDMA" ;
VAL_ 12 UI_cellSignalBars 5 "FIVE" 4 "FOUR" 1 "ONE" 7 "SNA" 3 "THREE" 2 "TWO" 0 "ZERO" ;
VAL_ 12 UI_factoryReset 3 "CUSTOMER" 1 "DEVELOPER" 2 "DIAGNOSTIC" 0 "NONE_SNA" ;
VAL_ 130 UI_energyAtDestination -32768 "SNA" -32767 "TRIP_TOO_LONG" ;
VAL_ 130 UI_hindsightEnergy -32768 "SNA" -32767 "TRIP_TOO_LONG" ;
VAL_ 130 UI_predictedEnergy -32768 "SNA" -32767 "TRIP_TOO_LONG" ;
VAL_ 257 RCM_pitchRate -16384 "SNA" ;
VAL_ 257 RCM_pitchRateQF 3 "FAULTED" 0 "INIT" 2 "TEMP_INVALID" 1 "VALID" ;
VAL_ 257 RCM_rollRate -16384 "SNA" ;
VAL_ 257 RCM_rollRateQF 3 "FAULTED" 0 "INIT" 2 "TEMP_INVALID" 1 "VALID" ;
VAL_ 257 RCM_yawRate -32768 "SNA" ;
VAL_ 257 RCM_yawRateQF 0 "FAULTED" 1 "NOT_FAULTED" ;
VAL_ 273 RCM_lateralAccel -32768 "SNA" ;
VAL_ 273 RCM_lateralAccelQF 0 "FAULTED" 1 "NOT_FAULTED" ;
VAL_ 273 RCM_longitudinalAccel -32768 "SNA" ;
VAL_ 273 RCM_longitudinalAccelQF 0 "FAULTED" 1 "NOT_FAULTED" ;
VAL_ 273 RCM_verticalAccel -32768 "SNA" ;
VAL_ 273 RCM_verticalAccelQF 0 "FAULTED" 1 "NOT_FAULTED" ;
VAL_ 258 VCLEFT_frontLatchStatus 5 "LATCH_AJAR" 2 "LATCH_CLOSED" 3 "LATCH_CLOSING" 7 "LATCH_DEFAULT" 8 "LATCH_FAULT" 1 "LATCH_OPENED" 4 "LATCH_OPENING" 0 "LATCH_SNA" 6 "LATCH_TIMEOUT" ;
VAL_ 258 VCLEFT_mirrorFoldState 1 "MIRROR_FOLD_STATE_FOLDED" 3 "MIRROR_FOLD_STATE_FOLDING" 2 "MIRROR_FOLD_STATE_UNFOLDED" 4 "MIRROR_FOLD_STATE_UNFOLDING" 0 "MIRROR_FOLD_STATE_UNKNOWN" ;
VAL_ 258 VCLEFT_mirrorHeatState 4 "HEATER_STATE_FAULT" 2 "HEATER_STATE_OFF" 3 "HEATER_STATE_OFF_UNAVAILABLE" 1 "HEATER_STATE_ON" 0 "HEATER_STATE_SNA" ;
VAL_ 258 VCLEFT_mirrorRecallState 0 "MIRROR_RECALL_STATE_INIT" 1 "MIRROR_RECALL_STATE_RECALLING_AXIS_1" 2 "MIRROR_RECALL_STATE_RECALLING_AXIS_2" 3 "MIRROR_RECALL_STATE_RECALLING_COMPLETE" 4 "MIRROR_RECALL_STATE_RECALLING_FAILED" 5 "MIRROR_RECALL_STATE_RECALLING_STOPPED" ;
VAL_ 258 VCLEFT_mirrorState 3 "MIRROR_STATE_FOLD_UNFOLD" 0 "MIRROR_STATE_IDLE" 4 "MIRROR_STATE_RECALL" 1 "MIRROR_STATE_TILT_X" 2 "MIRROR_STATE_TILT_Y" ;
VAL_ 258 VCLEFT_rearLatchStatus 5 "LATCH_AJAR" 2 "LATCH_CLOSED" 3 "LATCH_CLOSING" 7 "LATCH_DEFAULT" 8 "LATCH_FAULT" 1 "LATCH_OPENED" 4 "LATCH_OPENING" 0 "LATCH_SNA" 6 "LATCH_TIMEOUT" ;
VAL_ 259 VCRIGHT_frontLatchStatus 5 "LATCH_AJAR" 2 "LATCH_CLOSED" 3 "LATCH_CLOSING" 7 "LATCH_DEFAULT" 8 "LATCH_FAULT" 1 "LATCH_OPENED" 4 "LATCH_OPENING" 0 "LATCH_SNA" 6 "LATCH_TIMEOUT" ;
VAL_ 259 VCRIGHT_mirrorFoldState 1 "MIRROR_FOLD_STATE_FOLDED" 3 "MIRROR_FOLD_STATE_FOLDING" 2 "MIRROR_FOLD_STATE_UNFOLDED" 4 "MIRROR_FOLD_STATE_UNFOLDING" 0 "MIRROR_FOLD_STATE_UNKNOWN" ;
VAL_ 259 VCRIGHT_mirrorRecallState 0 "MIRROR_RECALL_STATE_INIT" 1 "MIRROR_RECALL_STATE_RECALLING_AXIS_1" 2 "MIRROR_RECALL_STATE_RECALLING_AXIS_2" 3 "MIRROR_RECALL_STATE_RECALLING_COMPLETE" 4 "MIRROR_RECALL_STATE_RECALLING_FAILED" 5 "MIRROR_RECALL_STATE_RECALLING_STOPPED" ;
VAL_ 259 VCRIGHT_mirrorState 3 "MIRROR_STATE_FOLD_UNFOLD" 0 "MIRROR_STATE_IDLE" 4 "MIRROR_STATE_RECALL" 1 "MIRROR_STATE_TILT_X" 2 "MIRROR_STATE_TILT_Y" ;
VAL_ 259 VCRIGHT_rearLatchStatus 5 "LATCH_AJAR" 2 "LATCH_CLOSED" 3 "LATCH_CLOSING" 7 "LATCH_DEFAULT" 8 "LATCH_FAULT" 1 "LATCH_OPENED" 4 "LATCH_OPENING" 0 "LATCH_SNA" 6 "LATCH_TIMEOUT" ;
VAL_ 259 VCRIGHT_trunkLatchStatus 5 "LATCH_AJAR" 2 "LATCH_CLOSED" 3 "LATCH_CLOSING" 7 "LATCH_DEFAULT" 8 "LATCH_FAULT" 1 "LATCH_OPENED" 4 "LATCH_OPENING" 0 "LATCH_SNA" 6 "LATCH_TIMEOUT" ;
VAL_ 322 VCLEFT_liftgateStatusIndex 0 "LIFTGATE_STATUS_INDEX_0" 1 "LIFTGATE_STATUS_INDEX_1" 2 "LIFTGATE_STATUS_INDEX_INVALID" ;
VAL_ 322 VCLEFT_liftgateLatchRequest 1 "LATCH_REQUEST_CINCH" 3 "LATCH_REQUEST_FORCE_RELEASE" 0 "LATCH_REQUEST_NONE" 2 "LATCH_REQUEST_RELEASE" 4 "LATCH_REQUEST_RESET" ;
VAL_ 322 VCLEFT_liftgateMvmntNotAllowedCo 4 "PLG_MVMT_NOT_ALLOWED_EXTERIOR_PRESS_AT_MAX_OPEN" 5 "PLG_MVMT_NOT_ALLOWED_LOCKED" 1 "PLG_MVMT_NOT_ALLOWED_LOW_12V" 0 "PLG_MVMT_NOT_ALLOWED_NONE" 3 "PLG_MVMT_NOT_ALLOWED_UNCALIBRATED" 2 "PLG_MVMT_NOT_ALLOWED_VEHICLE_AT_SPEED" ;
VAL_ 322 VCLEFT_liftgatePhysicalChimeRequ 0 "LIFTGATE_CHIME_REQUEST_NONE" 4 "LIFTGATE_CHIME_REQUEST_ONE_LONG" 1 "LIFTGATE_CHIME_REQUEST_ONE_SHORT" 3 "LIFTGATE_CHIME_REQUEST_THREE_SHORT" 2 "LIFTGATE_CHIME_REQUEST_TWO_SHORT" ;
VAL_ 322 VCLEFT_liftgateRequestSource 5 "PLG_REQUEST_SOURCE_CLOSE_ALL" 2 "PLG_REQUEST_SOURCE_EXTERIOR" 4 "PLG_REQUEST_SOURCE_KEY_TRUNK_BUTTON" 6 "PLG_REQUEST_SOURCE_MCU_CLOSE" 1 "PLG_REQUEST_SOURCE_MCU_SWITCH" 0 "PLG_REQUEST_SOURCE_NONE" 3 "PLG_REQUEST_SOURCE_SHUTFACE" 7 "PLG_REQUEST_SOURCE_UDS" ;
VAL_ 322 VCLEFT_liftgateState 2 "PLG_STATE_BACKOFF" 5 "PLG_STATE_CLOSED" 4 "PLG_STATE_CLOSING" 11 "PLG_STATE_END_OF_TRAVEL" 0 "PLG_STATE_INIT" 7 "PLG_STATE_LATCH_CLOSING" 12 "PLG_STATE_LATCH_ENTRY" 10 "PLG_STATE_LATCH_EXIT" 6 "PLG_STATE_LATCH_OPENING" 8 "PLG_STATE_NOT_INSTALLED" 1 "PLG_STATE_OFF" 3 "PLG_STATE_OPENING" 9 "PLG_STATE_UNKNOWN" ;
VAL_ 322 VCLEFT_liftgateStoppingCondition 11 "PLG_STOPPING_CONDITION_COUNT" 10 "PLG_STOPPING_CONDITION_LATCH_FAULT" 3 "PLG_STOPPING_CONDITION_LOW_12V" 0 "PLG_STOPPING_CONDITION_NONE" 6 "PLG_STOPPING_CONDITION_OBSTACLE_CURRENT" 2 "PLG_STOPPING_CONDITION_OBSTACLE_STALL" 7 "PLG_STOPPING_CONDITION_OBSTACLE_TRAJ_POS" 8 "PLG_STOPPING_CONDITION_OBSTACLE_TRAJ_VEL" 1 "PLG_STOPPING_CONDITION_PINCH" 4 "PLG_STOPPING_CONDITION_STATE_TIMEOUT" 9 "PLG_STOPPING_CONDITION_UNCALIBRATED" 5 "PLG_STOPPING_CONDITION_VEHICLE_AT_SPEED" ;
VAL_ 322 VCLEFT_liftgateUIChimeRequest 0 "LIFTGATE_CHIME_REQUEST_NONE" 4 "LIFTGATE_CHIME_REQUEST_ONE_LONG" 1 "LIFTGATE_CHIME_REQUEST_ONE_SHORT" 3 "LIFTGATE_CHIME_REQUEST_THREE_SHORT" 2 "LIFTGATE_CHIME_REQUEST_TWO_SHORT" ;
VAL_ 325 ESP_absBrakeEvent2 2 "ABS_EVENT_ACTIVE_FRONT" 1 "ABS_EVENT_ACTIVE_FRONT_REAR" 3 "ABS_EVENT_ACTIVE_REAR" 0 "ABS_EVENT_NOT_ACTIVE" ;
VAL_ 325 ESP_absFaultLamp 0 "ABS_FAULT_LAMP_OFF" 1 "ABS_FAULT_LAMP_ON" ;
VAL_ 325 ESP_brakeApply 1 "BLS_ACTIVE" 0 "BLS_INACTIVE" ;
VAL_ 325 ESP_brakeDiscWipingActive 1 "BDW_ACTIVE" 0 "BDW_INACTIVE" ;
VAL_ 325 ESP_brakeLamp 0 "LAMP_OFF" 1 "LAMP_ON" ;
VAL_ 325 ESP_brakeTorqueTarget 8191 "SNA" ;
VAL_ 325 ESP_btcTargetState 1 "BACKUP" 0 "OFF" 2 "ON" 3 "SNA" ;
VAL_ 325 ESP_cdpStatus 2 "ACTUATING_EPB_CDP" 3 "CDP_COMMAND_INVALID" 1 "CDP_IS_AVAILABLE" 0 "CDP_IS_NOT_AVAILABLE" ;
VAL_ 325 ESP_driverBrakeApply 2 "Driver_applying_brakes" 3 "Faulty_SNA" 0 "NotInit_orOff" 1 "Not_Applied" ;
VAL_ 325 ESP_ebdFaultLamp 0 "EBD_FAULT_LAMP_OFF" 1 "EBD_FAULT_LAMP_ON" ;
VAL_ 325 ESP_ebrStandstillSkid 0 "NO_STANDSTILL_SKID" 1 "STANDSTILL_SKID_DETECTED" ;
VAL_ 325 ESP_ebrStatus 2 "ACTUATING_DI_EBR" 3 "EBR_COMMAND_INVALID" 1 "EBR_IS_AVAILABLE" 0 "EBR_IS_NOT_AVAILABLE" ;
VAL_ 325 ESP_espFaultLamp 0 "ESP_FAULT_LAMP_OFF" 1 "ESP_FAULT_LAMP_ON" ;
VAL_ 325 ESP_espLampFlash 1 "ESP_LAMP_FLASH" 0 "ESP_LAMP_OFF" ;
VAL_ 325 ESP_espModeActive 0 "ESP_MODE_00_NORMAL" 1 "ESP_MODE_01" 2 "ESP_MODE_02" 3 "ESP_MODE_03" ;
VAL_ 325 ESP_lateralAccelQF 1 "IN_SPEC" 0 "UNDEFINABLE_ACCURACY" ;
VAL_ 325 ESP_longitudinalAccelQF 1 "IN_SPEC" 0 "UNDEFINABLE_ACCURACY" ;
VAL_ 325 ESP_ptcTargetState 1 "BACKUP" 0 "FAULT" 2 "ON" 3 "SNA" ;
VAL_ 325 ESP_stabilityControlSts2 2 "ENGAGED" 3 "FAULTED" 0 "INIT" 1 "ON" ;
VAL_ 325 ESP_steeringAngleQF 1 "IN_SPEC" 0 "UNDEFINABLE_ACCURACY" ;
VAL_ 325 ESP_yawRateQF 1 "IN_SPEC" 0 "UNDEFINABLE_ACCURACY" ;
VAL_ 522 HVP_fcContNegativeState 3 "CONTACTOR_STATE_BLOCKED" 6 "CONTACTOR_STATE_ECONOMIZED" 1 "CONTACTOR_STATE_OPEN" 5 "CONTACTOR_STATE_OPENING" 2 "CONTACTOR_STATE_PRECHARGE" 4 "CONTACTOR_STATE_PULLED_IN" 0 "CONTACTOR_STATE_SNA" 7 "CONTACTOR_STATE_WELDED" ;
VAL_ 522 HVP_fcContPositiveState 3 "CONTACTOR_STATE_BLOCKED" 6 "CONTACTOR_STATE_ECONOMIZED" 1 "CONTACTOR_STATE_OPEN" 5 "CONTACTOR_STATE_OPENING" 2 "CONTACTOR_STATE_PRECHARGE" 4 "CONTACTOR_STATE_PULLED_IN" 0 "CONTACTOR_STATE_SNA" 7 "CONTACTOR_STATE_WELDED" ;
VAL_ 522 HVP_fcContactorSetState 3 "CONTACTOR_SET_STATE_BLOCKED" 5 "CONTACTOR_SET_STATE_CLOSED" 2 "CONTACTOR_SET_STATE_CLOSING" 9 "CONTACTOR_SET_STATE_NEGATIVE_CLOSED" 1 "CONTACTOR_SET_STATE_OPEN" 4 "CONTACTOR_SET_STATE_OPENING" 6 "CONTACTOR_SET_STATE_PARTIAL_WELD" 8 "CONTACTOR_SET_STATE_POSITIVE_CLOSED" 0 "CONTACTOR_SET_STATE_SNA" 7 "CONTACTOR_SET_STATE_WELDED" ;
VAL_ 522 HVP_fcCtrsRequestStatus 1 "REQUEST_ACTIVE" 2 "REQUEST_COMPLETED" 0 "REQUEST_NOT_ACTIVE" ;
VAL_ 522 HVP_fcLinkAllowedToEnergize 1 "FC_LINK_ENERGY_AC" 2 "FC_LINK_ENERGY_DC" 0 "FC_LINK_ENERGY_NONE" ;
VAL_ 522 HVP_hvilStatus 2 "CURRENT_SOURCE_FAULT" 3 "INTERNAL_OPEN_FAULT" 8 "NO_12V_SUPPLY" 5 "PENTHOUSE_LID_OPEN_FAULT" 1 "STATUS_OK" 0 "UNKNOWN" 6 "UNKNOWN_LOCATION_OPEN_FAULT" 7 "VEHICLE_NODE_FAULT" 4 "VEHICLE_OPEN_FAULT" 9 "VEHICLE_OR_PENTHOUSE_LID_OPEN_FAULT" ;
VAL_ 522 HVP_packContNegativeState 3 "CONTACTOR_STATE_BLOCKED" 6 "CONTACTOR_STATE_ECONOMIZED" 1 "CONTACTOR_STATE_OPEN" 5 "CONTACTOR_STATE_OPENING" 2 "CONTACTOR_STATE_PRECHARGE" 4 "CONTACTOR_STATE_PULLED_IN" 0 "CONTACTOR_STATE_SNA" 7 "CONTACTOR_STATE_WELDED" ;
VAL_ 522 HVP_packContPositiveState 3 "CONTACTOR_STATE_BLOCKED" 6 "CONTACTOR_STATE_ECONOMIZED" 1 "CONTACTOR_STATE_OPEN" 5 "CONTACTOR_STATE_OPENING" 2 "CONTACTOR_STATE_PRECHARGE" 4 "CONTACTOR_STATE_PULLED_IN" 0 "CONTACTOR_STATE_SNA" 7 "CONTACTOR_STATE_WELDED" ;
VAL_ 522 HVP_packContactorSetState 3 "CONTACTOR_SET_STATE_BLOCKED" 5 "CONTACTOR_SET_STATE_CLOSED" 2 "CONTACTOR_SET_STATE_CLOSING" 9 "CONTACTOR_SET_STATE_NEGATIVE_CLOSED" 1 "CONTACTOR_SET_STATE_OPEN" 4 "CONTACTOR_SET_STATE_OPENING" 6 "CONTACTOR_SET_STATE_PARTIAL_WELD" 8 "CONTACTOR_SET_STATE_POSITIVE_CLOSED" 0 "CONTACTOR_SET_STATE_SNA" 7 "CONTACTOR_SET_STATE_WELDED" ;
VAL_ 522 HVP_packCtrsRequestStatus 1 "REQUEST_ACTIVE" 2 "REQUEST_COMPLETED" 0 "REQUEST_NOT_ACTIVE" ;
VAL_ 526 PARK_sdiSensor1RawDistData 0 "BLOCKED" 1 "NEAR_DETECTION" 500 "NO_OBJECT_DETECTED" 511 "SNA" ;
VAL_ 526 PARK_sdiSensor2RawDistData 0 "BLOCKED" 1 "NEAR_DETECTION" 500 "NO_OBJECT_DETECTED" 511 "SNA" ;
VAL_ 526 PARK_sdiSensor3RawDistData 0 "BLOCKED" 1 "NEAR_DETECTION" 500 "NO_OBJECT_DETECTED" 511 "SNA" ;
VAL_ 526 PARK_sdiSensor4RawDistData 0 "BLOCKED" 1 "NEAR_DETECTION" 500 "NO_OBJECT_DETECTED" 511 "SNA" ;
VAL_ 526 PARK_sdiSensor5RawDistData 0 "BLOCKED" 1 "NEAR_DETECTION" 500 "NO_OBJECT_DETECTED" 511 "SNA" ;
VAL_ 526 PARK_sdiSensor6RawDistData 0 "BLOCKED" 1 "NEAR_DETECTION" 500 "NO_OBJECT_DETECTED" 511 "SNA" ;
VAL_ 537 VCSEC_TPMSDataIndex 0 "TPMS_DATA_SENSOR_0" 1 "TPMS_DATA_SENSOR_1" 2 "TPMS_DATA_SENSOR_2" 3 "TPMS_DATA_SENSOR_3" ;
VAL_ 537 VCSEC_TPMSBatVoltage0 255 "SNA" ;
VAL_ 537 VCSEC_TPMSBatVoltage1 255 "SNA" ;
VAL_ 537 VCSEC_TPMSBatVoltage2 255 "SNA" ;
VAL_ 537 VCSEC_TPMSBatVoltage3 255 "SNA" ;
VAL_ 537 VCSEC_TPMSLocation0 0 "LOCATION_FL" 1 "LOCATION_FR" 2 "LOCATION_RL" 3 "LOCATION_RR" 4 "LOCATION_UNKNOWN" ;
VAL_ 537 VCSEC_TPMSLocation1 0 "LOCATION_FL" 1 "LOCATION_FR" 2 "LOCATION_RL" 3 "LOCATION_RR" 4 "LOCATION_UNKNOWN" ;
VAL_ 537 VCSEC_TPMSLocation2 0 "LOCATION_FL" 1 "LOCATION_FR" 2 "LOCATION_RL" 3 "LOCATION_RR" 4 "LOCATION_UNKNOWN" ;
VAL_ 537 VCSEC_TPMSLocation3 0 "LOCATION_FL" 1 "LOCATION_FR" 2 "LOCATION_RL" 3 "LOCATION_RR" 4 "LOCATION_UNKNOWN" ;
VAL_ 537 VCSEC_TPMSPressure0 255 "SNA" ;
VAL_ 537 VCSEC_TPMSPressure1 255 "SNA" ;
VAL_ 537 VCSEC_TPMSPressure2 255 "SNA" ;
VAL_ 537 VCSEC_TPMSPressure3 255 "SNA" ;
VAL_ 537 VCSEC_TPMSTemperature0 255 "SNA" ;
VAL_ 537 VCSEC_TPMSTemperature1 255 "SNA" ;
VAL_ 537 VCSEC_TPMSTemperature2 255 "SNA" ;
VAL_ 537 VCSEC_TPMSTemperature3 255 "SNA" ;
VAL_ 1066 VCSEC_TPMSConnectionTypeCurrent0 0 "CONNECTIONTYPE_FAST" 1 "CONNECTIONTYPE_SLOW" 2 "CONNECTIONTYPE_UNKNOWN" ;
VAL_ 1066 VCSEC_TPMSConnectionTypeCurrent1 0 "CONNECTIONTYPE_FAST" 1 "CONNECTIONTYPE_SLOW" 2 "CONNECTIONTYPE_UNKNOWN" ;
VAL_ 1066 VCSEC_TPMSConnectionTypeCurrent2 0 "CONNECTIONTYPE_FAST" 1 "CONNECTIONTYPE_SLOW" 2 "CONNECTIONTYPE_UNKNOWN" ;
VAL_ 1066 VCSEC_TPMSConnectionTypeCurrent3 0 "CONNECTIONTYPE_FAST" 1 "CONNECTIONTYPE_SLOW" 2 "CONNECTIONTYPE_UNKNOWN" ;
VAL_ 1066 VCSEC_TPMSConnectionTypeDesired0 0 "CONNECTIONTYPE_FAST" 1 "CONNECTIONTYPE_SLOW" 2 "CONNECTIONTYPE_UNKNOWN" ;
VAL_ 1066 VCSEC_TPMSConnectionTypeDesired1 0 "CONNECTIONTYPE_FAST" 1 "CONNECTIONTYPE_SLOW" 2 "CONNECTIONTYPE_UNKNOWN" ;
VAL_ 1066 VCSEC_TPMSConnectionTypeDesired2 0 "CONNECTIONTYPE_FAST" 1 "CONNECTIONTYPE_SLOW" 2 "CONNECTIONTYPE_UNKNOWN" ;
VAL_ 1066 VCSEC_TPMSConnectionTypeDesired3 0 "CONNECTIONTYPE_FAST" 1 "CONNECTIONTYPE_SLOW" 2 "CONNECTIONTYPE_UNKNOWN" ;
VAL_ 1066 VCSEC_TPMSSensorState0 3 "SENSOR_CONNECTED" 4 "SENSOR_DISCONNECTING" 0 "SENSOR_NOT_PAIRED" 1 "SENSOR_WAIT_FOR_ADV" 2 "SENSOR_WAIT_FOR_CONN" ;
VAL_ 1066 VCSEC_TPMSSensorState1 3 "SENSOR_CONNECTED" 4 "SENSOR_DISCONNECTING" 0 "SENSOR_NOT_PAIRED" 1 "SENSOR_WAIT_FOR_ADV" 2 "SENSOR_WAIT_FOR_CONN" ;
VAL_ 1066 VCSEC_TPMSSensorState2 3 "SENSOR_CONNECTED" 4 "SENSOR_DISCONNECTING" 0 "SENSOR_NOT_PAIRED" 1 "SENSOR_WAIT_FOR_ADV" 2 "SENSOR_WAIT_FOR_CONN" ;
VAL_ 1066 VCSEC_TPMSSensorState3 3 "SENSOR_CONNECTED" 4 "SENSOR_DISCONNECTING" 0 "SENSOR_NOT_PAIRED" 1 "SENSOR_WAIT_FOR_ADV" 2 "SENSOR_WAIT_FOR_CONN" ;
VAL_ 558 PARK_sdiSensor10RawDistData 0 "BLOCKED" 1 "NEAR_DETECTION" 500 "NO_OBJECT_DETECTED" 511 "SNA" ;
VAL_ 558 PARK_sdiSensor11RawDistData 0 "BLOCKED" 1 "NEAR_DETECTION" 500 "NO_OBJECT_DETECTED" 511 "SNA" ;
VAL_ 558 PARK_sdiSensor12RawDistData 0 "BLOCKED" 1 "NEAR_DETECTION" 500 "NO_OBJECT_DETECTED" 511 "SNA" ;
VAL_ 558 PARK_sdiSensor7RawDistData 0 "BLOCKED" 1 "NEAR_DETECTION" 500 "NO_OBJECT_DETECTED" 511 "SNA" ;
VAL_ 558 PARK_sdiSensor8RawDistData 0 "BLOCKED" 1 "NEAR_DETECTION" 500 "NO_OBJECT_DETECTED" 511 "SNA" ;
VAL_ 558 PARK_sdiSensor9RawDistData 0 "BLOCKED" 1 "NEAR_DETECTION" 500 "NO_OBJECT_DETECTED" 511 "SNA" ;
VAL_ 568 UI_countryCode 1023 "SNA" 0 "UNKNOWN" ;
VAL_ 568 UI_mapSpeedLimit 3 "LESS_OR_EQ_10" 21 "LESS_OR_EQ_100" 22 "LESS_OR_EQ_105" 23 "LESS_OR_EQ_110" 24 "LESS_OR_EQ_115" 25 "LESS_OR_EQ_120" 26 "LESS_OR_EQ_130" 27 "LESS_OR_EQ_140" 4 "LESS_OR_EQ_15" 28 "LESS_OR_EQ_150" 29 "LESS_OR_EQ_160" 5 "LESS_OR_EQ_20" 6 "LESS_OR_EQ_25" 7 "LESS_OR_EQ_30" 8 "LESS_OR_EQ_35" 9 "LESS_OR_EQ_40" 10 "LESS_OR_EQ_45" 1 "LESS_OR_EQ_5" 11 "LESS_OR_EQ_50" 12 "LESS_OR_EQ_55" 13 "LESS_OR_EQ_60" 14 "LESS_OR_EQ_65" 2 "LESS_OR_EQ_7" 15 "LESS_OR_EQ_70" 16 "LESS_OR_EQ_75" 17 "LESS_OR_EQ_80" 18 "LESS_OR_EQ_85" 19 "LESS_OR_EQ_90" 20 "LESS_OR_EQ_95" 31 "SNA" 0 "UNKNOWN" 30 "UNLIMITED" ;
VAL_ 568 UI_mapSpeedLimitDependency 6 "LANE" 0 "NONE" 2 "RAIN" 1 "SCHOOL" 5 "SEASON" 7 "SNA" 3 "SNOW" 4 "TIME" ;
VAL_ 568 UI_mapSpeedLimitType 2 "ADVISORY" 4 "BUMPS" 3 "DEPENDENT" 1 "REGULAR" 7 "UNKNOWN_SNA" ;
VAL_ 568 UI_mapSpeedUnits 1 "KPH" 0 "MPH" ;
VAL_ 568 UI_nextBranchDist 31 "SNA" ;
VAL_ 568 UI_roadClass 1 "CLASS_1_MAJOR" 2 "CLASS_2" 3 "CLASS_3" 4 "CLASS_4" 5 "CLASS_5" 6 "CLASS_6_MINOR" 0 "UNKNOWN_INVALID_SNA" ;
VAL_ 569 DAS_leftFork 1 "LEFT_FORK_AVAILABLE" 0 "LEFT_FORK_NONE" 2 "LEFT_FORK_SELECTED" 3 "LEFT_FORK_UNAVAILABLE" ;
VAL_ 569 DAS_leftLineUsage 1 "AVAILABLE" 3 "BLACKLISTED" 2 "FUSED" 0 "REJECTED_UNAVAILABLE" ;
VAL_ 569 DAS_rightFork 1 "RIGHT_FORK_AVAILABLE" 0 "RIGHT_FORK_NONE" 2 "RIGHT_FORK_SELECTED" 3 "RIGHT_FORK_UNAVAILABLE" ;
VAL_ 569 DAS_rightLineUsage 1 "AVAILABLE" 3 "BLACKLISTED" 2 "FUSED" 0 "REJECTED_UNAVAILABLE" ;
VAL_ 583 DAS_alcInternalState 2 "ALC_ABORTING" 8 "ALC_ACTIVE_ACC_LEFT" 9 "ALC_ACTIVE_ACC_RIGHT" 6 "ALC_ACTIVE_LEFT" 7 "ALC_ACTIVE_RIGHT" 3 "ALC_BEHAVIOR_CHECK" 0 "ALC_DISABLED" 1 "ALC_IDLE" 4 "ALC_PRE_ACTIVE_LEFT" 5 "ALC_PRE_ACTIVE_RIGHT" 12 "ALC_RETRY" 10 "ALC_SOFT_ABORTING_LEFT" 11 "ALC_SOFT_ABORTING_RIGHT" ;
VAL_ 583 DAS_arbiterBehavior 4 "ARBITER_CITY_STREETS" 0 "ARBITER_INVALID" 1 "ARBITER_IN_LANE" 2 "ARBITER_LANE_CHANGE_LEFT" 3 "ARBITER_LANE_CHANGE_RIGHT" ;
VAL_ 583 DAS_autopilotAbortReason 21 "ABORT_ACC_CANCEL_GENERIC" 22 "ABORT_ACC_CANCEL_SILENT" 23 "ABORT_ACC_FAULT" 33 "ABORT_AEB" 18 "ABORT_CAMERA_CALIBRATION" 17 "ABORT_CAMERA_FAILSAFES" 32 "ABORT_CONTROLLER_BAD_REF_UPDATE" 27 "ABORT_CONTROLLER_NOT_ALLOWED" 25 "ABORT_CONTROLLER_REFERENCE" 34 "ABORT_CONTROLLER_REF_TOO_SHORT" 26 "ABORT_CONTROLLER_SOLVER" 31 "ABORT_CONTROLLER_STALE_LOCALIZATION" 30 "ABORT_CONTROLLER_STALE_REFERENCE" 10 "ABORT_CRUISE_FAULT" 11 "ABORT_CRUISE_NOT_ACTIVE" 2 "ABORT_DI_MIA" 16 "ABORT_EPAS_EAC_ERROR" 15 "ABORT_EPAS_EAC_NOT_ACTIVE" 4 "ABORT_EPAS_MIA" 39 "ABORT_EPAS_STEERING_ANGLE_INVALID" 3 "ABORT_ESP_MIA" 36 "ABORT_GORE_INCURSION" 5 "ABORT_GTW_MIA" 48 "ABORT_HEADLIGHT_OFF_AT_NIGHT" 47 "ABORT_IBOOSTER_MIA" 46 "ABORT_INTEGRATOR_HEALTH_CRITICAL" 41 "ABORT_INVALID_DI_PEDAL_POS" 42 "ABORT_INVALID_VEHICLE_SPEED" 29 "ABORT_MAP_HEALTH" 35 "ABORT_MISSION_PLANNER_NO_VISION_LANES_FOUND" 0 "ABORT_NONE" 49 "ABORT_ONCOMING_LANE" 43 "ABORT_PERCEPTION_HEALTH_VISION" 19 "ABORT_RADAR_BLIND" 20 "ABORT_RADAR_FAULT" 7 "ABORT_RADAR_MIA" 37 "ABORT_REACHED_END_OF_NAV_STOP" 255 "ABORT_REASON_MAX" 24 "ABORT_ROAD_ESTIMATOR_HEALTH" 6 "ABORT_SCCM_MIA" 44 "ABORT_SEATBELT_UNBUCKLED" 38 "ABORT_STEERING_SATURATED_LANE_DEPARTURE" 28 "ABORT_THERMAL_ISSUE" 13 "ABORT_TRAILER_MODE_ACTIVE" 12 "ABORT_USER_DISABLED" 45 "ABORT_USER_OVERRIDE_STRIKEOUT" 8 "ABORT_VCFRONT_MIA" 9 "ABORT_VCRIGHT_MIA" 14 "ABORT_VEHICLE_SPEED_ABOVE_MAX" 40 "ABORT_W048_FEATURES_DISABLED" 1 "ABORT_WATCHDOG_HEALTH" ;
VAL_ 583 DAS_behaviorReport 30 "BEHAVIOR_ACTIVE_SAFETY_SLOWDOWN" 40 "BEHAVIOR_CROSSWALK" 41 "BEHAVIOR_CROSS_TRAFFIC_AVOIDANCE" 2 "BEHAVIOR_CURVE_SPEED_ADAPTATION" 35 "BEHAVIOR_CUTIN_VEHICLE" 21 "BEHAVIOR_CUTIN_VEHICLE_LEFT" 22 "BEHAVIOR_CUTIN_VEHICLE_RIGHT" 14 "BEHAVIOR_DRIVABLE_SPACE_VIOLATION" 32 "BEHAVIOR_END_OF_NAV_ROUTE" 5 "BEHAVIOR_FLEET_SPEEDS" 8 "BEHAVIOR_IN_LANE_VEHICLE" 4 "BEHAVIOR_KEEP_CALM" 33 "BEHAVIOR_LANE_SPEED_DIFF" 13 "BEHAVIOR_MAP_LANE_GEOMETRY" 19 "BEHAVIOR_MERGE_VEHICLE_LEFT" 20 "BEHAVIOR_MERGE_VEHICLE_RIGHT" 29 "BEHAVIOR_MP_AP_INACTIVE" 23 "BEHAVIOR_MP_AP_RESTRICTION" 26 "BEHAVIOR_MP_AP_STATE_MACHINE" 27 "BEHAVIOR_MP_DI_CRUISE" 25 "BEHAVIOR_MP_DRIVER_MONITOR" 24 "BEHAVIOR_MP_NOT_BUCKLED" 28 "BEHAVIOR_MP_ULC" 17 "BEHAVIOR_NAV_FLEET_SPEEDS" 18 "BEHAVIOR_NAV_PATH_CSA" 3 "BEHAVIOR_RADAR_ONLY_BRAKING" 39 "BEHAVIOR_RELEVANT_VRU" 38 "BEHAVIOR_RISK_MANAGER" 43 "BEHAVIOR_ROUNDABOUT" 15 "BEHAVIOR_SLOWING_FOR_TARGET_LANE" 34 "BEHAVIOR_STATIC_OBJECT" 36 "BEHAVIOR_STATIC_OBJECT_MERGE_LEFT" 37 "BEHAVIOR_STATIC_OBJECT_MERGE_RIGHT" 31 "BEHAVIOR_STEERING_SATURATED" 9 "BEHAVIOR_TARGET_LANE_VEHICLE" 42 "BEHAVIOR_TOLLBOOTH" 11 "BEHAVIOR_TRAFFIC_CONTROL" 6 "BEHAVIOR_TRAFFIC_CONTROL_STOPPED_STATE" 7 "BEHAVIOR_UNDERTAKE_ASSIST_KEEP_CALM" 10 "BEHAVIOR_UNDERTAKE_VEHICLE" 1 "BEHAVIOR_VIEW_RANGE" 12 "BEHAVIOR_VISION_LANE_GEOMETRY" 16 "BEHAVIOR_VISION_SPEEDS" ;
VAL_ 583 DAS_controllerHealth 2 "CONTROLLER_CRITICAL" 1 "CONTROLLER_DEGRADED" 0 "CONTROLLER_HEALTHY" 3 "CONTROLLER_SOLVER_FAILURE" ;
VAL_ 583 DAS_controllerRef 4 "CONTROLLER_REFERENCE_BAD_REF_UPDATE" 0 "CONTROLLER_REFERENCE_HEALTHY" 6 "CONTROLLER_REFERENCE_INDETERMINATE" 5 "CONTROLLER_REFERENCE_REF_TOO_SHORT" 3 "CONTROLLER_REFERENCE_STALE_LOCALIZATION" 2 "CONTROLLER_REFERENCE_STALE_REFERENCE" 1 "CONTROLLER_REFERENCE_UNHEALTHY" ;
VAL_ 583 DAS_forkState 18 "FORK_ABORT_BLINKER_CHANGE" 17 "FORK_ABORT_CONTROL_INACTIVE" 21 "FORK_ABORT_DISALLOW" 19 "FORK_ABORT_NOT_LEFT_LANE" 20 "FORK_ABORT_NOT_RIGHT_LANE" 22 "FORK_ABORT_OTHER" 12 "FORK_ACTIVE_LEFT_NAV" 13 "FORK_ACTIVE_LEFT_USER" 14 "FORK_ACTIVE_RIGHT_NAV" 15 "FORK_ACTIVE_RIGHT_USER" 16 "FORK_FORK_COMPLETE" 8 "FORK_IDLE_BOTH_FORKS_AVAILABLE" 9 "FORK_IDLE_LEFT_FORK_AVAILABLE" 11 "FORK_IDLE_NO_FORKS_AVAILABLE" 10 "FORK_IDLE_RIGHT_FORK_AVAILABLE" 0 "FORK_INVALID" 25 "FORK_PRE_ACTIVE_LEFT_NAV" 26 "FORK_PRE_ACTIVE_RIGHT_NAV" 2 "FORK_UNAVAILABLE_AP_INACTIVE" 3 "FORK_UNAVAILABLE_CONSTRUCTION" 4 "FORK_UNAVAILABLE_CONTROLLED_ACCESS_TOO_FAR" 1 "FORK_UNAVAILABLE_DISABLED" 5 "FORK_UNAVAILABLE_DON_INACTIVE" 27 "FORK_UNAVAILABLE_INTERSECTION_ACTIVE" 7 "FORK_UNAVAILABLE_OTHER" 23 "FORK_UNAVAILABLE_TIGHT_TURN_RADIUS" 6 "FORK_UNAVAILABLE_TOLL_BOOTH" 24 "FORK_UNAVAILABLE_WEATHER" ;
VAL_ 583 DAS_laneChangeState 19 "LANE_CHANGE_ABORTING_ACC_AUTOSTEER_ACTIVATED" 26 "LANE_CHANGE_ABORTING_ALC_REQUEST_BEFORE_ULC_CONFIRM" 23 "LANE_CHANGE_ABORTING_BEHAVIOR_CHANGED" 22 "LANE_CHANGE_ABORTING_BELOW_MIN_SPEED" 14 "LANE_CHANGE_ABORTING_BLIND_SPOT_OCCUPIED" 12 "LANE_CHANGE_ABORTING_BLINKER" 32 "LANE_CHANGE_ABORTING_CONSTRUCTION_DETECTED" 43 "LANE_CHANGE_ABORTING_DESTINATION_LANE_UNSTABLE" 17 "LANE_CHANGE_ABORTING_FORK_AVAILABLE" 31 "LANE_CHANGE_ABORTING_GORE_POINT" 24 "LANE_CHANGE_ABORTING_HIGH_ALC_PROGRESS_ERROR" 11 "LANE_CHANGE_ABORTING_INACTIVE" 21 "LANE_CHANGE_ABORTING_INVALID_BEHAVIOR" 15 "LANE_CHANGE_ABORTING_INVALID_MODE" 16 "LANE_CHANGE_ABORTING_LINE_TYPE" 18 "LANE_CHANGE_ABORTING_LOST_VISION_POSE" 37 "LANE_CHANGE_ABORTING_NO_HANDS_ON" 40 "LANE_CHANGE_ABORTING_SNOOZED" 39 "LANE_CHANGE_ABORTING_SOURCE_AND_TARGET_LANES_MERGED" 34 "LANE_CHANGE_ABORTING_TIGHT_TURN_RADIUS" 13 "LANE_CHANGE_ABORTING_TIMEOUT" 33 "LANE_CHANGE_ABORTING_TOLL_BOOTH_DETECTED" 20 "LANE_CHANGE_ABORTING_ULC_BLINKER_TIMEOUT" 25 "LANE_CHANGE_ABORTING_ULC_CONFIRMATION_TIMEOUT" 35 "LANE_CHANGE_ABORTING_WEATHER" 10 "LANE_CHANGE_AVAILABLE_BOTH" 8 "LANE_CHANGE_AVAILABLE_LEFT_ONLY" 9 "LANE_CHANGE_AVAILABLE_RIGHT_ONLY" 29 "LANE_CHANGE_BLOCKED_LEFT" 30 "LANE_CHANGE_BLOCKED_RIGHT" 27 "LANE_CHANGE_IN_PROGRESS_LEFT" 28 "LANE_CHANGE_IN_PROGRESS_RIGHT" 42 "LANE_CHANGE_UNAVAILABLE_AUTOPILOT_ABORTING" 36 "LANE_CHANGE_UNAVAILABLE_BLINDSPOT_RESTRICTED" 41 "LANE_CHANGE_UNAVAILABLE_BLINKER_LATCHED" 0 "LANE_CHANGE_UNAVAILABLE_DISABLED" 5 "LANE_CHANGE_UNAVAILABLE_FORK_MODE" 4 "LANE_CHANGE_UNAVAILABLE_INACTIVE" 7 "LANE_CHANGE_UNAVAILABLE_INVALID_MODE" 3 "LANE_CHANGE_UNAVAILABLE_NO_LANES" 38 "LANE_CHANGE_UNAVAILABLE_NO_REAR_OBJECT" 1 "LANE_CHANGE_UNAVAILABLE_ROAD_NOT_APPROPRIATE" 2 "LANE_CHANGE_UNAVAILABLE_SPEED" 6 "LANE_CHANGE_UNAVAILABLE_ULTRASONICS_NOT_READY" 63 "LANE_CHANGE_UNKNOWN" ;
VAL_ 583 DAS_lastWatchdogCode 68 "ACTIVE_SAFETY_FAILED" 51 "AP_STATE_MACHINE_FAILED" 50 "ARBITER_FAILED" 57 "ATLAS_FAILED" 79 "BEV_GRAPH_FAILED" 77 "BRIDGE_FAILED" 67 "CAMERA_FAILED" 45 "CAN_RX_FAILED" 46 "CAN_TX_FAILED" 78 "CITY_STREETS_BEHAVIOR_FAILED" 74 "CLIP_LOGGER_FAILED" 52 "CONTROLLER_FAILED" 75 "DRIVABLE_SPACE_TRACKER_FAILED" 65 "DRIVER_MONITOR_FAILED" 70 "DYNAMICS_FAILED" 71 "FIELD_CALIBRATION_FAILED" 49 "GPS_FAILED" 73 "HW_MONITOR_FAILED" 61 "IMU_FAILED" 48 "INERTIATOR_FAILED" 63 "LANE_CHANGE_BEHAVIOR_FAILED" 43 "LEGACY_FAILED" 53 "LOCALIZER_FAILED" 66 "MAP_MANAGER_FAILED" 54 "MISSION_PLANNER_FAILED" 0 "NO_TASK_FAILED" 72 "PARKING_BEHAVIOR_FAILED" 55 "PERCEPTION_FAILED" 60 "RAIN_LIGHT_SENSING_FAILED" 56 "ROAD_ESTIMATOR_FAILED" 76 "SCHEDULER_FAILED" 41 "SNAPSHOT_FAILED" 59 "SNAPSHOT_TRIGGER_CLIENT_FAILED" 58 "STAY_IN_LANE_BEHAVIOR_FAILED" 40 "TELEMETRY_FAILED" 39 "TELEMETRY_PACKAGER_FAILED" 47 "TEMPERATURE_MONITOR_FAILED" 62 "UBX_LOG_FAILED" 69 "UI_SERVER_FAILED" 80 "ULTRASONICS_FAILED" 30 "UNKNOWN_TASK_FAILED" 42 "VISION_FAILED" 44 "WATCHDOG_FAILED" ;
VAL_ 583 DAS_mapAvailability 1 "APM_MAP_AVAILABLE" 0 "APM_MAP_NOT_AVAILABLE" ;
VAL_ 583 DAS_roadEstimator 3 "ROAD_ESTIMATOR_CRITICAL" 2 "ROAD_ESTIMATOR_DEGRADED" 0 "ROAD_ESTIMATOR_HEALTHY" 1 "ROAD_ESTIMATOR_UNSTABLE_MEASUREMENTS" ;
VAL_ 583 DAS_rqstedBehaviorStatus 19 "RQST_BEHAVIOR_BAD_ORIGIN_UPDATE" 9 "RQST_BEHAVIOR_BLOCKED_BY_BLINDSPOT_CAMERA_INVALID_L" 14 "RQST_BEHAVIOR_BLOCKED_BY_BLINDSPOT_CAMERA_INVALID_R" 8 "RQST_BEHAVIOR_BLOCKED_BY_BLINDSPOT_CAMERA_L" 13 "RQST_BEHAVIOR_BLOCKED_BY_BLINDSPOT_CAMERA_R" 11 "RQST_BEHAVIOR_BLOCKED_BY_LANE_TYPE_L" 16 "RQST_BEHAVIOR_BLOCKED_BY_LANE_TYPE_R" 20 "RQST_BEHAVIOR_BLOCKED_BY_SLOW_TARGET_L" 21 "RQST_BEHAVIOR_BLOCKED_BY_SLOW_TARGET_R" 10 "RQST_BEHAVIOR_BLOCKED_BY_ULTRASOUND_AND_CAMERA_L" 15 "RQST_BEHAVIOR_BLOCKED_BY_ULTRASOUND_AND_CAMERA_R" 7 "RQST_BEHAVIOR_BLOCKED_BY_ULTRASOUND_L" 12 "RQST_BEHAVIOR_BLOCKED_BY_ULTRASOUND_R" 6 "RQST_BEHAVIOR_BUILD_ARGUMENT_FAIL" 22 "RQST_BEHAVIOR_INVALID_PLAN" 3 "RQST_BEHAVIOR_MAP_NOT_INITIALIZED" 2 "RQST_BEHAVIOR_NO_DEST_POLYLANE" 4 "RQST_BEHAVIOR_NO_SOURCE_LANE_ON_MAP" 1 "RQST_BEHAVIOR_NO_SRC_POLYLANE" 5 "RQST_BEHAVIOR_NO_TARGET_LANE_ON_MAP" 18 "RQST_BEHAVIOR_OUT_OF_DATE" 17 "RQST_BEHAVIOR_ROAD_NOT_APPROPRIATE" 0 "RQST_BEHAVIOR_VALID" ;
VAL_ 586 DAS_accSmartSpeedState 2 "ACTIVE_INTEGRATING" 1 "ACTIVE_OFFRAMP" 3 "ACTIVE_ONRAMP" 0 "NOT_ACTIVE" 5 "OFFRAMP_DELAY" 4 "SET_SPEED_SET_REQUESTED" 7 "SNA" ;
VAL_ 586 DAS_autosteerBottsDotsUsage 1 "AVAILABLE" 3 "BLACKLISTED" 2 "FUSED" 0 "REJECTED_UNAVAILABLE" ;
VAL_ 586 DAS_autosteerHPPUsage 1 "AVAILABLE" 3 "BLACKLISTED" 2 "FUSED" 0 "REJECTED_UNAVAILABLE" ;
VAL_ 586 DAS_autosteerHealthState 4 "HEALTH_ABORTING" 2 "HEALTH_DEGRADED" 5 "HEALTH_FAULT" 1 "HEALTH_NOMINAL" 3 "HEALTH_SEVERELY_DEGRADED" 0 "HEALTH_UNAVAILABLE" ;
VAL_ 586 DAS_autosteerModelUsage 1 "AVAILABLE" 3 "BLACKLISTED" 2 "FUSED" 0 "REJECTED_UNAVAILABLE" ;
VAL_ 586 DAS_autosteerNavigationUsage 1 "AVAILABLE" 3 "BLACKLISTED" 2 "FUSED" 0 "REJECTED_UNAVAILABLE" ;
VAL_ 586 DAS_autosteerVehiclesUsage 1 "AVAILABLE" 3 "BLACKLISTED" 2 "FUSED" 0 "REJECTED_UNAVAILABLE" ;
VAL_ 586 DAS_behaviorType 0 "DAS_BEHAVIOR_INVALID" 1 "DAS_BEHAVIOR_IN_LANE" 2 "DAS_BEHAVIOR_LANE_CHANGE_LEFT" 3 "DAS_BEHAVIOR_LANE_CHANGE_RIGHT" ;
VAL_ 586 DAS_lastAutosteerAbortReason 29 "UI_ABORT_REASON_ACC_CANCEL" 32 "UI_ABORT_REASON_AEB" 14 "UI_ABORT_REASON_APP_ME_STATE_NOT_VISION" 30 "UI_ABORT_REASON_CAMERA_FAILSAFES" 16 "UI_ABORT_REASON_CAM_MSG_MIA" 17 "UI_ABORT_REASON_CAM_WATCHDOG" 23 "UI_ABORT_REASON_CID_SWITCH_DISABLED" 21 "UI_ABORT_REASON_COMPONENT_MIA" 22 "UI_ABORT_REASON_CRUISE_FAULT" 24 "UI_ABORT_REASON_DRIVING_OFF_NAV" 20 "UI_ABORT_REASON_EPAS_EAC_DENIED" 28 "UI_ABORT_REASON_EPAS_ERROR_CODE" 26 "UI_ABORT_REASON_FOLLOWER_OUTPUT_INVALID" 0 "UI_ABORT_REASON_HM_LANE_VIEW_RANGE" 2 "UI_ABORT_REASON_HM_STEERING_ERROR" 1 "UI_ABORT_REASON_HM_VIRTUAL_LANE_NO_INPUTS" 15 "UI_ABORT_REASON_ME_MAIN_STATE_NOT_VISION" 31 "UI_ABORT_REASON_NO_ABORT" 27 "UI_ABORT_REASON_PLANNER_OUTPUT_INVALID" 33 "UI_ABORT_REASON_SEATBELT_UNBUCKLED" 19 "UI_ABORT_REASON_SIDE_COLLISION_IMMINENT" 18 "UI_ABORT_REASON_TRAILER_MODE" 34 "UI_ABORT_REASON_USER_OVERRIDE_STRIKEOUT" 25 "UI_ABORT_REASON_VEHICLE_SPEED_ABOVE_MAX" ;
VAL_ 586 DAS_lastLinePreferenceReason 1 "AGREEMENT_WITH_NEIGHBOR_LANES" 4 "AVOID_ONCOMING_LANES" 5 "COUNTRY_DRIVING_SIDE" 3 "NAVIGATION_BRANCH" 2 "NEIGHBOR_LANE_PROBABILIY" 15 "NONE" 0 "OTHER_LANE_DISAGREES_WITH_MODEL" ;
VAL_ 586 DAS_navAvailable 1 "DAS_NAV_AVAILABLE" 0 "DAS_NAV_UNAVAILABLE" ;
VAL_ 586 DAS_offsetSide 0 "NO_OFFSET" 3 "OFFSET_BOTH_OBJECTS" 2 "OFFSET_LEFT_OBJECT" 1 "OFFSET_RIGHT_OBJECT" ;
VAL_ 586 DAS_plannerState 0 "TP_EXTSTATE_DISABLED" 2 "TP_EXTSTATE_FOLLOW" 7 "TP_EXTSTATE_LANECHANGE_ABORT" 4 "TP_EXTSTATE_LANECHANGE_IN_PROGRESS" 3 "TP_EXTSTATE_LANECHANGE_REQUESTED" 6 "TP_EXTSTATE_LANECHANGE_WAIT_FOR_FWD_OBSTACLE" 5 "TP_EXTSTATE_LANECHANGE_WAIT_FOR_SIDE_OBSTACLE" 1 "TP_EXTSTATE_VL" ;
VAL_ 586 DAS_rearLeftVehDetectedCurrent 1 "VEHICLE_DETECTED" 0 "VEHICLE_NOT_DETECTED" ;
VAL_ 586 DAS_rearLeftVehDetectedTrip 1 "VEHICLE_DETECTED" 0 "VEHICLE_NOT_DETECTED" ;
VAL_ 586 DAS_rearRightVehDetectedTrip 1 "VEHICLE_DETECTED" 0 "VEHICLE_NOT_DETECTED" ;
VAL_ 586 DAS_rearVehDetectedThisCycle 1 "VEHICLE_DETECTED" 0 "VEHICLE_NOT_DETECTED" ;
VAL_ 586 DAS_roadSurfaceType 2 "ROAD_SURFACE_ENHANCED" 1 "ROAD_SURFACE_NORMAL" 0 "ROAD_SURFACE_SNA" ;
VAL_ 586 DAS_ulcInProgress 1 "ULC_ACTIVE" 0 "ULC_INACTIVE" ;
VAL_ 586 DAS_ulcType 1 "ULC_TYPE_NAV" 0 "ULC_TYPE_NONE" 2 "ULC_TYPE_SPEED" ;
VAL_ 605 CP_UHF_controlState 3 "CP_UHF_CALIBRATE" 6 "CP_UHF_CHECK_RX" 1 "CP_UHF_CONFIG" 10 "CP_UHF_FAULT" 8 "CP_UHF_HANDLE_FOUND" 2 "CP_UHF_IDLE" 0 "CP_UHF_INIT" 4 "CP_UHF_PREPARE_RX" 7 "CP_UHF_READ_RXFIFO" 5 "CP_UHF_RX" 9 "CP_UHF_SLEEP" ;
VAL_ 605 CP_chargeCablePresent 0 "CABLE_NOT_PRESENT" 1 "CABLE_PRESENT" ;
VAL_ 605 CP_chargeCableState 2 "CHARGE_CABLE_CONNECTED" 1 "CHARGE_CABLE_NOT_CONNECTED" 0 "CHARGE_CABLE_UNKNOWN_SNA" ;
VAL_ 605 CP_coldWeatherMode 1 "CP_COLD_WEATHER_LATCH_MITIGATION" 0 "CP_COLD_WEATHER_NONE" ;
VAL_ 605 CP_doorControlState 5 "CP_doorClosing" 1 "CP_doorIdle" 0 "CP_doorInit" 2 "CP_doorOpenRequested" 3 "CP_doorOpening" 6 "CP_doorSenseClosed" 4 "CP_doorSenseOpen" ;
VAL_ 605 CP_faultLineSensed 0 "FAULT_LINE_CLEARED" 1 "FAULT_LINE_SET" ;
VAL_ 605 CP_inductiveDoorState 7 "CP_INDUCTIVE_DOOR_FAULT" 0 "CP_INDUCTIVE_DOOR_INIT" 1 "CP_INDUCTIVE_DOOR_INIT_FROM_CHARGE" 2 "CP_INDUCTIVE_DOOR_INIT_FROM_DRIVE" 4 "CP_INDUCTIVE_DOOR_NOT_PRESENT" 6 "CP_INDUCTIVE_DOOR_OFF_CHARGE" 5 "CP_INDUCTIVE_DOOR_OFF_DRIVE" 3 "CP_INDUCTIVE_DOOR_PRESENT" ;
VAL_ 605 CP_inductiveSensorState 7 "CP_INDUCTIVE_SENSOR_CONFIG" 5 "CP_INDUCTIVE_SENSOR_FAULT" 0 "CP_INDUCTIVE_SENSOR_INIT" 3 "CP_INDUCTIVE_SENSOR_PAUSE" 1 "CP_INDUCTIVE_SENSOR_POLL" 6 "CP_INDUCTIVE_SENSOR_RESET" 2 "CP_INDUCTIVE_SENSOR_SHUTDOWN" 4 "CP_INDUCTIVE_SENSOR_WAIT_FOR_INIT" ;
VAL_ 605 CP_latch2ControlState 2 "CP_latchDisengageRequested" 4 "CP_latchDisengaged" 3 "CP_latchDisengaging" 5 "CP_latchEngaging" 1 "CP_latchIdle" 0 "CP_latchInit" ;
VAL_ 605 CP_latch2State 3 "CP_LATCH_BLOCKING" 1 "CP_LATCH_DISENGAGED" 2 "CP_LATCH_ENGAGED" 0 "CP_LATCH_SNA" ;
VAL_ 605 CP_latchControlState 2 "CP_latchDisengageRequested" 4 "CP_latchDisengaged" 3 "CP_latchDisengaging" 5 "CP_latchEngaging" 1 "CP_latchIdle" 0 "CP_latchInit" ;
VAL_ 605 CP_latchState 3 "CP_LATCH_BLOCKING" 1 "CP_LATCH_DISENGAGED" 2 "CP_LATCH_ENGAGED" 0 "CP_LATCH_SNA" ;
VAL_ 605 CP_ledColor 7 "CP_LEDS_AMBER" 3 "CP_LEDS_BLUE" 9 "CP_LEDS_DEBUG" 6 "CP_LEDS_FLASHING_AMBER" 10 "CP_LEDS_FLASHING_BLUE" 5 "CP_LEDS_FLASHING_GREEN" 2 "CP_LEDS_GREEN" 0 "CP_LEDS_OFF" 8 "CP_LEDS_RAVE" 1 "CP_LEDS_RED" 4 "CP_LEDS_WHITE" ;
VAL_ 605 CP_type 1 "CP_TYPE_EURO_IEC" 2 "CP_TYPE_GB" 3 "CP_TYPE_IEC_CCS" 0 "CP_TYPE_US_TESLA" ;
VAL_ 697 DAS_accState 1 "ACC_CANCEL_CAMERA_BLIND" 0 "ACC_CANCEL_GENERIC" 13 "ACC_CANCEL_GENERIC_SILENT" 14 "ACC_CANCEL_OUT_OF_CALIBRATION" 12 "ACC_CANCEL_PATH_NOT_CLEAR" 2 "ACC_CANCEL_RADAR_BLIND" 3 "ACC_HOLD" 4 "ACC_ON" 8 "APC_ABORT" 5 "APC_BACKWARD" 7 "APC_COMPLETE" 6 "APC_FORWARD" 9 "APC_PAUSE" 11 "APC_SELFPARK_START" 10 "APC_UNPARK_COMPLETE" 15 "FAULT_SNA" ;
VAL_ 697 DAS_accelMax 511 "SNA" ;
VAL_ 697 DAS_accelMin 511 "SNA" ;
VAL_ 697 DAS_aebEvent 1 "AEB_ACTIVE" 2 "AEB_FAULT" 0 "AEB_NOT_ACTIVE" 3 "AEB_SNA" ;
VAL_ 697 DAS_jerkMax 255 "SNA" ;
VAL_ 697 DAS_jerkMin 511 "SNA" ;
VAL_ 697 DAS_setSpeed 4095 "SNA" ;
VAL_ 723 UI_isSunUp 0 "SUN_DOWN" 3 "SUN_SNA" 1 "SUN_UP" ;
VAL_ 723 UI_solarAzimuthAngle -32768 "SNA" ;
VAL_ 723 UI_solarAzimuthAngleCarRef 255 "SNA" ;
VAL_ 723 UI_solarElevationAngle 127 "SNA" ;
VAL_ 777 DAS_objectId 3 "CUTIN_VEHICLE" 0 "LEAD_VEHICLES" 1 "LEFT_VEHICLES" 2 "RIGHT_VEHICLES" 4 "ROAD_SIGN" 5 "VEHICLE_HEADINGS" ;
VAL_ 777 DAS_cutinVehDx 255 "SNA" ;
VAL_ 777 DAS_cutinVehHeading 255 "SNA" ;
VAL_ 777 DAS_cutinVehId 127 "SNA" ;
VAL_ 777 DAS_cutinVehType 4 "BICYCLE" 2 "CAR" 3 "MOTORCYCLE" 5 "PEDESTRIAN" 1 "TRUCK" 0 "UNKNOWN" ;
VAL_ 777 DAS_cutinVehVxRel 15 "SNA" ;
VAL_ 777 DAS_leadVeh2Dx 255 "SNA" ;
VAL_ 777 DAS_leadVeh2Heading 255 "SNA" ;
VAL_ 777 DAS_leadVeh2Id 0 "SNA" ;
VAL_ 777 DAS_leadVeh2Type 4 "BICYCLE" 2 "CAR" 3 "MOTORCYCLE" 5 "PEDESTRIAN" 1 "TRUCK" 0 "UNKNOWN" ;
VAL_ 777 DAS_leadVeh2VxRel 15 "SNA" ;
VAL_ 777 DAS_leadVehDx 255 "SNA" ;
VAL_ 777 DAS_leadVehHeading 255 "SNA" ;
VAL_ 777 DAS_leadVehId 127 "SNA" ;
VAL_ 777 DAS_leadVehType 4 "BICYCLE" 2 "CAR" 6 "IPSO" 3 "MOTORCYCLE" 5 "PEDESTRIAN" 1 "TRUCK" 0 "UNKNOWN" ;
VAL_ 777 DAS_leadVehVxRel 15 "SNA" ;
VAL_ 777 DAS_leftVeh2Dx 255 "SNA" ;
VAL_ 777 DAS_leftVeh2Heading 255 "SNA" ;
VAL_ 777 DAS_leftVeh2Id 0 "SNA" ;
VAL_ 777 DAS_leftVeh2Type 4 "BICYCLE" 2 "CAR" 3 "MOTORCYCLE" 5 "PEDESTRIAN" 1 "TRUCK" 0 "UNKNOWN" ;
VAL_ 777 DAS_leftVeh2VxRel 15 "SNA" ;
VAL_ 777 DAS_leftVehDx 255 "SNA" ;
VAL_ 777 DAS_leftVehHeading 255 "SNA" ;
VAL_ 777 DAS_leftVehId 127 "SNA" ;
VAL_ 777 DAS_leftVehType 4 "BICYCLE" 2 "CAR" 3 "MOTORCYCLE" 5 "PEDESTRIAN" 1 "TRUCK" 0 "UNKNOWN" ;
VAL_ 777 DAS_leftVehVxRel 15 "SNA" ;
VAL_ 777 DAS_rightVeh2Dx 255 "SNA" ;
VAL_ 777 DAS_rightVeh2Heading 255 "SNA" ;
VAL_ 777 DAS_rightVeh2Id 0 "SNA" ;
VAL_ 777 DAS_rightVeh2Type 4 "BICYCLE" 2 "CAR" 3 "MOTORCYCLE" 5 "PEDESTRIAN" 1 "TRUCK" 0 "UNKNOWN" ;
VAL_ 777 DAS_rightVeh2VxRel 15 "SNA" ;
VAL_ 777 DAS_rightVehDx 255 "SNA" ;
VAL_ 777 DAS_rightVehHeading 255 "SNA" ;
VAL_ 777 DAS_rightVehId 127 "SNA" ;
VAL_ 777 DAS_rightVehType 4 "BICYCLE" 2 "CAR" 3 "MOTORCYCLE" 5 "PEDESTRIAN" 1 "TRUCK" 0 "UNKNOWN" ;
VAL_ 777 DAS_rightVehVxRel 15 "SNA" ;
VAL_ 777 DAS_roadSignArrow 0 "CIRCLE" 1 "LEFT" 2 "RIGHT" 3 "STRAIGHT" 4 "UNKNOWN" ;
VAL_ 777 DAS_roadSignColor 3 "GREEN" 0 "NONE" 1 "RED" 4 "RED_YELLOW" 2 "YELLOW" ;
VAL_ 777 DAS_roadSignId 255 "SNA" 0 "STOP_SIGN" 1 "TRAFFIC_LIGHT" ;
VAL_ 777 DAS_roadSignOrientation 2 "HORIZONTAL_3_LIGHT" 0 "UNKNOWN" 1 "VERTICAL_3_LIGHT" ;
VAL_ 777 DAS_roadSignSource 1 "NAV" 0 "NONE" 2 "VISION" ;
VAL_ 777 DAS_roadSignStopLineDist 1023 "SNA" ;
VAL_ 905 DAS_ACC_report 24 "ACC_REPORT_BEHAVIOR_REPORT" 23 "ACC_REPORT_CAMERA_ONLY" 21 "ACC_REPORT_CIPV_CUTTING_OUT" 10 "ACC_REPORT_CSA" 18 "ACC_REPORT_FLEET_SPEEDS" 13 "ACC_REPORT_LC_EXTERNAL_STATE_ABORTED" 12 "ACC_REPORT_LC_EXTERNAL_STATE_ABORTING" 14 "ACC_REPORT_LC_EXTERNAL_STATE_ACTIVE_RESTRICTED" 11 "ACC_REPORT_LC_HANDS_ON_REQD_STRUCK_OUT" 19 "ACC_REPORT_MCVLR_DPP" 20 "ACC_REPORT_MCVLR_IN_PATH" 22 "ACC_REPORT_RADAR_OBJ_FIVE" 15 "ACC_REPORT_RADAR_OBJ_ONE" 16 "ACC_REPORT_RADAR_OBJ_TWO" 1 "ACC_REPORT_TARGET_CIPV" 5 "ACC_REPORT_TARGET_CUTIN" 2 "ACC_REPORT_TARGET_IN_FRONT_OF_CIPV" 17 "ACC_REPORT_TARGET_MCP" 3 "ACC_REPORT_TARGET_MCVL" 4 "ACC_REPORT_TARGET_MCVR" 0 "ACC_REPORT_TARGET_NONE" 9 "ACC_REPORT_TARGET_TYPE_FAULT" 8 "ACC_REPORT_TARGET_TYPE_IPSO" 6 "ACC_REPORT_TARGET_TYPE_STOP_SIGN" 7 "ACC_REPORT_TARGET_TYPE_TRAFFIC_LIGHT" ;
VAL_ 905 DAS_accSpeedLimit 0 "NONE" 1023 "SNA" ;
VAL_ 905 DAS_activationFailureStatus 1 "LC_ACTIVATION_FAILED_1" 2 "LC_ACTIVATION_FAILED_2" 0 "LC_ACTIVATION_IDLE" ;
VAL_ 905 DAS_csaState 1 "CSA_EXTERNAL_STATE_AVAILABLE" 2 "CSA_EXTERNAL_STATE_ENABLE" 3 "CSA_EXTERNAL_STATE_HOLD" 0 "CSA_EXTERNAL_STATE_UNAVAILABLE" ;
VAL_ 905 DAS_driverInteractionLevel 2 "CONTINUED_DRIVER_NOT_INTERACTING" 0 "DRIVER_INTERACTING" 1 "DRIVER_NOT_INTERACTING" ;
VAL_ 905 DAS_longCollisionWarning 3 "FCM_LONG_COLLISION_WARNING_IPSO" 0 "FCM_LONG_COLLISION_WARNING_NONE" 2 "FCM_LONG_COLLISION_WARNING_PEDESTRIAN" 15 "FCM_LONG_COLLISION_WARNING_SNA" 4 "FCM_LONG_COLLISION_WARNING_STOPSIGN_STOPLINE" 5 "FCM_LONG_COLLISION_WARNING_TFL_STOPLINE" 6 "FCM_LONG_COLLISION_WARNING_VEHICLE_CIPV" 12 "FCM_LONG_COLLISION_WARNING_VEHICLE_CIPV2" 7 "FCM_LONG_COLLISION_WARNING_VEHICLE_CUTIN" 8 "FCM_LONG_COLLISION_WARNING_VEHICLE_MCVL" 9 "FCM_LONG_COLLISION_WARNING_VEHICLE_MCVL2" 10 "FCM_LONG_COLLISION_WARNING_VEHICLE_MCVR" 11 "FCM_LONG_COLLISION_WARNING_VEHICLE_MCVR2" 1 "FCM_LONG_COLLISION_WARNING_VEHICLE_UNKNOWN" ;
VAL_ 905 DAS_pmmCameraFaultReason 1 "PMM_CAMERA_BLOCKED_FRONT" 2 "PMM_CAMERA_INVALID_MIA" 0 "PMM_CAMERA_NO_FAULT" ;
VAL_ 905 DAS_pmmLoggingRequest 0 "FALSE" 1 "TRUE" ;
VAL_ 905 DAS_pmmObstacleSeverity 6 "PMM_ACCEL_LIMIT" 3 "PMM_BRAKE_REQUEST" 5 "PMM_CRASH_FRONT" 4 "PMM_CRASH_REAR" 2 "PMM_IMMINENT_FRONT" 1 "PMM_IMMINENT_REAR" 0 "PMM_NONE" 7 "PMM_SNA" ;
VAL_ 905 DAS_pmmRadarFaultReason 1 "PMM_RADAR_BLOCKED_FRONT" 2 "PMM_RADAR_INVALID_MIA" 0 "PMM_RADAR_NO_FAULT" ;
VAL_ 905 DAS_pmmSysFaultReason 7 "PMM_FAULT_BRAKE_PEDAL_INHIBIT" 1 "PMM_FAULT_DAS_DISABLED" 5 "PMM_FAULT_DISABLED_BY_USER" 3 "PMM_FAULT_DI_FAULT" 0 "PMM_FAULT_NONE" 6 "PMM_FAULT_ROAD_TYPE" 2 "PMM_FAULT_SPEED" 4 "PMM_FAULT_STEERING_ANGLE_RATE" ;
VAL_ 905 DAS_pmmUltrasonicsFaultReason 3 "PMM_ULTRASONICS_BLOCKED_BOTH" 1 "PMM_ULTRASONICS_BLOCKED_FRONT" 2 "PMM_ULTRASONICS_BLOCKED_REAR" 4 "PMM_ULTRASONICS_INVALID_MIA" 0 "PMM_ULTRASONICS_NO_FAULT" ;
VAL_ 905 DAS_ppOffsetDesiredRamp 128 "PP_NO_OFFSET" ;
VAL_ 905 DAS_radarTelemetry 0 "RADAR_TELEMETRY_IDLE" 1 "RADAR_TELEMETRY_NORMAL" 2 "RADAR_TELEMETRY_URGENT" ;
VAL_ 905 DAS_robState 2 "ROB_STATE_ACTIVE" 0 "ROB_STATE_INHIBITED" 3 "ROB_STATE_MAPLESS" 1 "ROB_STATE_MEASURE" ;
VAL_ 921 DAS_autoLaneChangeState 19 "ALC_ABORT_BLINKER_TURNED_OFF" 18 "ALC_ABORT_LC_HEALTH_BAD" 30 "ALC_ABORT_MISSION_PLAN_INVALID" 20 "ALC_ABORT_OTHER_REASON" 17 "ALC_ABORT_POOR_VIEW_RANGE" 15 "ALC_ABORT_SIDE_OBSTACLE_PRESENT_L" 16 "ALC_ABORT_SIDE_OBSTACLE_PRESENT_R" 29 "ALC_ABORT_TIMEOUT" 8 "ALC_AVAILABLE_BOTH" 6 "ALC_AVAILABLE_ONLY_L" 7 "ALC_AVAILABLE_ONLY_R" 26 "ALC_BLOCKED_LANE_TYPE_L" 27 "ALC_BLOCKED_LANE_TYPE_R" 23 "ALC_BLOCKED_VEH_TTC_AND_USS_L" 25 "ALC_BLOCKED_VEH_TTC_AND_USS_R" 22 "ALC_BLOCKED_VEH_TTC_L" 24 "ALC_BLOCKED_VEH_TTC_R" 9 "ALC_IN_PROGRESS_L" 10 "ALC_IN_PROGRESS_R" 31 "ALC_SNA" 0 "ALC_UNAVAILABLE_DISABLED" 4 "ALC_UNAVAILABLE_EXITING_HIGHWAY" 1 "ALC_UNAVAILABLE_NO_LANES" 21 "ALC_UNAVAILABLE_SOLID_LANE_LINE" 2 "ALC_UNAVAILABLE_SONICS_INVALID" 3 "ALC_UNAVAILABLE_TP_FOLLOW" 5 "ALC_UNAVAILABLE_VEHICLE_SPEED" 13 "ALC_WAITING_FOR_FWD_OBST_TO_PASS_L" 14 "ALC_WAITING_FOR_FWD_OBST_TO_PASS_R" 11 "ALC_WAITING_FOR_SIDE_OBST_TO_PASS_L" 12 "ALC_WAITING_FOR_SIDE_OBST_TO_PASS_R" 28 "ALC_WAITING_HANDS_ON" ;
VAL_ 921 DAS_autoparkReady 1 "AUTOPARK_READY" 0 "AUTOPARK_UNAVAILABLE" ;
VAL_ 921 DAS_autopilotHandsOnState 0 "LC_HANDS_ON_NOT_REQD" 4 "LC_HANDS_ON_REQD_CHIME_1" 5 "LC_HANDS_ON_REQD_CHIME_2" 1 "LC_HANDS_ON_REQD_DETECTED" 9 "LC_HANDS_ON_REQD_ESCALATED_CHIME_1" 10 "LC_HANDS_ON_REQD_ESCALATED_CHIME_2" 2 "LC_HANDS_ON_REQD_NOT_DETECTED" 6 "LC_HANDS_ON_REQD_SLOWING" 7 "LC_HANDS_ON_REQD_STRUCK_OUT" 3 "LC_HANDS_ON_REQD_VISUAL" 15 "LC_HANDS_ON_SNA" 8 "LC_HANDS_ON_SUSPENDED" ;
VAL_ 921 DAS_autopilotState 9 "ABORTED" 8 "ABORTING" 5 "ACTIVE_NAV" 3 "ACTIVE_NOMINAL" 4 "ACTIVE_RESTRICTED" 2 "AVAILABLE" 0 "DISABLED" 14 "FAULT" 15 "SNA" 1 "UNAVAILABLE" ;
VAL_ 921 DAS_blindSpotRearLeft 0 "NO_WARNING" 3 "SNA" 1 "WARNING_LEVEL_1" 2 "WARNING_LEVEL_2" ;
VAL_ 921 DAS_blindSpotRearRight 0 "NO_WARNING" 3 "SNA" 1 "WARNING_LEVEL_1" 2 "WARNING_LEVEL_2" ;
VAL_ 921 DAS_fleetSpeedState 2 "FLEETSPEED_ACTIVE" 1 "FLEETSPEED_AVAILABLE" 3 "FLEETSPEED_HOLD" 0 "FLEETSPEED_UNAVAILABLE" ;
VAL_ 921 DAS_forwardCollisionWarning 1 "FORWARD_COLLISION_WARNING" 0 "NONE" 3 "SNA" ;
VAL_ 921 DAS_fusedSpeedLimit 31 "NONE" 0 "UNKNOWN_SNA" ;
VAL_ 921 DAS_heaterState 0 "HEATER_OFF_SNA" 1 "HEATER_ON" ;
VAL_ 921 DAS_laneDepartureWarning 1 "LEFT_WARNING" 3 "LEFT_WARNING_SEVERE" 0 "NONE" 2 "RIGHT_WARNING" 4 "RIGHT_WARNING_SEVERE" 5 "SNA" ;
VAL_ 921 DAS_lssState 6 "LSS_STATE_ABORT" 5 "LSS_STATE_BLINDSPOT" 3 "LSS_STATE_ELK" 0 "LSS_STATE_FAULT" 1 "LSS_STATE_LDW" 2 "LSS_STATE_LKA" 4 "LSS_STATE_MONITOR" 7 "LSS_STATE_OFF" ;
VAL_ 921 DAS_sideCollisionAvoid 1 "AVOID_LEFT" 2 "AVOID_RIGHT" 0 "NONE" 3 "SNA" ;
VAL_ 921 DAS_sideCollisionInhibit 1 "INHIBIT" 0 "NO_INHIBIT" ;
VAL_ 921 DAS_sideCollisionWarning 0 "NONE" 1 "WARN_LEFT" 3 "WARN_LEFT_RIGHT" 2 "WARN_RIGHT" ;
VAL_ 921 DAS_suppressSpeedWarning 0 "Do_Not_Suppress" 1 "Suppress_Speed_Warning" ;
VAL_ 921 DAS_visionOnlySpeedLimit 31 "NONE" 0 "UNKNOWN_SNA" ;
VAL_ 925 IBST_driverBrakeApply 1 "BRAKES_NOT_APPLIED" 2 "DRIVER_APPLYING_BRAKES" 3 "FAULT" 0 "NOT_INIT_OR_OFF" ;
VAL_ 925 IBST_iBoosterStatus 4 "IBOOSTER_ACTIVE_GOOD_CHECK" 6 "IBOOSTER_ACTUATION" 3 "IBOOSTER_DIAGNOSTIC" 2 "IBOOSTER_FAILURE" 1 "IBOOSTER_INIT" 0 "IBOOSTER_OFF" 5 "IBOOSTER_READY" ;
VAL_ 925 IBST_internalState 4 "DIAGNOSTIC" 3 "EXTERNAL_BRAKE_REQUEST" 2 "LOCAL_BRAKE_REQUEST" 0 "NO_MODE_ACTIVE" 6 "POST_DRIVE_CHECK" 1 "PRE_DRIVE_CHECK" 5 "TRANSITION_TO_IDLE" ;
VAL_ 929 VCFRONT_12vStatusForDrive 2 "EXIT_DRIVE_REQUESTED_12V" 0 "NOT_READY_FOR_DRIVE_12V" 1 "READY_FOR_DRIVE_12V" ;
VAL_ 929 VCFRONT_2RowCenterUnbuckled 0 "CHIME_NONE" 1 "CHIME_OCCUPIED_AND_UNBUCKLED" 2 "CHIME_SNA" ;
VAL_ 929 VCFRONT_2RowLeftUnbuckled 0 "CHIME_NONE" 1 "CHIME_OCCUPIED_AND_UNBUCKLED" 2 "CHIME_SNA" ;
VAL_ 929 VCFRONT_2RowRightUnbuckled 0 "CHIME_NONE" 1 "CHIME_OCCUPIED_AND_UNBUCKLED" 2 "CHIME_SNA" ;
VAL_ 929 VCFRONT_APGlassHeaterState 4 "HEATER_STATE_FAULT" 2 "HEATER_STATE_OFF" 3 "HEATER_STATE_OFF_UNAVAILABLE" 1 "HEATER_STATE_ON" 0 "HEATER_STATE_SNA" ;
VAL_ 929 VCFRONT_diPowerOnState 0 "DI_POWERED_OFF" 3 "DI_POWERED_ON_FOR_DRIVE" 2 "DI_POWERED_ON_FOR_STATIONARY_HEAT" 1 "DI_POWERED_ON_FOR_SUMMON" 4 "DI_POWER_GOING_DOWN" ;
VAL_ 929 VCFRONT_driverBuckleStatus 1 "BUCKLED" 0 "UNBUCKLED" ;
VAL_ 929 VCFRONT_driverDoorStatus 1 "DOOR_CLOSED" 0 "DOOR_OPEN" ;
VAL_ 929 VCFRONT_driverUnbuckled 0 "CHIME_NONE" 1 "CHIME_OCCUPIED_AND_UNBUCKLED" 2 "CHIME_SNA" ;
VAL_ 929 VCFRONT_passengerUnbuckled 0 "CHIME_NONE" 1 "CHIME_OCCUPIED_AND_UNBUCKLED" 2 "CHIME_SNA" ;
VAL_ 929 VCFRONT_pcsEFuseVoltage 1023 "SNA" ;
VAL_ 929 VCFRONT_thermalSystemType 1 "HEAT_PUMP_THERMAL_SYSTEM" 0 "LEGACY_THERMAL_SYSTEM" ;
VAL_ 985 UI_conditionalSpeedLimit 31 "SNA" ;
VAL_ 985 UI_mapSpeedLimitUnits 1 "KPH" 0 "MPH" ;
VAL_ 985 UI_userSpeedOffsetUnits 1 "KPH" 0 "MPH" ;
VAL_ 994 VCLEFT_FLMapLightStatus 2 "LIGHT_FAULT" 0 "LIGHT_OFF" 1 "LIGHT_ON" 3 "LIGHT_SNA" ;
VAL_ 994 VCLEFT_FRMapLightStatus 2 "LIGHT_FAULT" 0 "LIGHT_OFF" 1 "LIGHT_ON" 3 "LIGHT_SNA" ;
VAL_ 994 VCLEFT_RLMapLightStatus 2 "LIGHT_FAULT" 0 "LIGHT_OFF" 1 "LIGHT_ON" 3 "LIGHT_SNA" ;
VAL_ 994 VCLEFT_RRMapLightStatus 2 "LIGHT_FAULT" 0 "LIGHT_OFF" 1 "LIGHT_ON" 3 "LIGHT_SNA" ;
VAL_ 994 VCLEFT_brakeLightStatus 2 "LIGHT_FAULT" 0 "LIGHT_OFF" 1 "LIGHT_ON" 3 "LIGHT_SNA" ;
VAL_ 994 VCLEFT_brakeTrailerLightStatus 2 "LIGHT_FAULT" 0 "LIGHT_OFF" 1 "LIGHT_ON" 3 "LIGHT_SNA" ;
VAL_ 994 VCLEFT_dynamicBrakeLightStatus 2 "DYNAMIC_BRAKE_LIGHT_ACTIVE_HIGH" 1 "DYNAMIC_BRAKE_LIGHT_ACTIVE_LOW" 0 "DYNAMIC_BRAKE_LIGHT_OFF" ;
VAL_ 994 VCLEFT_fogTrailerLightStatus 2 "LIGHT_FAULT" 0 "LIGHT_OFF" 1 "LIGHT_ON" 3 "LIGHT_SNA" ;
VAL_ 994 VCLEFT_frontRideHeight -128 "SNA" ;
VAL_ 994 VCLEFT_leftTurnTrailerLightStatu 2 "LIGHT_FAULT" 0 "LIGHT_OFF" 1 "LIGHT_ON" 3 "LIGHT_SNA" ;
VAL_ 994 VCLEFT_rearRideHeight -128 "SNA" ;
VAL_ 994 VCLEFT_reverseTrailerLightStatus 2 "LIGHT_FAULT" 0 "LIGHT_OFF" 1 "LIGHT_ON" 3 "LIGHT_SNA" ;
VAL_ 994 VCLEFT_rightTrnTrailerLightStatu 2 "LIGHT_FAULT" 0 "LIGHT_OFF" 1 "LIGHT_ON" 3 "LIGHT_SNA" ;
VAL_ 994 VCLEFT_tailLightStatus 2 "LIGHT_FAULT" 0 "LIGHT_OFF" 1 "LIGHT_ON" 3 "LIGHT_SNA" ;
VAL_ 994 VCLEFT_tailTrailerLightStatus 2 "LIGHT_FAULT" 0 "LIGHT_OFF" 1 "LIGHT_ON" 3 "LIGHT_SNA" ;
VAL_ 994 VCLEFT_trailerDetected 2 "TRAILER_LIGHT_DETECTION_DETECTED" 1 "TRAILER_LIGHT_DETECTION_FAULT" 3 "TRAILER_LIGHT_DETECTION_NOT_DETECTED" 0 "TRAILER_LIGHT_DETECTION_SNA" ;
VAL_ 994 VCLEFT_turnSignalStatus 2 "LIGHT_FAULT" 0 "LIGHT_OFF" 1 "LIGHT_ON" 3 "LIGHT_SNA" ;
VAL_ 1001 DAS_hazardLightRequest 0 "DAS_REQUEST_HAZARDS_OFF" 1 "DAS_REQUEST_HAZARDS_ON" 3 "DAS_REQUEST_HAZARDS_SNA" 2 "DAS_REQUEST_HAZARDS_UNUSED" ;
VAL_ 1001 DAS_headlightRequest 3 "DAS_HEADLIGHT_REQUEST_INVALID" 0 "DAS_HEADLIGHT_REQUEST_OFF" 1 "DAS_HEADLIGHT_REQUEST_ON" ;
VAL_ 1001 DAS_heaterRequest 1 "DAS_HEATER_OFF" 2 "DAS_HEATER_ON" 0 "DAS_HEATER_SNA" ;
VAL_ 1001 DAS_highLowBeamDecision 1 "DAS_HIGH_BEAM_OFF" 2 "DAS_HIGH_BEAM_ON" 3 "DAS_HIGH_BEAM_SNA" 0 "DAS_HIGH_BEAM_UNDECIDED" ;
VAL_ 1001 DAS_highLowBeamOffReason 3 "HIGH_BEAM_OFF_REASON_AMBIENT_LIGHT" 4 "HIGH_BEAM_OFF_REASON_HEAD_LIGHT" 2 "HIGH_BEAM_OFF_REASON_MOVING_RADAR_TARGET" 1 "HIGH_BEAM_OFF_REASON_MOVING_VISION_TARGET" 5 "HIGH_BEAM_OFF_REASON_SNA" 0 "HIGH_BEAM_ON" ;
VAL_ 1001 DAS_turnIndicatorRequest 3 "DAS_TURN_INDICATOR_CANCEL" 4 "DAS_TURN_INDICATOR_DEFER" 1 "DAS_TURN_INDICATOR_LEFT" 0 "DAS_TURN_INDICATOR_NONE" 2 "DAS_TURN_INDICATOR_RIGHT" ;
VAL_ 1001 DAS_turnIndicatorRequestReason 8 "DAS_ACTIVE_COMMANDED_LANE_CHANGE" 3 "DAS_ACTIVE_FORK" 9 "DAS_ACTIVE_INTERSECTION" 6 "DAS_ACTIVE_MERGE" 1 "DAS_ACTIVE_NAV_LANE_CHANGE" 2 "DAS_ACTIVE_SPEED_LANE_CHANGE" 11 "DAS_ACTIVE_SUMMMON" 5 "DAS_CANCEL_FORK" 10 "DAS_CANCEL_INTERSECTION" 4 "DAS_CANCEL_LANE_CHANGE" 7 "DAS_CANCEL_MERGE" 12 "DAS_CANCEL_SUMMMON" 0 "DAS_NONE" ;
VAL_ 1001 DAS_wiperSpeed 1 "DAS_WIPER_SPEED_1" 10 "DAS_WIPER_SPEED_10" 11 "DAS_WIPER_SPEED_11" 12 "DAS_WIPER_SPEED_12" 13 "DAS_WIPER_SPEED_13" 14 "DAS_WIPER_SPEED_14" 2 "DAS_WIPER_SPEED_2" 3 "DAS_WIPER_SPEED_3" 4 "DAS_WIPER_SPEED_4" 5 "DAS_WIPER_SPEED_5" 6 "DAS_WIPER_SPEED_6" 7 "DAS_WIPER_SPEED_7" 8 "DAS_WIPER_SPEED_8" 9 "DAS_WIPER_SPEED_9" 15 "DAS_WIPER_SPEED_INVALID" 0 "DAS_WIPER_SPEED_OFF" ;
VAL_ 1011 UI_odometer 16777215 "SNA" ;
VAL_ 1013 VCFRONT_DRLLeftStatus 2 "LIGHT_FAULT" 0 "LIGHT_OFF" 1 "LIGHT_ON" 3 "LIGHT_SNA" ;
VAL_ 1013 VCFRONT_DRLRightStatus 2 "LIGHT_FAULT" 0 "LIGHT_OFF" 1 "LIGHT_ON" 3 "LIGHT_SNA" ;
VAL_ 1013 VCFRONT_ambientLightingBrightnes 255 "SNA" ;
VAL_ 1013 VCFRONT_fogLeftStatus 2 "LIGHT_FAULT" 0 "LIGHT_OFF" 1 "LIGHT_ON" 3 "LIGHT_SNA" ;
VAL_ 1013 VCFRONT_fogRightStatus 2 "LIGHT_FAULT" 0 "LIGHT_OFF" 1 "LIGHT_ON" 3 "LIGHT_SNA" ;
VAL_ 1013 VCFRONT_hazardLightRequest 1 "HAZARD_REQUEST_BUTTON" 6 "HAZARD_REQUEST_CAR_ALARM" 5 "HAZARD_REQUEST_CRASH" 7 "HAZARD_REQUEST_DAS" 2 "HAZARD_REQUEST_LOCK" 4 "HAZARD_REQUEST_MISLOCK" 0 "HAZARD_REQUEST_NONE" 8 "HAZARD_REQUEST_UDS" 3 "HAZARD_REQUEST_UNLOCK" ;
VAL_ 1013 VCFRONT_highBeamLeftStatus 2 "LIGHT_FAULT" 0 "LIGHT_OFF" 1 "LIGHT_ON" 3 "LIGHT_SNA" ;
VAL_ 1013 VCFRONT_highBeamRightStatus 2 "LIGHT_FAULT" 0 "LIGHT_OFF" 1 "LIGHT_ON" 3 "LIGHT_SNA" ;
VAL_ 1013 VCFRONT_indicatorLeftRequest 2 "TURN_SIGNAL_ACTIVE_HIGH" 1 "TURN_SIGNAL_ACTIVE_LOW" 0 "TURN_SIGNAL_OFF" ;
VAL_ 1013 VCFRONT_indicatorRightRequest 2 "TURN_SIGNAL_ACTIVE_HIGH" 1 "TURN_SIGNAL_ACTIVE_LOW" 0 "TURN_SIGNAL_OFF" ;
VAL_ 1013 VCFRONT_lowBeamLeftStatus 2 "LIGHT_FAULT" 0 "LIGHT_OFF" 1 "LIGHT_ON" 3 "LIGHT_SNA" ;
VAL_ 1013 VCFRONT_lowBeamRightStatus 2 "LIGHT_FAULT" 0 "LIGHT_OFF" 1 "LIGHT_ON" 3 "LIGHT_SNA" ;
VAL_ 1013 VCFRONT_parkLeftStatus 2 "LIGHT_FAULT" 0 "LIGHT_OFF" 1 "LIGHT_ON" 3 "LIGHT_SNA" ;
VAL_ 1013 VCFRONT_parkRightStatus 2 "LIGHT_FAULT" 0 "LIGHT_OFF" 1 "LIGHT_ON" 3 "LIGHT_SNA" ;
VAL_ 1013 VCFRONT_sideMarkersStatus 2 "LIGHT_FAULT" 0 "LIGHT_OFF" 1 "LIGHT_ON" 3 "LIGHT_SNA" ;
VAL_ 1013 VCFRONT_sideRepeaterLeftStatus 2 "LIGHT_FAULT" 0 "LIGHT_OFF" 1 "LIGHT_ON" 3 "LIGHT_SNA" ;
VAL_ 1013 VCFRONT_sideRepeaterRightStatus 2 "LIGHT_FAULT" 0 "LIGHT_OFF" 1 "LIGHT_ON" 3 "LIGHT_SNA" ;
VAL_ 1013 VCFRONT_simLatchingStalk 0 "SIMULATED_LATCHING_STALK_IDLE" 1 "SIMULATED_LATCHING_STALK_LEFT" 2 "SIMULATED_LATCHING_STALK_RIGHT" 3 "SIMULATED_LATCHING_STALK_SNA" ;
VAL_ 1013 VCFRONT_switchLightingBrightness 255 "SNA" ;
VAL_ 1013 VCFRONT_turnSignalLeftStatus 2 "LIGHT_FAULT" 0 "LIGHT_OFF" 1 "LIGHT_ON" 3 "LIGHT_SNA" ;
VAL_ 1013 VCFRONT_turnSignalRightStatus 2 "LIGHT_FAULT" 0 "LIGHT_OFF" 1 "LIGHT_ON" 3 "LIGHT_SNA" ;
VAL_ 1016 UI_accFollowDistanceSetting 0 "DISTANCE_SETTING_1" 1 "DISTANCE_SETTING_2" 2 "DISTANCE_SETTING_3" 3 "DISTANCE_SETTING_4" 4 "DISTANCE_SETTING_5" 5 "DISTANCE_SETTING_6" 6 "DISTANCE_SETTING_7" 7 "DISTANCE_SETTING_SNA" ;
VAL_ 1016 UI_autopilotControlRequest 0 "LEGACY_LAT_CTRL" 1 "NEXT_GEN_CTRL" ;
VAL_ 1016 UI_curvSpeedAdaptDisable 1 "CSA_OFF" 0 "CSA_ON" ;
VAL_ 1016 UI_curvatureDatabaseOnly 0 "OFF" 1 "ON" ;
VAL_ 1016 UI_driveOnMapsEnable 0 "DOM_OFF" 1 "DOM_ON" ;
VAL_ 1016 UI_drivingSide 0 "DRIVING_SIDE_LEFT" 1 "DRIVING_SIDE_RIGHT" 2 "DRIVING_SIDE_UNKNOWN" ;
VAL_ 1016 UI_exceptionListEnable 0 "EXCEPTION_LIST_OFF" 1 "EXCEPTION_LIST_ON" ;
VAL_ 1016 UI_followNavRouteEnable 0 "NAV_ROUTE_OFF" 1 "NAV_ROUTE_ON" ;
VAL_ 1016 UI_fuseHPPDisable 1 "FUSE_HPP_OFF" 0 "FUSE_HPP_ON" ;
VAL_ 1016 UI_fuseLanesDisable 1 "FUSE_LANES_OFF" 0 "FUSE_LANES_ON" ;
VAL_ 1016 UI_fuseVehiclesDisable 1 "FUSE_VEH_OFF" 0 "FUSE_VEH_ON" ;
VAL_ 1016 UI_handsOnRequirementDisable 1 "HANDS_ON_REQ_OFF" 0 "HANDS_ON_REQ_ON" ;
VAL_ 1016 UI_lssElkEnabled 0 "ELK_OFF" 1 "ELK_ON" ;
VAL_ 1016 UI_lssLdwEnabled 0 "LDW_OFF" 1 "LDW_ON" ;
VAL_ 1016 UI_lssLkaEnabled 0 "LKA_OFF" 1 "LKA_ON" ;
VAL_ 1016 UI_roadCheckDisable 1 "RC_OFF" 0 "RC_ON" ;
VAL_ 1016 UI_selfParkRequest 3 "ABORT" 9 "AUTO_SUMMON_CANCEL" 7 "AUTO_SUMMON_FORWARD" 10 "AUTO_SUMMON_PRIMED" 8 "AUTO_SUMMON_REVERSE" 0 "NONE" 5 "PAUSE" 4 "PRIME" 6 "RESUME" 1 "SELF_PARK_FORWARD" 2 "SELF_PARK_REVERSE" 11 "SMART_SUMMON" 12 "SMART_SUMMON_NO_OP" 15 "SNA" ;
VAL_ 1016 UI_smartSummonType 1 "FIND_ME" 0 "PIN_DROP" 2 "SMART_AUTOPARK" ;
VAL_ 1016 UI_source3D 2 "XYZ_PREDICTION" 0 "Z_FROM_MAP" 1 "Z_FROM_PATH_PREDICTION" ;
VAL_ 1016 UI_summonEntryType 3 "SNA" 0 "STRAIGHT" 2 "TURN_LEFT" 1 "TURN_RIGHT" ;
VAL_ 1016 UI_summonExitType 3 "SNA" 0 "STRAIGHT" 2 "TURN_LEFT" 1 "TURN_RIGHT" ;
VAL_ 1016 UI_summonReverseDist 63 "SNA" ;
VAL_ 1016 UI_ulcBlindSpotConfig 1 "AGGRESSIVE" 2 "MAD_MAX" 0 "STANDARD" ;
VAL_ 1016 UI_ulcSpeedConfig 2 "SPEED_BASED_ULC_AVERAGE" 0 "SPEED_BASED_ULC_DISABLED" 3 "SPEED_BASED_ULC_MAD_MAX" 1 "SPEED_BASED_ULC_MILD" ;
VAL_ 1016 UI_visionSpeedType 0 "VISION_SPEED_DISABLED" 1 "VISION_SPEED_ONE_SECOND" 3 "VISION_SPEED_OPTIMIZED" 2 "VISION_SPEED_TWO_SECOND" ;
VAL_ 1021 UI_autopilotControlIndex 0 "AUTOPILOT_CONTROL_0" 1 "AUTOPILOT_CONTROL_1" 2 "AUTOPILOT_CONTROL_2" 3 "AUTOPILOT_CONTROL_3" 4 "AUTOPILOT_CONTROL_4" 5 "AUTOPILOT_CONTROL_5" 6 "AUTOPILOT_CONTROL_6" 7 "AUTOPILOT_CONTROL_7" ;
VAL_ 1021 UI_apmv3Branch 5 "DEMO" 2 "DEV" 4 "EAP" 0 "LIVE" 1 "STAGE" 3 "STAGE2" ;
VAL_ 1021 UI_blindspotDistance 1 "BLINDSPOT_DISTANCE_0P5_M" 2 "BLINDSPOT_DISTANCE_1_M" 3 "BLINDSPOT_DISTANCE_2_M" 4 "BLINDSPOT_DISTANCE_4_M" 0 "BLINDSPOT_DISTANCE_DEFAULT" 5 "BLINDSPOT_DISTANCE_OFF" ;
VAL_ 1021 UI_blindspotMinSpeed 2 "BLINDSPOT_MIN_SPEED_10_KPH" 3 "BLINDSPOT_MIN_SPEED_15_KPH" 4 "BLINDSPOT_MIN_SPEED_20_KPH" 5 "BLINDSPOT_MIN_SPEED_25_KPH" 6 "BLINDSPOT_MIN_SPEED_30_KPH" 7 "BLINDSPOT_MIN_SPEED_35_KPH" 8 "BLINDSPOT_MIN_SPEED_40_KPH" 9 "BLINDSPOT_MIN_SPEED_45_KPH" 1 "BLINDSPOT_MIN_SPEED_5_KPH" 0 "BLINDSPOT_MIN_SPEED_DEFAULT" 10 "BLINDSPOT_MIN_SPEED_OFF" ;
VAL_ 1021 UI_blindspotTTC 1 "BLINDSPOT_TTC_0P5_S" 2 "BLINDSPOT_TTC_1_S" 3 "BLINDSPOT_TTC_2_S" 5 "BLINDSPOT_TTC_3_S" 4 "BLINDSPOT_TTC_4_S" 6 "BLINDSPOT_TTC_5_S" 0 "BLINDSPOT_TTC_DEFAULT" 7 "BLINDSPOT_TTC_OFF" ;
VAL_ 1021 UI_donAlcProgGoreAbortThres 1 "DON_ALC_PROGRESS_GORE_ABORT_THRESHOLD_0P00" 2 "DON_ALC_PROGRESS_GORE_ABORT_THRESHOLD_0P05" 3 "DON_ALC_PROGRESS_GORE_ABORT_THRESHOLD_0P10" 4 "DON_ALC_PROGRESS_GORE_ABORT_THRESHOLD_0P15" 5 "DON_ALC_PROGRESS_GORE_ABORT_THRESHOLD_0P20" 6 "DON_ALC_PROGRESS_GORE_ABORT_THRESHOLD_0P25" 7 "DON_ALC_PROGRESS_GORE_ABORT_THRESHOLD_0P30" 8 "DON_ALC_PROGRESS_GORE_ABORT_THRESHOLD_0P35" 9 "DON_ALC_PROGRESS_GORE_ABORT_THRESHOLD_0P40" 0 "DON_ALC_PROGRESS_GORE_ABORT_THRESHOLD_DEFAULT" ;
VAL_ 1021 UI_donDisableAutoWiperDuration 5 "DON_DISABLE_AUTO_WIPER_DURATION_120_S" 2 "DON_DISABLE_AUTO_WIPER_DURATION_15_S" 3 "DON_DISABLE_AUTO_WIPER_DURATION_30_S" 1 "DON_DISABLE_AUTO_WIPER_DURATION_5_S" 4 "DON_DISABLE_AUTO_WIPER_DURATION_60_S" 0 "DON_DISABLE_AUTO_WIPER_DURATION_DEFAULT" 6 "DON_DISABLE_AUTO_WIPER_DURATION_OFF" ;
VAL_ 1021 UI_donDisableCutin 0 "DON_DISABLE_CUTIN_OFF" 1 "DON_DISABLE_CUTIN_ON" ;
VAL_ 1021 UI_donDisableOnAutoWiperSpeed 1 "DAS_WIPER_SPEED_1" 10 "DAS_WIPER_SPEED_10" 11 "DAS_WIPER_SPEED_11" 12 "DAS_WIPER_SPEED_12" 13 "DAS_WIPER_SPEED_13" 14 "DAS_WIPER_SPEED_14" 2 "DAS_WIPER_SPEED_2" 3 "DAS_WIPER_SPEED_3" 4 "DAS_WIPER_SPEED_4" 5 "DAS_WIPER_SPEED_5" 6 "DAS_WIPER_SPEED_6" 7 "DAS_WIPER_SPEED_7" 8 "DAS_WIPER_SPEED_8" 9 "DAS_WIPER_SPEED_9" 15 "DAS_WIPER_SPEED_INVALID" 0 "DAS_WIPER_SPEED_OFF" ;
VAL_ 1021 UI_donMinGoreWidthForAbortMap 2 "DON_MIN_GORE_WIDTH_FOR_ABORT_0P5_M" 1 "DON_MIN_GORE_WIDTH_FOR_ABORT_0_M" 4 "DON_MIN_GORE_WIDTH_FOR_ABORT_1P5_M" 3 "DON_MIN_GORE_WIDTH_FOR_ABORT_1_M" 6 "DON_MIN_GORE_WIDTH_FOR_ABORT_2P5_M" 5 "DON_MIN_GORE_WIDTH_FOR_ABORT_2_M" 8 "DON_MIN_GORE_WIDTH_FOR_ABORT_3P5_M" 7 "DON_MIN_GORE_WIDTH_FOR_ABORT_3_M" 10 "DON_MIN_GORE_WIDTH_FOR_ABORT_4P5_M" 9 "DON_MIN_GORE_WIDTH_FOR_ABORT_4_M" 11 "DON_MIN_GORE_WIDTH_FOR_ABORT_5_M" 0 "DON_MIN_GORE_WIDTH_FOR_ABORT_DEFAULT" ;
VAL_ 1021 UI_donMinGoreWidthForAbortNotMap 2 "DON_MIN_GORE_WIDTH_FOR_ABORT_0P5_M" 1 "DON_MIN_GORE_WIDTH_FOR_ABORT_0_M" 4 "DON_MIN_GORE_WIDTH_FOR_ABORT_1P5_M" 3 "DON_MIN_GORE_WIDTH_FOR_ABORT_1_M" 6 "DON_MIN_GORE_WIDTH_FOR_ABORT_2P5_M" 5 "DON_MIN_GORE_WIDTH_FOR_ABORT_2_M" 8 "DON_MIN_GORE_WIDTH_FOR_ABORT_3P5_M" 7 "DON_MIN_GORE_WIDTH_FOR_ABORT_3_M" 10 "DON_MIN_GORE_WIDTH_FOR_ABORT_4P5_M" 9 "DON_MIN_GORE_WIDTH_FOR_ABORT_4_M" 11 "DON_MIN_GORE_WIDTH_FOR_ABORT_5_M" 0 "DON_MIN_GORE_WIDTH_FOR_ABORT_DEFAULT" ;
VAL_ 1021 UI_donStopEndOfRampBuffer 1 "DON_STOP_END_OF_RAMP_BUFFER_15_M" 2 "DON_STOP_END_OF_RAMP_BUFFER_30_M" 3 "DON_STOP_END_OF_RAMP_BUFFER_45_M" 0 "DON_STOP_END_OF_RAMP_BUFFER_DEFAULT" 4 "DON_STOP_END_OF_RAMP_BUFFER_OFF" ;
VAL_ 1021 UI_homelinkNearby 1 "HOMELINK_NEARBY" 0 "HOMELINK_NOT_NEARBY" ;
VAL_ 1021 UI_hovEnabled 0 "HOV_OFF" 1 "HOV_ON" ;
VAL_ 611 VCRIGHT_logging10HzIndex 4 "END" 1 "HVAC_ACTUATOR_POSITIONS" 2 "HVAC_ACTUATOR_STATE" 0 "HVAC_ACTUATOR_TARGETS" 3 "HVAC_EVAP_PULLDOWN" ;
VAL_ 611 VCRIGHT_EvapPulldownBias 255 "SNA" ;
VAL_ 611 VCRIGHT_hvacIntakeActuatorState 0 "HVACACTUATOR_STATE_BRAKING" 2 "HVACACTUATOR_STATE_COASTING" 1 "HVACACTUATOR_STATE_RUNNING" ;
VAL_ 611 VCRIGHT_hvacIntakeOperationMode 1 "HVACACTUATOR_OPERATION_MODE_CALIBRATION" 0 "HVACACTUATOR_OPERATION_MODE_NORMAL" ;
VAL_ 611 VCRIGHT_hvacLHBleedActuatorState 0 "HVACACTUATOR_STATE_BRAKING" 2 "HVACACTUATOR_STATE_COASTING" 1 "HVACACTUATOR_STATE_RUNNING" ;
VAL_ 611 VCRIGHT_hvacLHBleedOperationMode 1 "HVACACTUATOR_OPERATION_MODE_CALIBRATION" 0 "HVACACTUATOR_OPERATION_MODE_NORMAL" ;
VAL_ 611 VCRIGHT_hvacLHVaneActuatorState 0 "HVACACTUATOR_STATE_BRAKING" 2 "HVACACTUATOR_STATE_COASTING" 1 "HVACACTUATOR_STATE_RUNNING" ;
VAL_ 611 VCRIGHT_hvacLHVaneOperationMode 1 "HVACACTUATOR_OPERATION_MODE_CALIBRATION" 0 "HVACACTUATOR_OPERATION_MODE_NORMAL" ;
VAL_ 611 VCRIGHT_hvacLowerModeActState 0 "HVACACTUATOR_STATE_BRAKING" 2 "HVACACTUATOR_STATE_COASTING" 1 "HVACACTUATOR_STATE_RUNNING" ;
VAL_ 611 VCRIGHT_hvacLowerModeOpMode 1 "HVACACTUATOR_OPERATION_MODE_CALIBRATION" 0 "HVACACTUATOR_OPERATION_MODE_NORMAL" ;
VAL_ 611 VCRIGHT_hvacRHBleedActuatorState 0 "HVACACTUATOR_STATE_BRAKING" 2 "HVACACTUATOR_STATE_COASTING" 1 "HVACACTUATOR_STATE_RUNNING" ;
VAL_ 611 VCRIGHT_hvacRHBleedOperationMode 1 "HVACACTUATOR_OPERATION_MODE_CALIBRATION" 0 "HVACACTUATOR_OPERATION_MODE_NORMAL" ;
VAL_ 611 VCRIGHT_hvacRHVaneActuatorState 0 "HVACACTUATOR_STATE_BRAKING" 2 "HVACACTUATOR_STATE_COASTING" 1 "HVACACTUATOR_STATE_RUNNING" ;
VAL_ 611 VCRIGHT_hvacRHVaneOperationMode 1 "HVACACTUATOR_OPERATION_MODE_CALIBRATION" 0 "HVACACTUATOR_OPERATION_MODE_NORMAL" ;
VAL_ 611 VCRIGHT_hvacUpperModeActState 0 "HVACACTUATOR_STATE_BRAKING" 2 "HVACACTUATOR_STATE_COASTING" 1 "HVACACTUATOR_STATE_RUNNING" ;
VAL_ 611 VCRIGHT_hvacUpperModeOpMode 1 "HVACACTUATOR_OPERATION_MODE_CALIBRATION" 0 "HVACACTUATOR_OPERATION_MODE_NORMAL" ;
VAL_ 615 DI_massConfidence 1 "MASS_CONFIDED" 0 "MASS_NOT_CONFIDED" ;
VAL_ 615 DI_relativeTireTreadDepth -32 "SNA" ;
VAL_ 615 DI_tireFitment 3 "FITMENT_SNA" 0 "FITMENT_SQUARE" 1 "FITMENT_STAGGERED" ;
VAL_ 615 DI_trailerDetected 1 "TRAILER_DETECTED" 0 "TRAILER_NOT_DETECTED" ;
VAL_ 642 VCLEFT_blowerIndex 0 "HVAC_FEEDBACK_SIGNALS" 1 "HVAC_VARS" ;
VAL_ 642 VCLEFT_hvacBlowerCBCCtrlState 4 "COUNT" 0 "ERROR" 1 "IDLE" 2 "OFFLINE" 3 "ONLINE" ;
VAL_ 642 VCLEFT_hvacBlowerCBCEstState 14 "COUNT" 0 "ERROR" 1 "IDLE" 5 "IDRATED" 10 "INDUCTANCE_EST" 9 "LOCKROTOR" 12 "MOTOR_IDENTIFIED" 13 "ONLINE" 8 "RAMPDOWN" 4 "RAMPUP" 7 "RATEDFLUX" 6 "RATEDFLUX_OL" 11 "ROTOR_RESISTANCE" 2 "ROVERL" 3 "RS" ;
VAL_ 642 VCLEFT_hvacBlowerFETTemp 127 "SNA" ;
VAL_ 642 VCLEFT_hvacBlowerIPhase0 255 "SNA" ;
VAL_ 642 VCLEFT_hvacBlowerIPhase1 255 "SNA" ;
VAL_ 642 VCLEFT_hvacBlowerIPhase2 255 "SNA" ;
VAL_ 642 VCLEFT_hvacBlowerITerm 127 "SNA" ;
VAL_ 642 VCLEFT_hvacBlowerOutputDuty 127 "SNA" ;
VAL_ 642 VCLEFT_hvacBlowerRPMTarget 1023 "SNA" ;
VAL_ 642 VCLEFT_hvacBlowerRs 255 "SNA" ;
VAL_ 642 VCLEFT_hvacBlowerTorque 1023 "SNA" ;
VAL_ 642 VCLEFT_hvacBlower_IO_CBC_Status 0 "IDLE" 1 "RX" ;
VAL_ 755 UI_hvacReqACDisable 0 "AUTO" 1 "OFF" 2 "ON" ;
VAL_ 755 UI_hvacReqAirDistributionMode 0 "AUTO" 4 "MANUAL_DEFROST" 5 "MANUAL_DEFROST_FLOOR" 6 "MANUAL_DEFROST_PANEL" 7 "MANUAL_DEFROST_PANEL_FLOOR" 1 "MANUAL_FLOOR" 2 "MANUAL_PANEL" 3 "MANUAL_PANEL_FLOOR" ;
VAL_ 755 UI_hvacReqBlowerSegment 1 "1" 10 "10" 2 "2" 3 "3" 4 "4" 5 "5" 6 "6" 7 "7" 8 "8" 9 "9" 11 "AUTO" 0 "OFF" ;
VAL_ 755 UI_hvacReqKeepClimateOn 2 "KEEP_CLIMATE_ON_REQ_DOG" 0 "KEEP_CLIMATE_ON_REQ_OFF" 1 "KEEP_CLIMATE_ON_REQ_ON" 3 "KEEP_CLIMATE_ON_REQ_PARTY" ;
VAL_ 755 UI_hvacReqManualDefogState 1 "DEFOG" 2 "DEFROST" 0 "NONE" ;
VAL_ 755 UI_hvacReqRecirc 0 "AUTO" 2 "FRESH" 1 "RECIRC" ;
VAL_ 755 UI_hvacReqSecondRowState 0 "AUTO" 4 "HIGH" 2 "LOW" 3 "MED" 1 "OFF" ;
VAL_ 755 UI_hvacReqTempSetpointLeft 26 "HI" 0 "LO" ;
VAL_ 755 UI_hvacReqTempSetpointRight 26 "HI" 0 "LO" ;
VAL_ 755 UI_hvacReqUserPowerState 0 "OFF" 1 "ON" 4 "OVERHEAT_PROTECT" 3 "OVERHEAT_PROTECT_FANONLY" 2 "PRECONDITION" ;
VAL_ 787 UI_trackCmpOverclock 0 "TRACK_MODE_CMP_OVERCLOCK_OFF" 1 "TRACK_MODE_CMP_OVERCLOCK_ON" ;
VAL_ 787 UI_trackModeRequest 0 "TRACK_MODE_REQUEST_IDLE" 2 "TRACK_MODE_REQUEST_OFF" 1 "TRACK_MODE_REQUEST_ON" ;
VAL_ 787 UI_trackPostCooling 0 "TRACK_MODE_POST_COOLING_OFF" 1 "TRACK_MODE_POST_COOLING_ON" ;
VAL_ 821 DIR_infoIndex 13 "DI_INFO_APP_CRC" 17 "DI_INFO_APP_GITHASH" 15 "DI_INFO_BOOTLOADER_CRC" 18 "DI_INFO_BOOTLOADER_GITHASH" 14 "DI_INFO_BOOTLOADER_SVN" 10 "DI_INFO_BUILD_HWID_COMPONENTID" 0 "DI_INFO_DEPRECATED_0" 1 "DI_INFO_DEPRECATED_1" 2 "DI_INFO_DEPRECATED_2" 3 "DI_INFO_DEPRECATED_3" 4 "DI_INFO_DEPRECATED_4" 5 "DI_INFO_DEPRECATED_5" 6 "DI_INFO_DEPRECATED_6" 7 "DI_INFO_DEPRECATED_7" 8 "DI_INFO_DEPRECATED_8" 9 "DI_INFO_DEPRECATED_9" 255 "DI_INFO_END" 11 "DI_INFO_PCBAID_ASSYID_USAGEID" 16 "DI_INFO_SUBCOMPONENT" 23 "DI_INFO_SUBCOMPONENT2" 31 "DI_INFO_SUBCOMPONENT_GITHASH" 20 "DI_INFO_UDS_PROTOCOL_BOOTCRC" 19 "DI_INFO_VERSION_DEPRECATED" ;
VAL_ 821 DIR_FPGA_version 254 "FPGA_VERSION_LOCAL_BUILD" 255 "FPGA_VERSION_SNA" ;
VAL_ 821 DIR_buildType 2 "INFO_LOCAL_BUILD" 4 "INFO_MFG_BUILD" 1 "INFO_PLATFORM_BUILD" 3 "INFO_TRACEABLE_CI_BUILD" 0 "INFO_UNKNOWN_BUILD" ;
VAL_ 821 DIR_hardwareId 252 "CONFIGURABLE_HWID_PLACEHOLDER" ;
VAL_ 821 DIR_oilPumpBuildType 2 "INFO_LOCAL_BUILD" 4 "INFO_MFG_BUILD" 1 "INFO_PLATFORM_BUILD" 3 "INFO_TRACEABLE_CI_BUILD" 0 "INFO_UNKNOWN_BUILD" ;
VAL_ 899 VCRIGHT_estimatedThsSolarLoad 1023 "SNA" ;
VAL_ 899 VCRIGHT_estimatedVehicleSituatio 1 "VEHICLE_SITUATION_INDOOR" 2 "VEHICLE_SITUATION_OUTDOOR" 0 "VEHICLE_SITUATION_UNKNOWN" ;
VAL_ 899 VCRIGHT_thsHumidity 255 "SNA" ;
VAL_ 899 VCRIGHT_thsSolarLoadInfrared 1023 "SNA" ;
VAL_ 899 VCRIGHT_thsSolarLoadVisible 1023 "SNA" ;
VAL_ 899 VCRIGHT_thsTemperature -128 "SNA" ;
VAL_ 915 VCRIGHT_epbmDebugIndex 2 "EPBM_HVDISCONNECT" 0 "EPBM_STATES" 1 "EPBM_TRANSITIONS" ;
VAL_ 915 VCRIGHT_cdpEnumDummy 0 "EPB_EXTERNAL_APPLY_IDLE" 2 "EPB_EXTERNAL_APPLY_INVALID" 1 "EPB_EXTERNAL_APPLY_VALID" ;
VAL_ 915 VCRIGHT_epbFaultStatus 2 "EPB_STATUS_FAULT" 3 "EPB_STATUS_FAULT_IDLE" 0 "EPB_STATUS_NOMINAL" 1 "EPB_STATUS_RETRY" ;
VAL_ 915 VCRIGHT_epbSummonState 3 "EPB_SUMMON_ACTIVE" 2 "EPB_SUMMON_ARMED" 4 "EPB_SUMMON_COMPLETE" 5 "EPB_SUMMON_FAULT" 1 "EPB_SUMMON_IDLE" 0 "EPB_SUMMON_INIT" 6 "EPB_SUMMON_UNAVAILABLE" ;
VAL_ 915 VCRIGHT_epbUnitStatus 22 "EPB_STATUS_COUNT" 2 "EPB_STATUS_DYNAMIC" 9 "EPB_STATUS_DYNAMIC_APPLYING" 20 "EPB_STATUS_DYNAMIC_PARKING" 17 "EPB_STATUS_EXTERNAL_DYNAMIC" 19 "EPB_STATUS_EXTERNAL_PARKING" 21 "EPB_STATUS_FREE_ROLL_MODE" 1 "EPB_STATUS_OPEN" 3 "EPB_STATUS_PARK" 8 "EPB_STATUS_PARKING" 12 "EPB_STATUS_PARK_PENDING" 10 "EPB_STATUS_RELEASING" 18 "EPB_STATUS_RELEASING_FOR_EXTERNAL_PARK" 5 "EPB_STATUS_SERVICE" 11 "EPB_STATUS_SERVICE_RELEASING" 4 "EPB_STATUS_START" 14 "EPB_STATUS_SUMMON" 16 "EPB_STATUS_SUMMON_PARKING" 15 "EPB_STATUS_SUMMON_RELEASING" 0 "EPB_STATUS_UNKNOWN" 6 "EPB_STATUS_WINCHMODE" 13 "EPB_STATUS_WINCHMODE_PENDING" 7 "EPB_STATUS_WINCHMODE_RELEASING" ;
VAL_ 915 VCRIGHT_epbmCaliperState 4 "EPB_SAVED_CALIPERSTATE_OPEN" 3 "EPB_SAVED_CALIPERSTATE_PARK" 2 "EPB_SAVED_CALIPERSTATE_REAPPLY" 5 "EPB_SAVED_CALIPERSTATE_SERVICE" 1 "EPB_SAVED_CALIPERSTATE_UNKNOWN" 0 "EPB_SAVED_CALIPERSTATE_UNSAVED" 6 "EPB_SAVED_CALIPERSTATE_WINCHMODE" ;
VAL_ 915 VCRIGHT_epbmFaultStatus 2 "EPB_STATUS_FAULT" 3 "EPB_STATUS_FAULT_IDLE" 0 "EPB_STATUS_NOMINAL" 1 "EPB_STATUS_RETRY" ;
VAL_ 915 VCRIGHT_epbmSummonState 3 "EPB_SUMMON_ACTIVE" 2 "EPB_SUMMON_ARMED" 4 "EPB_SUMMON_COMPLETE" 5 "EPB_SUMMON_FAULT" 1 "EPB_SUMMON_IDLE" 0 "EPB_SUMMON_INIT" 6 "EPB_SUMMON_UNAVAILABLE" ;
VAL_ 915 VCRIGHT_epbmSystemStatus 3 "EPB_VEHICLE_STATUS_DYNAMIC" 6 "EPB_VEHICLE_STATUS_FAULT" 7 "EPB_VEHICLE_STATUS_FAULT_SECURE" 8 "EPB_VEHICLE_STATUS_MISMATCH" 2 "EPB_VEHICLE_STATUS_PARKED" 4 "EPB_VEHICLE_STATUS_PARKING" 1 "EPB_VEHICLE_STATUS_RELEASED" 5 "EPB_VEHICLE_STATUS_RELEASING" 0 "EPB_VEHICLE_STATUS_UNKNOWN" ;
VAL_ 915 VCRIGHT_summonFaultReason 7 "EPB_SUMMONFAULT_DAS_FAULT" 2 "EPB_SUMMONFAULT_DAS_MIA" 6 "EPB_SUMMONFAULT_DI_APC_FAULT" 5 "EPB_SUMMONFAULT_DI_FAULT" 1 "EPB_SUMMONFAULT_DI_MIA" 20 "EPB_SUMMONFAULT_DI_STATE_INVALID" 10 "EPB_SUMMONFAULT_EAC_NOT_ALLOWED" 4 "EPB_SUMMONFAULT_EPBM_MIA" 11 "EPB_SUMMONFAULT_EPBM_REQUEST" 22 "EPB_SUMMONFAULT_EPBREMOTE_MIA" 19 "EPB_SUMMONFAULT_EPB_FAULT" 8 "EPB_SUMMONFAULT_ESP_FAULT" 3 "EPB_SUMMONFAULT_ESP_MIA" 13 "EPB_SUMMONFAULT_EXTERNAL" 27 "EPB_SUMMONFAULT_INVALID_REMOTE_STATE" 24 "EPB_SUMMONFAULT_LOCAL_UNIT_FAULTED" 18 "EPB_SUMMONFAULT_MISMATCH" 0 "EPB_SUMMONFAULT_NONE" 17 "EPB_SUMMONFAULT_OOC" 14 "EPB_SUMMONFAULT_PARK_MIA" 21 "EPB_SUMMONFAULT_PASSIVE_REQUEST" 15 "EPB_SUMMONFAULT_PM_MIA" 16 "EPB_SUMMONFAULT_PM_REQUEST" 28 "EPB_SUMMONFAULT_REMOTE_DID_NOT_START" 23 "EPB_SUMMONFAULT_REMOTE_SUMMON_FAULTED" 25 "EPB_SUMMONFAULT_REMOTE_UNIT_FAULTED" 12 "EPB_SUMMONFAULT_SPEED" 26 "EPB_SUMMONFAULT_START_IN_UNAVAILABLE" 9 "EPB_SUMMONFAULT_VEH_CAN_FAULT" ;
VAL_ 947 UI_autopilotPowerStateRequest 0 "AUTOPILOT_NOMINAL" 1 "AUTOPILOT_SENTRY" 2 "AUTOPILOT_SUSPEND" ;
VAL_ 947 UI_lightSwitch 0 "LIGHT_SWITCH_AUTO" 3 "LIGHT_SWITCH_OFF" 1 "LIGHT_SWITCH_ON" 2 "LIGHT_SWITCH_PARKING" 4 "LIGHT_SWITCH_SNA" ;
VAL_ 947 UI_shorted12VCellTestMode 2 "SHORTED_CELL_TEST_MODE_ACTIVE" 0 "SHORTED_CELL_TEST_MODE_DISABLED" 1 "SHORTED_CELL_TEST_MODE_SHADOW" ;
VAL_ 947 UI_summonState 3 "ACTIVE" 1 "IDLE" 2 "PRE_PRIMED" 0 "SNA" ;
VAL_ 947 UI_windowRequest 3 "WINDOW_REQUEST_GOTO_CLOSED" 4 "WINDOW_REQUEST_GOTO_OPEN" 1 "WINDOW_REQUEST_GOTO_PERCENT" 2 "WINDOW_REQUEST_GOTO_VENT" 0 "WINDOW_REQUEST_IDLE" ;
VAL_ 963 VCRIGHT_frontBuckleSwitch 3 "SWITCH_FAULT" 1 "SWITCH_OFF" 2 "SWITCH_ON" 0 "SWITCH_SNA" ;
VAL_ 963 VCRIGHT_frontOccupancySwitch 3 "SWITCH_FAULT" 1 "SWITCH_OFF" 2 "SWITCH_ON" 0 "SWITCH_SNA" ;
VAL_ 963 VCRIGHT_frontSeatBackrestBack 3 "SWITCH_FAULT" 1 "SWITCH_OFF" 2 "SWITCH_ON" 0 "SWITCH_SNA" ;
VAL_ 963 VCRIGHT_frontSeatBackrestForward 3 "SWITCH_FAULT" 1 "SWITCH_OFF" 2 "SWITCH_ON" 0 "SWITCH_SNA" ;
VAL_ 963 VCRIGHT_frontSeatLiftDown 3 "SWITCH_FAULT" 1 "SWITCH_OFF" 2 "SWITCH_ON" 0 "SWITCH_SNA" ;
VAL_ 963 VCRIGHT_frontSeatLiftUp 3 "SWITCH_FAULT" 1 "SWITCH_OFF" 2 "SWITCH_ON" 0 "SWITCH_SNA" ;
VAL_ 963 VCRIGHT_frontSeatLumbarDown 3 "SWITCH_FAULT" 1 "SWITCH_OFF" 2 "SWITCH_ON" 0 "SWITCH_SNA" ;
VAL_ 963 VCRIGHT_frontSeatLumbarIn 3 "SWITCH_FAULT" 1 "SWITCH_OFF" 2 "SWITCH_ON" 0 "SWITCH_SNA" ;
VAL_ 963 VCRIGHT_frontSeatLumbarOut 3 "SWITCH_FAULT" 1 "SWITCH_OFF" 2 "SWITCH_ON" 0 "SWITCH_SNA" ;
VAL_ 963 VCRIGHT_frontSeatLumbarUp 3 "SWITCH_FAULT" 1 "SWITCH_OFF" 2 "SWITCH_ON" 0 "SWITCH_SNA" ;
VAL_ 963 VCRIGHT_frontSeatTiltDown 3 "SWITCH_FAULT" 1 "SWITCH_OFF" 2 "SWITCH_ON" 0 "SWITCH_SNA" ;
VAL_ 963 VCRIGHT_frontSeatTiltUp 3 "SWITCH_FAULT" 1 "SWITCH_OFF" 2 "SWITCH_ON" 0 "SWITCH_SNA" ;
VAL_ 963 VCRIGHT_frontSeatTrackBack 3 "SWITCH_FAULT" 1 "SWITCH_OFF" 2 "SWITCH_ON" 0 "SWITCH_SNA" ;
VAL_ 963 VCRIGHT_frontSeatTrackForward 3 "SWITCH_FAULT" 1 "SWITCH_OFF" 2 "SWITCH_ON" 0 "SWITCH_SNA" ;
VAL_ 963 VCRIGHT_rearCenterBuckleSwitch 3 "SWITCH_FAULT" 1 "SWITCH_OFF" 2 "SWITCH_ON" 0 "SWITCH_SNA" ;
VAL_ 963 VCRIGHT_rearRightBuckleSwitch 3 "SWITCH_FAULT" 1 "SWITCH_OFF" 2 "SWITCH_ON" 0 "SWITCH_SNA" ;
VAL_ 995 VCRIGHT_brakeLightStatus 2 "LIGHT_FAULT" 0 "LIGHT_OFF" 1 "LIGHT_ON" 3 "LIGHT_SNA" ;
VAL_ 995 VCRIGHT_interiorTrunkLightStatus 2 "LIGHT_FAULT" 0 "LIGHT_OFF" 1 "LIGHT_ON" 3 "LIGHT_SNA" ;
VAL_ 995 VCRIGHT_rearFogLightStatus 2 "LIGHT_FAULT" 0 "LIGHT_OFF" 1 "LIGHT_ON" 3 "LIGHT_SNA" ;
VAL_ 995 VCRIGHT_reverseLightStatus 2 "LIGHT_FAULT" 0 "LIGHT_OFF" 1 "LIGHT_ON" 3 "LIGHT_SNA" ;
VAL_ 995 VCRIGHT_tailLightStatus 2 "LIGHT_FAULT" 0 "LIGHT_OFF" 1 "LIGHT_ON" 3 "LIGHT_SNA" ;
VAL_ 995 VCRIGHT_turnSignalStatus 2 "LIGHT_FAULT" 0 "LIGHT_OFF" 1 "LIGHT_ON" 3 "LIGHT_SNA" ;
VAL_ 1622 DIF_infoIndex 13 "DI_INFO_APP_CRC" 17 "DI_INFO_APP_GITHASH" 15 "DI_INFO_BOOTLOADER_CRC" 18 "DI_INFO_BOOTLOADER_GITHASH" 14 "DI_INFO_BOOTLOADER_SVN" 10 "DI_INFO_BUILD_HWID_COMPONENTID" 0 "DI_INFO_DEPRECATED_0" 1 "DI_INFO_DEPRECATED_1" 2 "DI_INFO_DEPRECATED_2" 3 "DI_INFO_DEPRECATED_3" 4 "DI_INFO_DEPRECATED_4" 5 "DI_INFO_DEPRECATED_5" 6 "DI_INFO_DEPRECATED_6" 7 "DI_INFO_DEPRECATED_7" 8 "DI_INFO_DEPRECATED_8" 9 "DI_INFO_DEPRECATED_9" 255 "DI_INFO_END" 11 "DI_INFO_PCBAID_ASSYID_USAGEID" 16 "DI_INFO_SUBCOMPONENT" 23 "DI_INFO_SUBCOMPONENT2" 31 "DI_INFO_SUBCOMPONENT_GITHASH" 20 "DI_INFO_UDS_PROTOCOL_BOOTCRC" 19 "DI_INFO_VERSION_DEPRECATED" ;
VAL_ 1622 DIF_FPGA_version 254 "FPGA_VERSION_LOCAL_BUILD" 255 "FPGA_VERSION_SNA" ;
VAL_ 1622 DIF_buildType 2 "INFO_LOCAL_BUILD" 4 "INFO_MFG_BUILD" 1 "INFO_PLATFORM_BUILD" 3 "INFO_TRACEABLE_CI_BUILD" 0 "INFO_UNKNOWN_BUILD" ;
VAL_ 1622 DIF_hardwareId 252 "CONFIGURABLE_HWID_PLACEHOLDER" ;
VAL_ 1622 DIF_oilPumpBuildType 2 "INFO_LOCAL_BUILD" 4 "INFO_MFG_BUILD" 1 "INFO_PLATFORM_BUILD" 3 "INFO_TRACEABLE_CI_BUILD" 0 "INFO_UNKNOWN_BUILD" ;
VAL_ 768 BMS_infoIndex 13 "INFO_APP_CRC" 17 "INFO_APP_GITHASH" 15 "INFO_BOOTLOADER_CRC" 18 "INFO_BOOTLOADER_GITHASH" 14 "INFO_BOOTLOADER_SVN" 10 "INFO_BUILD_HWID_COMPONENTID" 0 "INFO_DEPRECATED_0" 1 "INFO_DEPRECATED_1" 2 "INFO_DEPRECATED_2" 3 "INFO_DEPRECATED_3" 4 "INFO_DEPRECATED_4" 5 "INFO_DEPRECATED_5" 6 "INFO_DEPRECATED_6" 7 "INFO_DEPRECATED_7" 8 "INFO_DEPRECATED_8" 9 "INFO_DEPRECATED_9" 255 "INFO_END" 27 "INFO_PACKAGE_PN_15_20" 25 "INFO_PACKAGE_PN_1_7" 26 "INFO_PACKAGE_PN_8_14" 29 "INFO_PACKAGE_SN_1_7" 30 "INFO_PACKAGE_SN_8_14" 11 "INFO_PCBAID_ASSYID_USAGEID" 16 "INFO_SUBCOMPONENT" 31 "INFO_SUBCOMPONENT_GITHASH" 20 "INFO_UDS_PROTOCOL_BOOTCRC" 22 "INFO_VARIANTCRC" 19 "INFO_VERSION_DEPRECATED" ;
VAL_ 768 BMS_buildType 2 "INFO_LOCAL_BUILD" 4 "INFO_MFG_BUILD" 1 "INFO_PLATFORM_BUILD" 3 "INFO_TRACEABLE_CI_BUILD" 0 "INFO_UNKNOWN_BUILD" ;
VAL_ 530 BMS_chgPowerAvailable 2047 "SNA" ;
VAL_ 530 BMS_contactorState 6 "BMS_CTRSET_BLOCKED" 4 "BMS_CTRSET_CLOSED" 3 "BMS_CTRSET_CLOSING" 1 "BMS_CTRSET_OPEN" 2 "BMS_CTRSET_OPENING" 0 "BMS_CTRSET_SNA" 5 "BMS_CTRSET_WELDED" ;
VAL_ 530 BMS_diLimpRequest 0 "LIMP_REQUEST_NONE" 1 "LIMP_REQUEST_WELDED" ;
VAL_ 530 BMS_ecuLogUploadRequest 1 "REQUEST_PRIORITY_1" 2 "REQUEST_PRIORITY_2" 3 "REQUEST_PRIORITY_3" 0 "REQUEST_PRIORITY_NONE" ;
VAL_ 530 BMS_hvState 1 "HV_COMING_UP" 0 "HV_DOWN" 2 "HV_GOING_DOWN" 6 "HV_UP" 4 "HV_UP_FOR_CHARGE" 5 "HV_UP_FOR_DC_CHARGE" 3 "HV_UP_FOR_DRIVE" ;
VAL_ 530 BMS_isolationResistance 1023 "SNA" ;
VAL_ 530 BMS_smStateRequest 3 "BMS_CHARGE" 5 "BMS_CLEAR_FAULT" 10 "BMS_DIAG" 1 "BMS_DRIVE" 6 "BMS_FAULT" 4 "BMS_FEIM" 9 "BMS_SNA" 0 "BMS_STANDBY" 2 "BMS_SUPPORT" 8 "BMS_TEST" 7 "BMS_WELD" ;
VAL_ 530 BMS_state 3 "BMS_CHARGE" 5 "BMS_CLEAR_FAULT" 10 "BMS_DIAG" 1 "BMS_DRIVE" 6 "BMS_FAULT" 4 "BMS_FEIM" 9 "BMS_SNA" 0 "BMS_STANDBY" 2 "BMS_SUPPORT" 8 "BMS_TEST" 7 "BMS_WELD" ;
VAL_ 530 BMS_uiChargeStatus 2 "BMS_ABOUT_TO_CHARGE" 4 "BMS_CHARGE_COMPLETE" 5 "BMS_CHARGE_STOPPED" 3 "BMS_CHARGING" 0 "BMS_DISCONNECTED" 1 "BMS_NO_POWER" ;
VAL_ 946 BMS_log2MuxId 9 "BMS_LOG2_100HZ_1KHZ_TASK_STATS" 8 "BMS_LOG2_10HZ_TASK_STATS" 7 "BMS_LOG2_1HZ_TASK_STATS" 6 "BMS_LOG2_AHR_COUNTER" 24 "BMS_LOG2_BRICK_VOLTAGE_CHANGE" 0 "BMS_LOG2_CAC1" 1 "BMS_LOG2_CAC2" 23 "BMS_LOG2_CAC3" 3 "BMS_LOG2_CHARGE_TERMINATION" 5 "BMS_LOG2_CHARGING" 10 "BMS_LOG2_CTR_RESISTANCE" 22 "BMS_LOG2_ENERGY_AND_REST_DATA" 20 "BMS_LOG2_ENERGY_RESERVE" 21 "BMS_LOG2_FC_LINK_LEAKAGE_TEST" 2 "BMS_LOG2_FLOOD_PORT" 19 "BMS_LOG2_HV_CHAIN_MODEL" 15 "BMS_LOG2_NEG_CTR_HEALTH_1" 16 "BMS_LOG2_NEG_CTR_HEALTH_2" 17 "BMS_LOG2_NEG_CTR_HEALTH_3" 18 "BMS_LOG2_NEG_CTR_HEALTH_4" 11 "BMS_LOG2_POS_CTR_HEALTH_1" 12 "BMS_LOG2_POS_CTR_HEALTH_2" 13 "BMS_LOG2_POS_CTR_HEALTH_3" 14 "BMS_LOG2_POS_CTR_HEALTH_4" 25 "BMS_LOG2_SOC_BY_OCV_CORRECTION" 4 "BMS_LOG2_VSH_TEST" ;
VAL_ 946 BMS_chargeCurrentLimitMode 1 "BMS_CHG_I_LIMIT_BRICK_TEMP_AND_V" 2 "BMS_CHG_I_LIMIT_CAC_IMBALANCE" 5 "BMS_CHG_I_LIMIT_CONFIG" 6 "BMS_CHG_I_LIMIT_HV_CHAIN" 3 "BMS_CHG_I_LIMIT_LEAKY_BUCKET" 0 "BMS_CHG_I_LIMIT_NONE" 4 "BMS_CHG_I_LIMIT_TETHERING" ;
VAL_ 946 BMS_chargeNeededReason 6 "BMS_BRICKV_LESS_THAN_FULL_CHARGE" 4 "BMS_CABLE_CYCLE_TOP_OFF" 3 "BMS_CHARGE_TARGET_INCREASED" 2 "BMS_DCH_KWH_THRESHOLD" 0 "BMS_NO_CHARGE_REASON" 1 "BMS_SOC_LESS_THAN_UI_THRESHOLD" ;
VAL_ 946 BMS_chgEndBmsHvChargeStatus 4 "BMS_CHARGE_ENABLED" 3 "BMS_CHARGE_ENABLING" 7 "BMS_CHARGE_FAULTED" 0 "BMS_CHARGE_STANDBY" 6 "BMS_EMERGENCY_SHUTDOWN" 1 "BMS_EXT_EVSE_TEST_ALLOWED" 2 "BMS_EXT_PRECHARGE_ALLOWED" 5 "BMS_GRACEFUL_SHUTDOWN" ;
VAL_ 946 BMS_chgEndChargeState 7 "CHARGE_STATE_AC_DISABLE_PCS" 4 "CHARGE_STATE_AC_ENABLE_PCS" 5 "CHARGE_STATE_CHARGING_ACTIVE" 6 "CHARGE_STATE_DC_DISABLING_CHARGER" 3 "CHARGE_STATE_DC_ENABLE_FCLINK" 2 "CHARGE_STATE_DC_EXT_ISO_CHECK" 1 "CHARGE_STATE_ENABLE_DCLINK" 0 "CHARGE_STATE_INACTIVE" ;
VAL_ 946 BMS_chgEndCpHvChargeStatus 1 "CP_CHARGE_CONNECTED" 5 "CP_CHARGE_ENABLED" 6 "CP_CHARGE_FAULTED" 0 "CP_CHARGE_INACTIVE" 2 "CP_CHARGE_STANDBY" 4 "CP_EVSE_TEST_PASSED" 3 "CP_EXT_EVSE_TEST_ACTIVE" ;
VAL_ 946 BMS_chgEndCpShutdownRequest 2 "EMERGENCY_SHUTDOWN_REQUESTED" 1 "GRACEFUL_SHUTDOWN_REQUESTED" 0 "NO_SHUTDOWN_REQUESTED" ;
VAL_ 946 BMS_chgEndEvseChargeType 2 "AC_CHARGER_PRESENT" 1 "DC_CHARGER_PRESENT" 0 "NO_CHARGER_PRESENT" ;
VAL_ 946 BMS_chgEndPcsHvChargeStatus 1 "PCS_CHARGE_BLOCKED" 2 "PCS_CHARGE_ENABLED" 3 "PCS_CHARGE_FAULTED" 0 "PCS_CHARGE_STANDBY" ;
VAL_ 946 BMS_chgEndPcsShutdownRequest 2 "EMERGENCY_SHUTDOWN_REQUESTED" 1 "GRACEFUL_SHUTDOWN_REQUESTED" 0 "NO_SHUTDOWN_REQUESTED" ;
VAL_ 946 BMS_cpChargeStatus 1 "BMS_CHARGING_ACTIVE" 2 "BMS_CHARGING_COMPLETE" 4 "BMS_CHARGING_ENABLING" 3 "BMS_CHARGING_FAULT" 0 "BMS_CHARGING_INACTIVE" 5 "BMS_CHARGING_UPDATE_IN_PROGRESS" ;
VAL_ 946 BMS_dynamicEnergyBuffer 1023 "SNA" ;
VAL_ 946 BMS_fcLinkTestDecayTime 1023 "SNA" ;
VAL_ 946 BMS_floodPortState1 2 "FLOOD_PORT_STATE_CLOSED" 4 "FLOOD_PORT_STATE_ERROR_HIGH" 1 "FLOOD_PORT_STATE_ERROR_LOW" 3 "FLOOD_PORT_STATE_OPEN" 0 "FLOOD_PORT_STATE_SNA" ;
VAL_ 946 BMS_floodPortState2 2 "FLOOD_PORT_STATE_CLOSED" 4 "FLOOD_PORT_STATE_ERROR_HIGH" 1 "FLOOD_PORT_STATE_ERROR_LOW" 3 "FLOOD_PORT_STATE_OPEN" 0 "FLOOD_PORT_STATE_SNA" ;
VAL_ 946 BMS_idealEnergyFloor 1023 "SNA" ;
VAL_ 946 BMS_negCtrCommonModeRejError -4096 "SNA" ;
VAL_ 946 BMS_negCtrCommonModeRejErrorConf 8191 "SNA" ;
VAL_ 946 BMS_negCtrDeviationConfidenceMax 8191 "SNA" ;
VAL_ 946 BMS_negCtrDeviationConfidenceMin 8191 "SNA" ;
VAL_ 946 BMS_negCtrDeviationFiltConfMax 8191 "SNA" ;
VAL_ 946 BMS_negCtrDeviationFiltConfMin 8191 "SNA" ;
VAL_ 946 BMS_negCtrDeviationFiltMax -4096 "SNA" ;
VAL_ 946 BMS_negCtrDeviationFiltMin -4096 "SNA" ;
VAL_ 946 BMS_negCtrDeviationMax -4096 "SNA" ;
VAL_ 946 BMS_negCtrDeviationMin -4096 "SNA" ;
VAL_ 946 BMS_negCtrDropCorrectedFiltMax -4096 "SNA" ;
VAL_ 946 BMS_negCtrDropCorrectedFiltMin -4096 "SNA" ;
VAL_ 946 BMS_negCtrDropCorrectedMax -4096 "SNA" ;
VAL_ 946 BMS_negCtrDropCorrectedMin -4096 "SNA" ;
VAL_ 946 BMS_negCtrOffsetError -4096 "SNA" ;
VAL_ 946 BMS_negCtrOffsetErrorConf 8191 "SNA" ;
VAL_ 946 BMS_negCtrResistance -4096 "SNA" ;
VAL_ 946 BMS_negCtrResistanceConfidence 8191 "SNA" ;
VAL_ 946 BMS_posCtrCommonModeRejError -4096 "SNA" ;
VAL_ 946 BMS_posCtrCommonModeRejErrorConf 8191 "SNA" ;
VAL_ 946 BMS_posCtrDeviationConfidenceMax 8191 "SNA" ;
VAL_ 946 BMS_posCtrDeviationConfidenceMin 8191 "SNA" ;
VAL_ 946 BMS_posCtrDeviationFiltConfMax 8191 "SNA" ;
VAL_ 946 BMS_posCtrDeviationFiltConfMin 8191 "SNA" ;
VAL_ 946 BMS_posCtrDeviationFiltMax -4096 "SNA" ;
VAL_ 946 BMS_posCtrDeviationFiltMin -4096 "SNA" ;
VAL_ 946 BMS_posCtrDeviationMax -4096 "SNA" ;
VAL_ 946 BMS_posCtrDeviationMin -4096 "SNA" ;
VAL_ 946 BMS_posCtrDropCorrectedFiltMax -4096 "SNA" ;
VAL_ 946 BMS_posCtrDropCorrectedFiltMin -4096 "SNA" ;
VAL_ 946 BMS_posCtrDropCorrectedMax -4096 "SNA" ;
VAL_ 946 BMS_posCtrDropCorrectedMin -4096 "SNA" ;
VAL_ 946 BMS_posCtrOffsetError -4096 "SNA" ;
VAL_ 946 BMS_posCtrOffsetErrorConf 8191 "SNA" ;
VAL_ 946 BMS_posCtrResistance -4096 "SNA" ;
VAL_ 946 BMS_posCtrResistanceConfidence 8191 "SNA" ;
VAL_ 800 BMS_matrixIndex 0 "BMS_AlertMatrix0" 1 "BMS_AlertMatrix1" 2 "BMS_AlertMatrix2" ;
VAL_ 796 CC_currentLimit 255 "SNA" ;
VAL_ 796 CC_gridGrounding 1 "CC_GRID_GROUNDING_IT_SplitPhase" 2 "CC_GRID_GROUNDING_SNA" 0 "CC_GRID_GROUNDING_TN_TT" ;
VAL_ 796 CC_line1Voltage 511 "SNA" ;
VAL_ 796 CC_line2Voltage 511 "SNA" ;
VAL_ 796 CC_line3Voltage 511 "SNA" ;
VAL_ 796 CC_numPhases 0 "SNA" ;
VAL_ 796 CC_pilotState 2 "CC_PILOT_STATE_FAULTED" 1 "CC_PILOT_STATE_IDLE" 0 "CC_PILOT_STATE_READY" 3 "CC_PILOT_STATE_SNA" ;
VAL_ 797 CC_chgStatus2Index 0 "Mux0" ;
VAL_ 797 CC_buttonState 1 "CC_BUTTON_PRESSED" 0 "CC_BUTTON_RELEASED" ;
VAL_ 812 CC_logIndex 0 "Mux0" 1 "Mux1" 10 "Mux10" 11 "Mux11" 12 "Mux12" 13 "Mux13" 2 "Mux2" 3 "Mux3" 4 "Mux4" ;
VAL_ 812 CC_activeConnectorID 255 "SNA" ;
VAL_ 812 CC_conn1Current 255 "SNA" ;
VAL_ 812 CC_conn2Current 255 "SNA" ;
VAL_ 812 CC_conn3Current 255 "SNA" ;
VAL_ 812 CC_conn4Current 255 "SNA" ;
VAL_ 812 CC_contactor1Closed 1 "CC_CONTACTOR_CLOSED" 0 "CC_CONTACTOR_OPEN" 3 "CC_CONTACTOR_SNA" ;
VAL_ 812 CC_contactor2Closed 1 "CC_CONTACTOR_CLOSED" 0 "CC_CONTACTOR_OPEN" 3 "CC_CONTACTOR_SNA" ;
VAL_ 812 CC_temperature1 127 "SNA" ;
VAL_ 812 CC_temperature2 127 "SNA" ;
VAL_ 812 CC_temperature3 127 "SNA" ;
VAL_ 812 CC_temperature4 127 "SNA" ;
VAL_ 573 CP_chargeShutdownRequest 2 "EMERGENCY_SHUTDOWN_REQUESTED" 1 "GRACEFUL_SHUTDOWN_REQUESTED" 0 "NO_SHUTDOWN_REQUESTED" ;
VAL_ 573 CP_hvChargeStatus 1 "CP_CHARGE_CONNECTED" 5 "CP_CHARGE_ENABLED" 6 "CP_CHARGE_FAULTED" 0 "CP_CHARGE_INACTIVE" 2 "CP_CHARGE_STANDBY" 4 "CP_EVSE_TEST_PASSED" 3 "CP_EXT_EVSE_TEST_ACTIVE" ;
VAL_ 317 CP_chargeShutdownRequest 2 "EMERGENCY_SHUTDOWN_REQUESTED" 1 "GRACEFUL_SHUTDOWN_REQUESTED" 0 "NO_SHUTDOWN_REQUESTED" ;
VAL_ 317 CP_evseChargeType 2 "AC_CHARGER_PRESENT" 1 "DC_CHARGER_PRESENT" 0 "NO_CHARGER_PRESENT" ;
VAL_ 317 CP_hvChargeStatus 1 "CP_CHARGE_CONNECTED" 5 "CP_CHARGE_ENABLED" 6 "CP_CHARGE_FAULTED" 0 "CP_CHARGE_INACTIVE" 2 "CP_CHARGE_STANDBY" 4 "CP_EVSE_TEST_PASSED" 3 "CP_EXT_EVSE_TEST_ACTIVE" ;
VAL_ 1085 CP_chargeShutdownRequest_log 2 "EMERGENCY_SHUTDOWN_REQUESTED" 1 "GRACEFUL_SHUTDOWN_REQUESTED" 0 "NO_SHUTDOWN_REQUESTED" ;
VAL_ 1085 CP_evseChargeType_log 2 "AC_CHARGER_PRESENT" 1 "DC_CHARGER_PRESENT" 0 "NO_CHARGER_PRESENT" ;
VAL_ 1085 CP_hvChargeStatus_log 1 "CP_CHARGE_CONNECTED" 5 "CP_CHARGE_ENABLED" 6 "CP_CHARGE_FAULTED" 0 "CP_CHARGE_INACTIVE" 2 "CP_CHARGE_STANDBY" 4 "CP_EVSE_TEST_PASSED" 3 "CP_EXT_EVSE_TEST_ACTIVE" ;
VAL_ 541 CP_acChargeState 1 "AC_CHARGE_CONNECTED_CHARGE_BLOCKED" 3 "AC_CHARGE_ENABLED" 6 "AC_CHARGE_FAULT" 0 "AC_CHARGE_INACTIVE" 4 "AC_CHARGE_ONBOARD_CHARGER_SHUTDOWN" 2 "AC_CHARGE_STANDBY" 5 "AC_CHARGE_VEH_SHUTDOWN" ;
VAL_ 541 CP_cableType 2 "CHG_CABLE_TYPE_GB_AC" 3 "CHG_CABLE_TYPE_GB_DC" 0 "CHG_CABLE_TYPE_IEC" 1 "CHG_CABLE_TYPE_SAE" 4 "CHG_CABLE_TYPE_SNA" ;
VAL_ 541 CP_evseChargeType_UI 2 "AC_CHARGER_PRESENT" 1 "DC_CHARGER_PRESENT" 0 "NO_CHARGER_PRESENT" ;
VAL_ 541 CP_gbState 10 "GBDC_CHARGE_DISABLING" 5 "GBDC_CHARGE_PARAM_CONFIG" 8 "GBDC_CHARGING" 2 "GBDC_COMMS_RECEIVED" 11 "GBDC_END_OF_CHARGE" 12 "GBDC_ERROR_HANDLING" 14 "GBDC_FAULTED" 3 "GBDC_HANDSHAKING_EXT_ISO" 0 "GBDC_INACTIVE" 7 "GBDC_READY_TO_CHARGE" 4 "GBDC_RECOGNITION" 13 "GBDC_RETRY_CHARGE" 9 "GBDC_STOP_CHARGE_REQUESTED" 15 "GBDC_TESTER_PRESENT" 6 "GBDC_VEH_PACK_PRECHARGE" 1 "GBDC_WAIT_FOR_COMMS" ;
VAL_ 541 CP_gbdcFailureReason 1 "GBDC_ATTEMPTS_EXPIRED" 3 "GBDC_CRITICAL_FAILURE" 0 "GBDC_FAILURE_NONE" 2 "GBDC_SHUTDOWN_FAILURE" ;
VAL_ 541 CP_gbdcStopChargeReason 3 "GBDC_COMMS_TIMEOUT" 5 "GBDC_EVSE_CRITICAL_FAULT" 4 "GBDC_EVSE_FAULT" 2 "GBDC_EVSE_REQUESTED" 6 "GBDC_LIVE_DISCONNECT" 0 "GBDC_STOP_REASON_NONE" 7 "GBDC_SUPERCHARGER_COMMS_TIMEOUT" 1 "GBDC_VEH_REQUESTED" ;
VAL_ 541 CP_iecComboState 6 "IEC_COMBO_CABLE_CHECK" 5 "IEC_COMBO_CHARGE_PARAM_DISCOVERY" 1 "IEC_COMBO_CONNECTED" 8 "IEC_COMBO_ENABLED" 10 "IEC_COMBO_END_OF_CHARGE" 11 "IEC_COMBO_FAULT" 0 "IEC_COMBO_INACTIVE" 4 "IEC_COMBO_PAYMENT_SELECTION" 7 "IEC_COMBO_PRECHARGE" 3 "IEC_COMBO_SERVICE_DISCOVERY" 9 "IEC_COMBO_SHUTDOWN" 2 "IEC_COMBO_V2G_SESSION_SETUP" 12 "IEC_COMBO_WAIT_RESTART" ;
VAL_ 541 CP_pilot 3 "CHG_PILOT_FAST_CHARGE" 1 "CHG_PILOT_FAULTED" 4 "CHG_PILOT_IDLE" 5 "CHG_PILOT_INVALID" 2 "CHG_PILOT_LINE_CHARGE" 0 "CHG_PILOT_NONE" 7 "CHG_PILOT_SNA" 6 "CHG_PILOT_UNUSED_6" ;
VAL_ 541 CP_proximity 1 "CHG_PROXIMITY_DISCONNECTED" 3 "CHG_PROXIMITY_LATCHED" 0 "CHG_PROXIMITY_SNA" 2 "CHG_PROXIMITY_UNLATCHED" ;
VAL_ 541 CP_teslaDcState 1 "TESLA_DC_CONNECTED_CHARGE_BLOCKED" 9 "TESLA_DC_EMERGENCY_SHUTDOWN" 6 "TESLA_DC_ENABLED" 7 "TESLA_DC_EVSE_SHUTDOWN" 5 "TESLA_DC_EXT_PRECHARGE_ACTIVE" 3 "TESLA_DC_EXT_TESTS_ENABLED" 4 "TESLA_DC_EXT_TEST_ACTIVE" 10 "TESLA_DC_FAULT" 0 "TESLA_DC_INACTIVE" 2 "TESLA_DC_STANDBY" 8 "TESLA_DC_VEH_SHUTDOWN" ;
VAL_ 541 CP_teslaSwcanState 1 "TESLA_SWCAN_ACCEPT" 3 "TESLA_SWCAN_ESTABLISHED" 4 "TESLA_SWCAN_FAULT" 5 "TESLA_SWCAN_GO_TO_SLEEP" 0 "TESLA_SWCAN_INACTIVE" 6 "TESLA_SWCAN_OFFBOARD_UPDATE_IN_PROGRESS" 2 "TESLA_SWCAN_RECEIVE" ;
VAL_ 1859 VCRIGHT_mirrorRecallStatus 2 "RECALL_COMPLETE" 3 "RECALL_INTERRUPTED" 1 "RECALL_IN_PROGRESS" 0 "RECALL_SNA" ;
VAL_ 1859 VCRIGHT_seatRecallStatus 2 "RECALL_COMPLETE" 3 "RECALL_INTERRUPTED" 1 "RECALL_IN_PROGRESS" 0 "RECALL_SNA" ;
VAL_ 1859 VCRIGHT_systemRecallStatus 2 "RECALL_COMPLETE" 3 "RECALL_INTERRUPTED" 1 "RECALL_IN_PROGRESS" 0 "RECALL_SNA" ;
VAL_ 1885 CP_sensorDataSelect 2 "CP_SENSOR_DOOR" 0 "CP_SENSOR_DOOR_COUNTS" 4 "CP_SENSOR_INDUCTIVE_DOOR" 12 "CP_SENSOR_INLET_HARNESS_ID" 3 "CP_SENSOR_LATCH" 9 "CP_SENSOR_PILOT" 10 "CP_SENSOR_PILOT2" 1 "CP_SENSOR_PIN_TEMP" 8 "CP_SENSOR_PROX" 11 "CP_SENSOR_PROX_GB" 7 "CP_SENSOR_RAILS" 5 "CP_SENSOR_SAFETY" 6 "CP_SENSOR_UHF" ;
VAL_ 1885 CP_inlet1HarnessIdState 1 "HARNESS_PEDIGREE_INVALID" 0 "HARNESS_PEDIGREE_UNKNOWN_SNA" 2 "HARNESS_PEDIGREE_VALID" ;
VAL_ 1885 CP_inlet2HarnessIdState 1 "HARNESS_PEDIGREE_INVALID" 0 "HARNESS_PEDIGREE_UNKNOWN_SNA" 2 "HARNESS_PEDIGREE_VALID" ;
VAL_ 1962 HVP_debugMessageMultiplexer 0 "Mux0" 1 "Mux1" 2 "Mux2" 3 "Mux3" 4 "Mux4" 5 "Mux5" 6 "Mux6" ;
VAL_ 1962 HVP_shuntAsicTempDbg -32768 "SHUNT_TEMPERATURE_SNA" ;
VAL_ 1962 HVP_shuntAsicTempStatus 1 "SHUNT_DATA_INVALID" 0 "SHUNT_DATA_NOT_AVAILABLE" 3 "SHUNT_DATA_STALE" 2 "SHUNT_DATA_VALID" ;
VAL_ 1962 HVP_shuntAuxCurrentStatus 1 "SHUNT_DATA_INVALID" 0 "SHUNT_DATA_NOT_AVAILABLE" 3 "SHUNT_DATA_STALE" 2 "SHUNT_DATA_VALID" ;
VAL_ 1962 HVP_shuntBarTempDbg -32768 "SHUNT_TEMPERATURE_SNA" ;
VAL_ 1962 HVP_shuntBarTempStatus 1 "SHUNT_DATA_INVALID" 0 "SHUNT_DATA_NOT_AVAILABLE" 3 "SHUNT_DATA_STALE" 2 "SHUNT_DATA_VALID" ;
VAL_ 819 UI_acChargeCurrentLimit 127 "SNA" ;
VAL_ 820 UI_limitMode 2 "LIMIT_FACTORY" 0 "LIMIT_NORMAL" 3 "LIMIT_SERVICE" 1 "LIMIT_VALET" ;
VAL_ 820 UI_motorOnMode 1 "MOTORONMODE_FRONT_ONLY" 0 "MOTORONMODE_NORMAL" 2 "MOTORONMODE_REAR_ONLY" ;
VAL_ 820 UI_pedalMap 0 "CHILL" 2 "PERFORMANCE" 1 "SPORT" ;
VAL_ 820 UI_speedLimit 255 "SNA" ;
VAL_ 820 UI_stoppingMode 1 "CREEP" 2 "HOLD" 0 "STANDARD" ;
VAL_ 820 UI_systemPowerLimit 31 "SNA" ;
VAL_ 820 UI_systemTorqueLimit 63 "SNA" ;
VAL_ 820 UI_wasteMode 2 "WASTE_TYPE_FULL" 0 "WASTE_TYPE_NONE" 1 "WASTE_TYPE_PARTIAL" ;
VAL_ 820 UI_wasteModeRegenLimit 3 "MAX_REGEN_CURRENT_0A" 2 "MAX_REGEN_CURRENT_10A" 1 "MAX_REGEN_CURRENT_30A" 0 "MAX_REGEN_CURRENT_MAX" ;
VAL_ 820 UI_closureConfirmed 1 "CONFIRMED_FRUNK" 0 "CONFIRMED_NONE" 2 "CONFIRMED_PROX" ;
VAL_ 577 VCFRONT_coolantAirPurgeBatState 1 "AIR_PURGE_STATE_ACTIVE" 2 "AIR_PURGE_STATE_COMPLETE" 0 "AIR_PURGE_STATE_INACTIVE" 3 "AIR_PURGE_STATE_INTERRUPTED" 4 "AIR_PURGE_STATE_PENDING" ;
VAL_ 577 VCFRONT_coolantFlowBatReason 4 "ACTIVE_MANAGER_BATT" 9 "ACTIVE_MANAGER_PT" 6 "BMS_FLOW_REQ" 1 "COOLANT_AIR_PURGE" 7 "DAS_FLOW_REQ" 13 "DIS_FLOW_REQ" 12 "DI_FLOW_REQ" 14 "HP_FLOW_REQ" 0 "NONE" 2 "NO_FLOW_REQ" 3 "OVERRIDE_BATT" 8 "OVERRIDE_PT" 5 "PASSIVE_MANAGER_BATT" 10 "PASSIVE_MANAGER_PT" 11 "PCS_FLOW_REQ" ;
VAL_ 577 VCFRONT_coolantFlowPTReason 4 "ACTIVE_MANAGER_BATT" 9 "ACTIVE_MANAGER_PT" 6 "BMS_FLOW_REQ" 1 "COOLANT_AIR_PURGE" 7 "DAS_FLOW_REQ" 13 "DIS_FLOW_REQ" 12 "DI_FLOW_REQ" 14 "HP_FLOW_REQ" 0 "NONE" 2 "NO_FLOW_REQ" 3 "OVERRIDE_BATT" 8 "OVERRIDE_PT" 5 "PASSIVE_MANAGER_BATT" 10 "PASSIVE_MANAGER_PT" 11 "PCS_FLOW_REQ" ;
VAL_ 577 VCFRONT_wasteHeatRequestType 2 "WASTE_TYPE_FULL" 0 "WASTE_TYPE_NONE" 1 "WASTE_TYPE_PARTIAL" ;
